VERSION "dbc-export 1 2025.20.8"

NS_ :

BS_:

BU_: ADSP APB APP APS APSB BB BMS CC CMP CP DAS DI DIF DIR DPB EPAS3P EPAS3S EPASTP EPASTS EPBL EPBR ESP GTW HVP IBST ICR IDB OCS1P PCS PM PMF PMR PTC RCM RCM2 RCU SCCM SDCR TAS TCU TRCM UI UIS UMC USM VC VCFRONT VCLEFT VCRIGHT VCSEC

BO_ 946 BMS_log2: 8 BMS
 SG_ BMS_log2MuxId M : 0|7@1+ (1,0) [0|127] "" Vector__XXX
 SG_ BMS_cacAvg m0 : 8|13@1+ (0.1,0) [0|819.1] "Ah" Vector__XXX
 SG_ BMS_cacMin m0 : 24|13@1+ (0.1,0) [0|819.1] "Ah" Vector__XXX
 SG_ BMS_cacMinBrickId m0 : 37|7@1+ (1,1) [1|128] "" Vector__XXX
 SG_ BMS_cacMax m0 : 44|13@1+ (0.1,0) [0|819.1] "Ah" Vector__XXX
 SG_ BMS_cacMaxBrickId m0 : 57|7@1+ (1,1) [1|128] "" Vector__XXX
 SG_ BMS_acRippleConfigNvramValid m18 : 7|1@1+ (1,0) [0|1] "" Vector__XXX
 SG_ BMS_hvChain_useLeakyBucket m18 : 8|1@1+ (1,0) [0|1] "" Vector__XXX
 SG_ BMS_hvChain_iLimit m18 : 9|14@1+ (0.2,0) [0|3275] "A" Vector__XXX
 SG_ BMS_hvChain_limitingState m18 : 23|9@1+ (1,1) [1|511] "" Vector__XXX
 SG_ BMS_hvChain_limitingStateTempera m18 : 32|13@1- (0.1,367.6) [-40|775] "DegC" Vector__XXX
 SG_ BMS_acRippleIsSupported m18 : 45|1@1+ (1,0) [0|1] "" Vector__XXX
 SG_ BMS_acRippleStartTemperatureMax m18 : 46|9@1+ (0.25,-25) [-25|100] "DegC" Vector__XXX
 SG_ BMS_acRippleStartTemperatureMin m18 : 55|9@1+ (0.25,-25) [-25|100] "DegC" Vector__XXX
 SG_ BMS_fcLinkTestDecayTime m20 : 8|10@1+ (2,0) [0|2044] "mS" Vector__XXX
 SG_ BMS_fcLinkTestTimeSinceLastRun m20 : 18|12@1+ (0.0175824183971,0) [0|71.99] "Hours" Vector__XXX
 SG_ BMS_pcsPrechargeRequestActive m20 : 30|1@1+ (1,0) [0|1] "" Vector__XXX
 SG_ BMS_pcsPrechargeTargetVoltage m20 : 32|16@1- (0.1,0) [-3276.8|3276.7] "V" Vector__XXX
 SG_ BMS_recentOvUvAlert m20 : 48|1@1+ (1,0) [0|1] "" Vector__XXX
 SG_ BMS_recentIsoAlert m20 : 49|1@1+ (1,0) [0|1] "" Vector__XXX
 SG_ BMS_recentBmbMiaAlert m20 : 50|1@1+ (1,0) [0|1] "" Vector__XXX
 SG_ BMS_cacBlendingConfigNvramValid m20 : 51|1@1+ (1,0) [0|1] "" Vector__XXX
 SG_ BMS_cacBlendingEnabled m20 : 52|1@1+ (1,0) [0|1] "" Vector__XXX
 SG_ BMS_cacBlendPercentPerCycle m20 : 53|10@1+ (0.001,0) [0|1.023] "%" Vector__XXX
 SG_ BMS_energyVariableChgRequested m21 : 8|1@1+ (1,0) [0|1] "" Vector__XXX
 SG_ BMS_packRestTime m21 : 9|12@1+ (0.0175824183971,0) [0|71.99] "Hours" Vector__XXX
 SG_ BMS_idealEnergyFloor m21 : 21|10@1+ (0.1,0) [0|102.2] "KWh" Vector__XXX
 SG_ BMS_thmGradientSlopeCondition m21 : 31|1@1+ (1,0) [0|1] "" Vector__XXX
 SG_ BMS_recentSlopeConditon m21 : 32|1@1+ (1,0) [0|1] "" Vector__XXX
 SG_ BMS_dynamicEnergyBuffer m21 : 33|10@1+ (0.1,0) [0|102.2] "KWh" Vector__XXX
 SG_ BMS_temperatureCondition m21 : 43|1@1+ (1,0) [0|1] "" Vector__XXX
 SG_ BMS_thmGradientSlope m21 : 44|10@1- (0.01,0) [-5.12|5.11] "C/min" Vector__XXX
 SG_ BMS_thmGradient m21 : 56|8@1+ (0.1,0) [0|25.5] "C" Vector__XXX
 SG_ BMS_dSocNormalizedMin m33 : 8|12@1+ (0.0030517578125,-12.4969482422) [-12.4969482422|-0.003051757825] "%" Vector__XXX
 SG_ BMS_dSocNormalizedFiltMin m33 : 20|12@1+ (0.0030517578125,-12.4969482422) [-12.4969482422|-0.003051757825] "%" Vector__XXX
 SG_ BMS_dSocMinAlpha m33 : 32|12@1+ (0.0030517578125,-12.4969482422) [-12.4969482422|-0.003051757825] "%" Vector__XXX
 SG_ BMS_dSocMaxLowAlphaCounter m33 : 44|4@1+ (1,0) [0|15] "" Vector__XXX
 SG_ BMS_dSocMinAlphaBrickID m33 : 48|7@1+ (1,1) [1|128] "" Vector__XXX
 SG_ BMS_dSocCacMargin m33 : 55|9@1+ (0.0030517578125,0) [0|1.55639648438] "%" Vector__XXX
 SG_ BMS_lifeModelAvgTempSeverity m55 : 8|5@1+ (0.1,0) [0|3] "-" Vector__XXX
 SG_ BMS_lifeModelDepthOfDischargeSev m55 : 16|8@1+ (0.01,0) [0|1.5] "-" Vector__XXX
 SG_ BMS_lifeModelHistogramCapacityLo m55 : 24|9@1+ (0.1,0) [0|51] "%" Vector__XXX
 SG_ BMS_lifeModelHistogramBrickCapac m55 : 33|13@1+ (0.1,0) [0|819] "Ah" Vector__XXX
 SG_ BMS_lifeModelDcrGrowthPercent m55 : 48|14@1- (0.1,200) [-100|500] "%" Vector__XXX
 SG_ BMS_nominalFullPackEnergyRaw m56 : 8|16@1+ (0.02,0) [0|1310.68] "kWh" Vector__XXX
 SG_ BMS_userChargeCalibratingReason m56 : 24|2@1+ (1,0) [0|3] "" Vector__XXX
 SG_ BMS_nominalEnergyRemainingBuffer m56 : 32|16@1+ (0.02,0) [0|1310.68] "kWh" Vector__XXX
 SG_ BMS_idealEnergyRemainingBuffered m56 : 48|16@1+ (0.02,0) [0|1310.68] "kWh" Vector__XXX
 SG_ BMS_largestCacSpreadErrorLower m64 : 8|12@1+ (0.1,0) [0|409.4] "Ah" Vector__XXX
 SG_ BMS_lifeModelAverageCac m64 : 20|12@1+ (0.1,0) [0|409.4] "Ah" Vector__XXX
 SG_ BMS_lifeModelCacBrick1 m64 : 32|12@1+ (0.1,0) [0|409.4] "Ah" Vector__XXX
 SG_ BMS_lifeModelAverageOffset m64 : 44|10@1- (0.1,0) [-51.1|51.1] "Ah" Vector__XXX
 SG_ BMS_percentCacUpdatesInTimeWindo m64 : 54|10@1+ (0.1,0) [0|100] "%" Vector__XXX
 SG_ BMS_lifeModelMaxCacBrickId m65 : 8|8@1+ (1,1) [1|255] "" Vector__XXX
 SG_ BMS_lifeModelMaxCac m65 : 16|12@1+ (0.1,0) [0|409.4] "Ah" Vector__XXX
 SG_ BMS_lifeModelMinCacBrickId m65 : 28|8@1+ (1,1) [1|255] "" Vector__XXX
 SG_ BMS_lifeModelMinCac m65 : 36|12@1+ (0.1,0) [0|409.4] "Ah" Vector__XXX
 SG_ BMS_restingPointCacAvg m65 : 48|12@1+ (0.1,0) [0|409.4] "Ah" Vector__XXX
 SG_ BMS_cacEstimationSource m65 : 60|2@1+ (1,0) [0|3] "" Vector__XXX
 SG_ BMS_synchronizedCacMaxRaw m71 : 8|12@1+ (0.1,0) [0|409.4] "Ah" Vector__XXX
 SG_ BMS_synchronizedCacMinRaw m71 : 20|12@1+ (0.1,0) [0|409.4] "Ah" Vector__XXX
 SG_ BMS_largestSyncCacErrorStartSoc m71 : 32|10@1+ (0.1,0) [0|102.2] "%" Vector__XXX
 SG_ BMS_largestSyncCacErrorEndSoc m71 : 42|10@1+ (0.1,0) [0|102.2] "%" Vector__XXX
 SG_ BMS_runtimeSocConfigNvramValid m71 : 52|1@1+ (1,0) [0|1] "" Vector__XXX
 SG_ BMS_runtimeSocCorrectionsEnabled m71 : 53|1@1+ (1,0) [0|1] "" Vector__XXX
 SG_ BMS_rubberBandingEnabled m71 : 54|1@1+ (1,0) [0|1] "" Vector__XXX
 SG_ BMS_rubberBandingConfigNvramVali m71 : 55|1@1+ (1,0) [0|1] "" Vector__XXX
 SG_ BMS_runtimeSocMinTempForModel m71 : 56|6@1+ (0.5,0) [0|20] "DegC" Vector__XXX
 SG_ BMS_energyBufferConfigNvramValid m71 : 62|1@1+ (1,0) [0|1] "" Vector__XXX
 SG_ BMS_thermalEvent1pDetectConfigDi m71 : 63|1@1+ (1,0) [0|1] "" Vector__XXX
 SG_ BMS_sohEnergy m79 : 8|11@1+ (0.1,0) [0|204.6] "KWh" Vector__XXX
 SG_ BMS_fullCapacitySohEnergy m79 : 19|11@1+ (0.1,0) [0|204.6] "KWh" Vector__XXX
 SG_ BMS_calibratedCapacitySohEnergy m79 : 30|11@1+ (0.1,0) [0|204.6] "KWh" Vector__XXX
 SG_ BMS_estimatedCapacitySohEnergy m79 : 41|11@1+ (0.1,0) [0|204.6] "KWh" Vector__XXX
 SG_ BMS_prevUserFacingSohEnergy m79 : 52|11@1+ (0.1,0) [0|204.6] "KWh" Vector__XXX
 SG_ BMS_stateOfHealthMinCac m80 : 8|13@1+ (0.1,0) [0|819] "Ah" Vector__XXX
 SG_ BMS_lifeModelStorageLossPackAge m80 : 24|14@1+ (1,0) [0|16382] "days" Vector__XXX
 SG_ BMS_lifeModelThroughputCycleCoun m80 : 40|12@1+ (1,0) [0|4094] "Cycles" Vector__XXX
 SG_ BMS_lifeModelThroughputDcrCycleC m80 : 52|12@1+ (1,0) [0|4094] "Cycles" Vector__XXX
 SG_ BMS_energyWalkCounter m83 : 8|8@1+ (1,0) [0|255] "" Vector__XXX
 SG_ BMS_energyWalkTimeoutCounter m83 : 16|8@1+ (1,0) [0|255] "" Vector__XXX
 SG_ BMS_dynamicCcvEnabled m83 : 24|1@1+ (1,0) [0|1] "" Vector__XXX
 SG_ BMS_chargeTargetLookupSoc m83 : 32|10@1+ (0.1,0) [0|102.2] "%" Vector__XXX
 SG_ BMS_stateOfHealth m83 : 42|10@1+ (0.1,0) [0|100] "%" Vector__XXX

BO_ 914 BMS_packConfig: 8 BMS
 SG_ BMS_packConfigMultiplexer M : 0|8@1+ (1,0) [0|255] "" Vector__XXX
 SG_ BMS_reservedConfig_0 m0 : 8|5@1+ (1,0) [0|31] "" Vector__XXX
 SG_ BMS_moduleType m1 : 8|3@1+ (1,0) [0|7] "" Vector__XXX
 SG_ BMS_thermalPackType m1 : 11|4@1+ (1,0) [0|15] "" Vector__XXX
 SG_ BMS_packMass m1 : 16|8@1+ (1,300) [342|540] "kg" Vector__XXX
 SG_ BMS_platformMaxBusVoltage m1 : 24|10@1+ (1,300) [300|1300] "V" Vector__XXX
 SG_ BMS_standbySupplyContinuousPower m1 : 36|2@1+ (1,0) [0|3] "" Vector__XXX

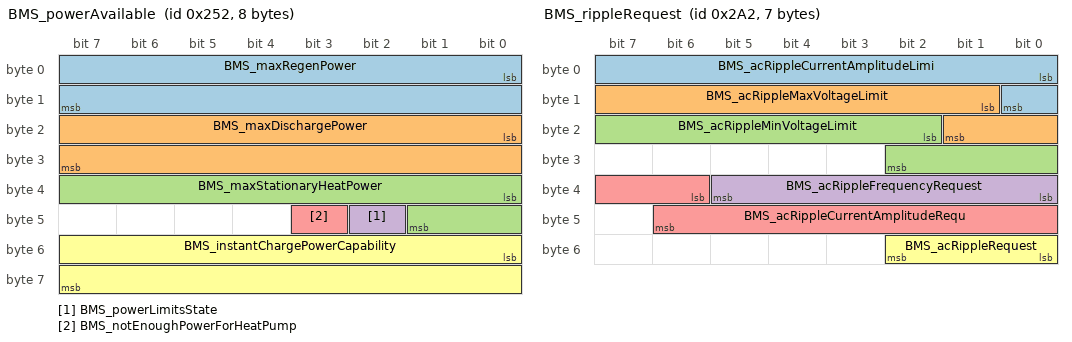
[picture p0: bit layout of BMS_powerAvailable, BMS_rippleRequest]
BO_ 594 BMS_powerAvailable: 8 BMS
 SG_ BMS_maxRegenPower : 0|16@1+ (0.01,0) [0|655.35] "kW" Vector__XXX
 SG_ BMS_maxDischargePower : 16|16@1+ (0.013,0) [0|850] "kW" Vector__XXX
 SG_ BMS_maxStationaryHeatPower : 32|10@1+ (0.01,0) [0|10.23] "kW" Vector__XXX
 SG_ BMS_powerLimitsState : 42|1@1+ (1,0) [0|1] "" Vector__XXX
 SG_ BMS_notEnoughPowerForHeatPump : 43|1@1+ (1,0) [0|1] "" Vector__XXX
 SG_ BMS_instantChargePowerCapability : 48|16@1+ (0.05,0) [0|3276.7] "kW" Vector__XXX

BO_ 674 BMS_rippleRequest: 7 BMS
 SG_ BMS_acRippleCurrentAmplitudeLimi : 0|9@1+ (1,0) [0|511] "A" Vector__XXX
 SG_ BMS_acRippleMaxVoltageLimit : 9|9@1+ (1,0) [0|511] "V" Vector__XXX
 SG_ BMS_acRippleMinVoltageLimit : 18|9@1+ (1,0) [0|511] "V" Vector__XXX
 SG_ BMS_acRippleFrequencyRequest : 32|6@1+ (1,80) [80|142] "Hz" Vector__XXX
 SG_ BMS_acRippleCurrentAmplitudeRequ : 38|9@1+ (1,0) [0|511] "A" Vector__XXX
 SG_ BMS_acRippleRequest : 48|3@1+ (1,0) [0|7] "" Vector__XXX

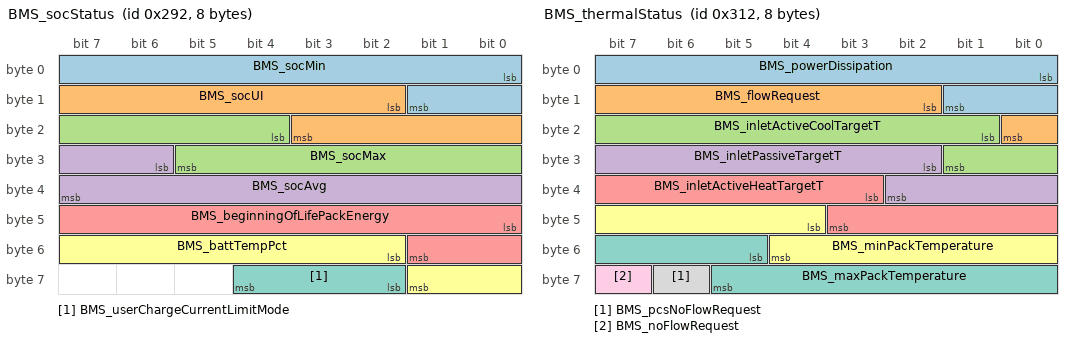
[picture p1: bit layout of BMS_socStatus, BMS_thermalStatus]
BO_ 658 BMS_socStatus: 8 BMS
 SG_ BMS_socMin : 0|10@1+ (0.1,0) [0|102.2] "%" Vector__XXX
 SG_ BMS_socUI : 10|10@1+ (0.1,0) [0|100] "%" Vector__XXX
 SG_ BMS_socMax : 20|10@1+ (0.1,0) [0|102.2] "%" Vector__XXX
 SG_ BMS_socAvg : 30|10@1+ (0.1,0) [0|102.2] "%" Vector__XXX
 SG_ BMS_beginningOfLifePackEnergy : 40|10@1+ (0.1,0) [0|102.2] "KWh" Vector__XXX
 SG_ BMS_battTempPct : 50|8@1+ (0.4,0) [0|100] "%" Vector__XXX
 SG_ BMS_userChargeCurrentLimitMode : 58|3@1+ (1,0) [0|7] "" Vector__XXX

BO_ 530 BMS_status: 8 BMS
 SG_ BMS_hvacPowerRequest : 0|1@1+ (1,0) [0|1] "" Vector__XXX
 SG_ BMS_notEnoughPowerForDrive : 1|1@1+ (1,0) [0|1] "" Vector__XXX
 SG_ BMS_notEnoughPowerForSupport : 2|1@1+ (1,0) [0|1] "" Vector__XXX
 SG_ BMS_preconditionAllowed : 3|1@1+ (1,0) [0|1] "" Vector__XXX
 SG_ BMS_updateAllowed : 4|1@1+ (1,0) [0|1] "" Vector__XXX
 SG_ BMS_activeHeatingWorthwhile : 5|1@1+ (1,0) [0|1] "" Vector__XXX
 SG_ BMS_cpMiaOnHvs : 6|1@1+ (1,0) [0|1] "" Vector__XXX
 SG_ BMS_pcsPwmEnabled : 7|1@1+ (1,0) [0|1] "" Vector__XXX
 SG_ BMS_contactorState : 8|3@1+ (1,0) [1|7] "" Vector__XXX
 SG_ BMS_userChargeStatus : 11|3@1+ (1,0) [0|7] "" Vector__XXX
 SG_ BMS_totalBatteryPower : 14|17@1- (0.05,0) [-3276.8|3276.75] "kW" Vector__XXX
 SG_ BMS_chargeRequest : 31|1@1+ (1,0) [0|1] "" Vector__XXX
 SG_ BMS_state : 32|4@1+ (1,0) [0|15] "" Vector__XXX
 SG_ BMS_diLimpRequest : 37|1@1+ (1,0) [0|1] "" Vector__XXX
 SG_ BMS_okToShipByAir : 38|1@1+ (1,0) [0|1] "" Vector__XXX
 SG_ BMS_okToShipByLand : 39|1@1+ (1,0) [0|1] "" Vector__XXX
 SG_ BMS_chgPowerAvailable : 40|12@1+ (0.125,0) [0|511.75] "kW" Vector__XXX
 SG_ BMS_chargeRetryCount : 53|3@1+ (1,0) [0|7] "" Vector__XXX
 SG_ BMS_conditioningRequest : 56|1@1+ (1,0) [0|1] "" Vector__XXX
 SG_ BMS_smStateRequest : 57|4@1+ (1,0) [0|15] "" Vector__XXX
 SG_ BMS_hvState : 61|3@1+ (1,0) [0|7] "" Vector__XXX

BO_ 786 BMS_thermalStatus: 8 BMS
 SG_ BMS_powerDissipation : 0|10@1+ (0.02,0) [0|20] "kW" Vector__XXX
 SG_ BMS_flowRequest : 10|7@1+ (0.3,0) [0|38.1] "LPM" Vector__XXX
 SG_ BMS_inletActiveCoolTargetT : 17|9@1+ (0.25,-25) [-25|100] "DegC" Vector__XXX
 SG_ BMS_inletPassiveTargetT : 26|9@1+ (0.25,-25) [-25|100] "DegC" Vector__XXX
 SG_ BMS_inletActiveHeatTargetT : 35|9@1+ (0.25,-25) [-25|100] "DegC" Vector__XXX
 SG_ BMS_minPackTemperature : 44|9@1+ (0.25,-25) [-25|102.75] "DegC" Vector__XXX
 SG_ BMS_maxPackTemperature : 53|9@1+ (0.25,-25) [-25|102.75] "DegC" Vector__XXX
 SG_ BMS_pcsNoFlowRequest : 62|1@1+ (1,0) [0|1] "" Vector__XXX
 SG_ BMS_noFlowRequest : 63|1@1+ (1,0) [0|1] "" Vector__XXX

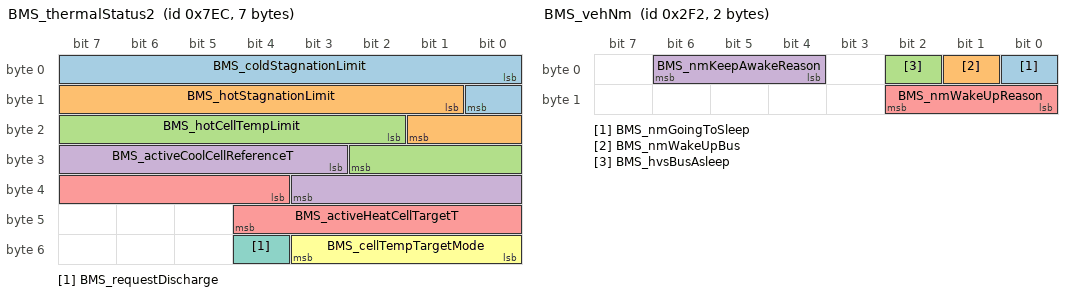
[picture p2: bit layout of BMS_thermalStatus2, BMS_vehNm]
BO_ 2028 BMS_thermalStatus2: 7 BMS
 SG_ BMS_coldStagnationLimit : 0|9@1+ (0.25,-25) [-25|100] "DegC" Vector__XXX
 SG_ BMS_hotStagnationLimit : 9|9@1+ (0.25,-25) [-25|100] "DegC" Vector__XXX
 SG_ BMS_hotCellTempLimit : 18|9@1+ (0.25,-25) [-25|100] "DegC" Vector__XXX
 SG_ BMS_activeCoolCellReferenceT : 27|9@1+ (0.25,-25) [-25|100] "DegC" Vector__XXX
 SG_ BMS_activeHeatCellTargetT : 36|9@1+ (0.25,-25) [-25|100] "DegC" Vector__XXX
 SG_ BMS_cellTempTargetMode : 48|4@1+ (1,0) [0|15] "" Vector__XXX
 SG_ BMS_requestDischarge : 52|1@1+ (1,0) [0|1] "" Vector__XXX

BO_ 754 BMS_vehNm: 2 BMS
 SG_ BMS_nmGoingToSleep : 0|1@1+ (1,0) [0|1] "" Vector__XXX
 SG_ BMS_nmWakeUpBus : 1|1@1+ (1,0) [0|1] "" Vector__XXX
 SG_ BMS_hvsBusAsleep : 2|1@1+ (1,0) [0|1] "" Vector__XXX
 SG_ BMS_nmKeepAwakeReason : 4|3@1+ (1,0) [1|7] "" Vector__XXX
 SG_ BMS_nmWakeUpReason : 8|3@1+ (1,0) [0|7] "" Vector__XXX

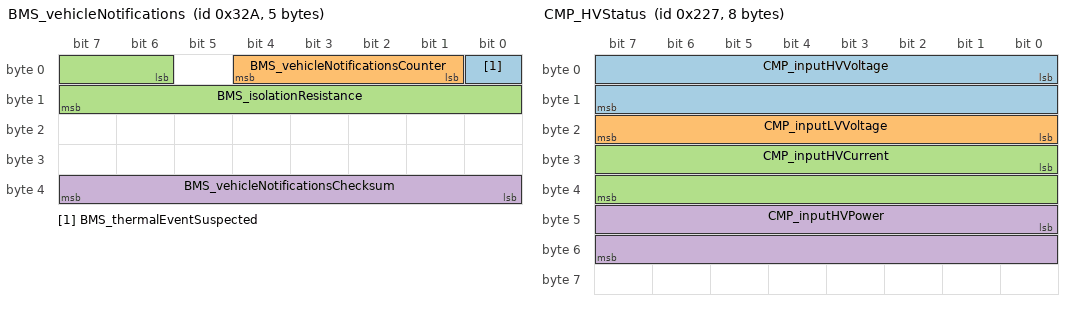
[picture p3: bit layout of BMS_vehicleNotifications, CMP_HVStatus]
BO_ 810 BMS_vehicleNotifications: 5 BMS
 SG_ BMS_thermalEventSuspected : 0|1@1+ (1,0) [0|1] "" Vector__XXX
 SG_ BMS_vehicleNotificationsCounter : 1|4@1+ (1,0) [0|15] "" Vector__XXX
 SG_ BMS_isolationResistance : 6|10@1+ (10,0) [0|10000] "kOhm" Vector__XXX
 SG_ BMS_vehicleNotificationsChecksum : 32|8@1+ (1,0) [0|255] "" Vector__XXX

BO_ 797 CC_chgStatus2: 8 CC
 SG_ CC_chgStatus2Index M : 0|8@1+ (1,0) [0|255] "" Vector__XXX
 SG_ CC_buttonState m0 : 8|1@1+ (1,0) [0|1] "" Vector__XXX

BO_ 551 CMP_HVStatus: 8 CMP
 SG_ CMP_inputHVVoltage : 0|16@1+ (0.1,0) [0|6553.4] "V" Vector__XXX
 SG_ CMP_inputLVVoltage : 16|8@1+ (0.1,0) [0|25.5] "V" Vector__XXX
 SG_ CMP_inputHVCurrent : 24|16@1+ (0.1,0) [0|6553.4] "A" Vector__XXX
 SG_ CMP_inputHVPower : 40|16@1+ (1,0) [0|65534] "W" Vector__XXX

BO_ 1294 CP_alertLog: 8 CP
 SG_ CP_alertID M : 0|15@1+ (1,0) [0|32767] "" Vector__XXX
 SG_ CP_alertType : 15|1@1+ (1,0) [0|1] "" Vector__XXX
 SG_ CP_a004_proximityV m4 : 16|16@1+ (0.0001,0) [0|6.5535] "V" Vector__XXX
 SG_ CP_a004_cc1Voltage m4 : 32|14@1+ (0.001,0) [0|16.383] "V" Vector__XXX
 SG_ CP_a004_cc2Voltage m4 : 48|14@1+ (0.001,0) [0|16.383] "V" Vector__XXX
 SG_ CP_a005_cc1Voltage m5 : 16|11@1+ (0.00649731326848,0) [0|13.3000002606] "V" Vector__XXX
 SG_ CP_a005_cc2Voltage m5 : 27|9@1+ (0.009784736,0) [0|5.000000096] "V" Vector__XXX
 SG_ CP_a005_gbdcState m5 : 36|4@1+ (1,0) [0|15] "" Vector__XXX
 SG_ CP_a005_packCurrent m5 : 40|12@1+ (0.0976801,0) [0|400.0000095] "A" Vector__XXX
 SG_ CP_a005_evseCurrent m5 : 52|10@1+ (0.391006857157,0) [0|400.000014872] "A" Vector__XXX
 SG_ CP_a005_superchargerConnected m5 : 62|1@1+ (1,0) [0|1] "" Vector__XXX
 SG_ CP_a005_latchEngaged m5 : 63|1@1+ (1,0) [0|1] "" Vector__XXX
 SG_ CP_a006_BMS_FC_limits_MIA m6 : 16|1@1+ (1,0) [0|1] "" Vector__XXX
 SG_ CP_a006_BMS_chargeStatus_MIA m6 : 17|1@1+ (1,0) [0|1] "" Vector__XXX
 SG_ CP_a006_BMS_dcChargeLimits_MIA m6 : 18|1@1+ (1,0) [0|1] "" Vector__XXX
 SG_ CP_a006_BMS_hvPackStatus_MIA m6 : 19|1@1+ (1,0) [0|1] "" Vector__XXX
 SG_ CP_a006_BMS_kwhCounter_MIA m6 : 20|1@1+ (1,0) [0|1] "" Vector__XXX
 SG_ CP_a006_BMS_socStatus_MIA m6 : 21|1@1+ (1,0) [0|1] "" Vector__XXX
 SG_ CP_a008_data1 m8 : 16|16@1+ (1,0) [0|65535] "" Vector__XXX
 SG_ CP_a008_data2 m8 : 32|16@1+ (1,0) [0|65535] "" Vector__XXX
 SG_ CP_a008_FlashWarning m8 : 48|1@1+ (1,0) [0|1] "" Vector__XXX
 SG_ CP_a008_RAMconst_Warning m8 : 49|1@1+ (1,0) [0|1] "" Vector__XXX
 SG_ CP_a008_RAMconst_Fault m8 : 50|1@1+ (1,0) [0|1] "" Vector__XXX
 SG_ CP_a008_AllMemory_warnings m8 : 51|1@1+ (1,0) [0|1] "" Vector__XXX
 SG_ CP_a008_StackAlert m8 : 52|1@1+ (1,0) [0|1] "" Vector__XXX
 SG_ CP_a008_stackUsed m8 : 56|7@1+ (1,0) [0|127] "%" Vector__XXX
 SG_ CP_a009_cover1OpenCounts m9 : 16|12@1+ (0.025,0) [0|102.375] "%" Vector__XXX
 SG_ CP_a009_cover2OpenCounts m9 : 28|12@1+ (0.025,0) [0|102.375] "%" Vector__XXX
 SG_ CP_a009_cover1State m9 : 40|3@1+ (1,0) [0|7] "" Vector__XXX
 SG_ CP_a009_cover2State m9 : 43|3@1+ (1,0) [0|7] "" Vector__XXX
 SG_ CP_a010_periodValid m10 : 16|1@1+ (1,0) [0|1] "" Vector__XXX
 SG_ CP_a010_widthValid m10 : 17|1@1+ (1,0) [0|1] "" Vector__XXX
 SG_ CP_a010_voltageValid m10 : 18|1@1+ (1,0) [0|1] "" Vector__XXX
 SG_ CP_a010_pilotHigh m10 : 19|12@1- (0.008,0) [-16.384|16.376] "V" Vector__XXX
 SG_ CP_a010_pilotLow m10 : 32|12@1- (0.008,0) [-16.384|16.376] "V" Vector__XXX
 SG_ CP_a010_evseAccept m10 : 44|1@1+ (1,0) [0|1] "" Vector__XXX
 SG_ CP_a010_pilotPWMdetected m10 : 45|1@1+ (1,0) [0|1] "" Vector__XXX
 SG_ CP_a011_eepromErrorType m11 : 16|3@1+ (1,0) [0|7] "" Vector__XXX
 SG_ CP_a015_apsVoltageOV m15 : 16|8@1+ (0.07128516,0) [0|18.1777158] "V" Vector__XXX
 SG_ CP_a016_apsVoltageUV m16 : 16|8@1+ (0.07128516,0) [0|18.1777158] "V" Vector__XXX
 SG_ CP_a017_5V_VoltageOV m17 : 16|8@1+ (0.02352539,0) [0|5.99897445] "V" Vector__XXX
 SG_ CP_a018_5V_VoltageUV m18 : 16|8@1+ (0.02352539,0) [0|5.99897445] "V" Vector__XXX
 SG_ CP_a023_stopChargeReason m23 : 16|4@1+ (1,0) [0|15] "" Vector__XXX
 SG_ CP_a023_failureReason m23 : 20|2@1+ (1,0) [0|3] "" Vector__XXX
 SG_ CP_a023_chargeAttempts m23 : 24|3@1+ (1,0) [0|7] "" Vector__XXX
 SG_ CP_a028_canEnable m28 : 16|1@1+ (1,0) [0|1] "" Vector__XXX
 SG_ CP_a028_hardlineEnable m28 : 17|1@1+ (1,0) [0|1] "" Vector__XXX
 SG_ CP_a029_CP_pilot m29 : 16|3@1+ (1,0) [0|6] "" Vector__XXX
 SG_ CP_a029_CP_proximity m29 : 19|2@1+ (1,0) [1|3] "" Vector__XXX
 SG_ CP_a029_CP_chargeDoorOpen m29 : 21|1@1+ (1,0) [0|1] "" Vector__XXX
 SG_ CP_a031_apsVoltage m31 : 16|8@1+ (0.07156863,0) [0|18.25000065] "V" Vector__XXX
 SG_ CP_a031_doorCountsFiltered m31 : 24|12@1+ (0.025,0) [0|102.375] "%" Vector__XXX
 SG_ CP_a031_inductiveSensorFiltered m31 : 36|18@1+ (82.77924,0) [0|21699998.3113] "Hz" Vector__XXX
 SG_ CP_a031_hallSensorFiltered m31 : 54|10@1+ (0.00488748773932,0) [0|4.99989995732] "V" Vector__XXX
 SG_ CP_a032_apsVoltage m32 : 16|8@1+ (0.07156863,0) [0|18.25000065] "V" Vector__XXX
 SG_ CP_a032_doorCountsFiltered m32 : 24|12@1+ (0.025,0) [0|102.375] "%" Vector__XXX
 SG_ CP_a032_inductiveSensorFiltered m32 : 36|18@1+ (82.77924,0) [0|21699998.3113] "Hz" Vector__XXX
 SG_ CP_a032_hallSensorFiltered m32 : 54|10@1+ (0.00488748773932,0) [0|4.99989995732] "V" Vector__XXX
 SG_ CP_a035_latchState m35 : 16|2@1+ (1,0) [1|3] "" Vector__XXX
 SG_ CP_a035_stateLeverMovedFrom m35 : 18|2@1+ (1,0) [0|3] "" Vector__XXX
 SG_ CP_a035_latchOffset m35 : 24|16@1- (0.003051851,0) [-100.003053568|100.000001717] "%" Vector__XXX
 SG_ CP_a035_inletID m35 : 40|2@1+ (1,0) [0|3] "" Vector__XXX
 SG_ CP_a036_latchCountsFiltered m36 : 16|16@1+ (0.00152590218931,0) [0|99.9999999764] "%" Vector__XXX
 SG_ CP_a036_latchState m36 : 32|2@1+ (1,0) [1|3] "" Vector__XXX
 SG_ CP_a036_CHG_InsertEnable m36 : 34|1@1+ (1,0) [0|1] "" Vector__XXX
 SG_ CP_a036_CP_latchEnableCmd m36 : 35|1@1+ (1,0) [0|1] "" Vector__XXX
 SG_ CP_a036_CP_apsVoltage m36 : 40|8@1+ (0.07156863,0) [0|18.25000065] "V" Vector__XXX
 SG_ CP_a036_inletID m36 : 48|2@1+ (1,0) [0|3] "" Vector__XXX
 SG_ CP_a037_latchCountsFiltered m37 : 16|16@1+ (0.00152590218931,0) [0|99.9999999764] "%" Vector__XXX
 SG_ CP_a037_latchState m37 : 32|2@1+ (1,0) [1|3] "" Vector__XXX
 SG_ CP_a037_CHG_InsertEnable m37 : 34|1@1+ (1,0) [0|1] "" Vector__XXX
 SG_ CP_a037_CP_latchEnableCmd m37 : 35|1@1+ (1,0) [0|1] "" Vector__XXX
 SG_ CP_a037_CP_apsVoltage m37 : 40|8@1+ (0.07156863,0) [0|18.25000065] "V" Vector__XXX
 SG_ CP_a037_inletID m37 : 48|2@1+ (1,0) [0|3] "" Vector__XXX
 SG_ CP_a038_latchCountsFiltered m38 : 16|16@1+ (0.00152590218931,0) [0|99.9999999764] "%" Vector__XXX
 SG_ CP_a038_latchState m38 : 32|2@1+ (1,0) [1|3] "" Vector__XXX
 SG_ CP_a038_CHG_InsertEnable m38 : 34|1@1+ (1,0) [0|1] "" Vector__XXX
 SG_ CP_a038_CP_latchEnableCmd m38 : 35|1@1+ (1,0) [0|1] "" Vector__XXX
 SG_ CP_a038_CP_apsVoltage m38 : 40|8@1+ (0.07156863,0) [0|18.25000065] "V" Vector__XXX
 SG_ CP_a038_inletID m38 : 48|2@1+ (1,0) [0|3] "" Vector__XXX
 SG_ CP_a041_doorCounts m41 : 16|16@1+ (0.002,0) [0|131.07] "%" Vector__XXX
 SG_ CP_a041_inductiveSensorFiltered m41 : 32|18@1+ (82.77924,0) [0|21699998.3113] "Hz" Vector__XXX
 SG_ CP_a041_hallSensorFiltered m41 : 50|10@1+ (0.00488748773932,0) [0|4.99989995732] "V" Vector__XXX
 SG_ CP_a042_doorCounts m42 : 16|16@1+ (0.002,0) [0|131.07] "%" Vector__XXX
 SG_ CP_a042_inductiveSensorFiltered m42 : 32|18@1+ (82.77924,0) [0|21699998.3113] "Hz" Vector__XXX
 SG_ CP_a042_hallSensorFiltered m42 : 50|10@1+ (0.00488748773932,0) [0|4.99989995732] "V" Vector__XXX
 SG_ CP_a043_driftFlag m43 : 16|1@1+ (1,0) [0|1] "" Vector__XXX
 SG_ CP_a043_wrongDirectionFlag m43 : 17|1@1+ (1,0) [0|1] "" Vector__XXX
 SG_ CP_a043_outOfRangeFlag m43 : 18|1@1+ (1,0) [0|1] "" Vector__XXX
 SG_ CP_a043_doorPotFiltered m43 : 19|12@1+ (0.025,0) [0|102.375] "%" Vector__XXX
 SG_ CP_a043_doorVelocity m43 : 32|12@1- (0.5,0) [-1024|1023.5] "%/s" Vector__XXX
 SG_ CP_a043_idleDoorPot m43 : 44|12@1+ (0.025,0) [0|102.375] "%" Vector__XXX
 SG_ CP_a044_HVP_cpControl_MIA m44 : 16|1@1+ (1,0) [0|1] "" Vector__XXX
 SG_ CP_a045_VCSEC_authentication_MIA m45 : 16|1@1+ (1,0) [0|1] "" Vector__XXX
 SG_ CP_a045_VCSEC_requests_MIA m45 : 17|1@1+ (1,0) [0|1] "" Vector__XXX
 SG_ CP_a046_FC_status_flag m46 : 16|1@1+ (1,0) [0|1] "" Vector__XXX
 SG_ CP_a046_FC_limits_flag m46 : 17|1@1+ (1,0) [0|1] "" Vector__XXX
 SG_ CP_a046_FC_maxLimits_flag m46 : 18|1@1+ (1,0) [0|1] "" Vector__XXX
 SG_ CP_a046_FC_statusHighPower_flag m46 : 19|1@1+ (1,0) [0|1] "" Vector__XXX
 SG_ CP_a046_FC_limitsHighPower_flag m46 : 20|1@1+ (1,0) [0|1] "" Vector__XXX
 SG_ CP_a046_FC_maxLimitsHighPower m46 : 21|1@1+ (1,0) [0|1] "" Vector__XXX
 SG_ CP_a046_CC_chgStatus_flag m46 : 22|1@1+ (1,0) [0|1] "" Vector__XXX
 SG_ CP_a047_okToUseHighPower_MIA m47 : 16|1@1+ (1,0) [0|1] "" Vector__XXX
 SG_ CP_a047_LVPowerState_MIA m47 : 17|1@1+ (1,0) [0|1] "" Vector__XXX
 SG_ CP_a047_sensors_MIA m47 : 18|1@1+ (1,0) [0|1] "" Vector__XXX
 SG_ CP_a047_vehNm_MIA m47 : 19|1@1+ (1,0) [0|1] "" Vector__XXX
 SG_ CP_a048_UI_chargeRequest_MIA m48 : 16|1@1+ (1,0) [0|1] "" Vector__XXX
 SG_ CP_a048_UI_range_MIA m48 : 17|1@1+ (1,0) [0|1] "" Vector__XXX
 SG_ CP_a048_UI_status_MIA m48 : 18|1@1+ (1,0) [0|1] "" Vector__XXX
 SG_ CP_a048_UI_vehicleModes_MIA m48 : 19|1@1+ (1,0) [0|1] "" Vector__XXX
 SG_ CP_a048_UI_hvacRequest_MIA m48 : 20|1@1+ (1,0) [0|1] "" Vector__XXX
 SG_ CP_a048_VEH_billing_MIA m48 : 21|1@1+ (1,0) [0|1] "" Vector__XXX
 SG_ CP_a049_proximity m49 : 16|2@1+ (1,0) [1|3] "" Vector__XXX
 SG_ CP_a050_latch1NotConnected m50 : 16|1@1+ (1,0) [0|1] "" Vector__XXX
 SG_ CP_a050_latch2NotConnected m50 : 17|1@1+ (1,0) [0|1] "" Vector__XXX
 SG_ CP_a051_doorCountsFiltered m51 : 16|12@1+ (0.025,0) [0|102.375] "%" Vector__XXX
 SG_ CP_a054_latchCountsFiltered m54 : 16|16@1+ (0.00152590218931,0) [0|99.9999999764] "%" Vector__XXX
 SG_ CP_a054_latchState m54 : 32|2@1+ (1,0) [1|3] "" Vector__XXX
 SG_ CP_a054_CHG_InsertEnable m54 : 34|1@1+ (1,0) [0|1] "" Vector__XXX
 SG_ CP_a054_CP_latchEnableCmd m54 : 35|1@1+ (1,0) [0|1] "" Vector__XXX
 SG_ CP_a054_CP_apsVoltage m54 : 40|8@1+ (0.07156863,0) [0|18.25000065] "V" Vector__XXX
 SG_ CP_a054_CP_proximity m54 : 48|2@1+ (1,0) [1|3] "" Vector__XXX
 SG_ CP_a054_inletID m54 : 50|2@1+ (1,0) [0|3] "" Vector__XXX
 SG_ CP_a056_latchState m56 : 16|2@1+ (1,0) [1|3] "" Vector__XXX
 SG_ CP_a056_CHG_InsertEnable m56 : 18|1@1+ (1,0) [0|1] "" Vector__XXX
 SG_ CP_a056_CP_latchEnableCmd m56 : 19|1@1+ (1,0) [0|1] "" Vector__XXX
 SG_ CP_a056_CP_proximity m56 : 20|2@1+ (1,0) [1|3] "" Vector__XXX
 SG_ CP_a056_packCurrent m56 : 24|16@1- (0.1,0) [-3276.8|3276.7] "A" Vector__XXX
 SG_ CP_a058_CP_pilot m58 : 16|3@1+ (1,0) [0|6] "" Vector__XXX
 SG_ CP_a058_CC_pilot m58 : 19|2@1+ (1,0) [0|2] "" Vector__XXX
 SG_ CP_a058_FC_status m58 : 24|4@1+ (1,0) [1|15] "" Vector__XXX
 SG_ CP_a058_latchState m58 : 28|2@1+ (1,0) [1|3] "" Vector__XXX
 SG_ CP_a058_CP_proximity m58 : 30|2@1+ (1,0) [1|3] "" Vector__XXX
 SG_ CP_a058_acNumRetries m58 : 32|1@1+ (1,0) [0|1] "" Vector__XXX
 SG_ CP_a058_acRetryTimeoutS m58 : 33|15@1+ (1,0) [0|32767] "" Vector__XXX
 SG_ CP_a060_PCS_chgStatus_MIA m60 : 16|1@1+ (1,0) [0|1] "" Vector__XXX
 SG_ CP_a060_PCS_chgLineStatus_MIA m60 : 17|1@1+ (1,0) [0|1] "" Vector__XXX
 SG_ CP_a061_controlState m61 : 16|4@1+ (1,0) [0|15] "" Vector__XXX
 SG_ CP_a061_lastControlState m61 : 20|4@1+ (1,0) [0|15] "" Vector__XXX
 SG_ CP_a061_chipState m61 : 24|3@1+ (1,0) [0|7] "" Vector__XXX
 SG_ CP_a061_timeMsInControlState m61 : 32|16@1+ (1,0) [0|65535] "" Vector__XXX
 SG_ CP_a062_FC_status m62 : 16|4@1+ (1,0) [1|15] "" Vector__XXX
 SG_ CP_a062_FC_type m62 : 20|3@1+ (1,0) [0|6] "" Vector__XXX
 SG_ CP_a063_FC_status m63 : 16|4@1+ (1,0) [1|15] "" Vector__XXX
 SG_ CP_a063_FC_type m63 : 20|3@1+ (1,0) [0|6] "" Vector__XXX
 SG_ CP_a066_pilotHigh m66 : 16|12@1- (0.008,0) [-16.384|16.376] "V" Vector__XXX
 SG_ CP_a066_pilotLow m66 : 28|12@1- (0.008,0) [-16.384|16.376] "V" Vector__XXX
 SG_ CP_a066_proximity m66 : 40|2@1+ (1,0) [1|3] "" Vector__XXX
 SG_ CP_a067_cc1Voltage m67 : 16|14@1+ (0.001,0) [0|16.383] "V" Vector__XXX
 SG_ CP_a067_cc2Voltage m67 : 32|14@1+ (0.001,0) [0|16.383] "V" Vector__XXX
 SG_ CP_a068_doorCountsFiltered m68 : 16|12@1+ (0.025,0) [0|102.375] "%" Vector__XXX
 SG_ CP_a068_doorClosed m68 : 28|1@1+ (1,0) [0|1] "" Vector__XXX
 SG_ CP_a068_inductiveSensorFiltered m68 : 29|18@1+ (82.77924,0) [0|21699998.3113] "Hz" Vector__XXX
 SG_ CP_a068_hallSensorFiltered m68 : 48|10@1+ (0.00488748773932,0) [0|4.99989995732] "V" Vector__XXX
 SG_ CP_a068_doorPresent m68 : 58|1@1+ (1,0) [0|1] "" Vector__XXX
 SG_ CP_a069_inductiveSensor_raw m69 : 16|28@1+ (1,0) [0|268435455] "" Vector__XXX
 SG_ CP_a069_inductiveErrorAmplitude m69 : 44|1@1+ (1,0) [0|1] "" Vector__XXX
 SG_ CP_a069_inductiveErrorWatchdog m69 : 45|1@1+ (1,0) [0|1] "" Vector__XXX
 SG_ CP_a069_inductiveErrorOverRange m69 : 46|1@1+ (1,0) [0|1] "" Vector__XXX
 SG_ CP_a069_inductiveErrorUnderRange m69 : 47|1@1+ (1,0) [0|1] "" Vector__XXX
 SG_ CP_a070_i2cIBCR m70 : 16|8@1+ (1,0) [0|255] "" Vector__XXX
 SG_ CP_a070_i2cIBSR m70 : 24|8@1+ (1,0) [0|255] "" Vector__XXX
 SG_ CP_a071_expectedMessage m71 : 16|4@1+ (1,0) [0|15] "" Vector__XXX
 SG_ CP_a072_currentMessage m72 : 16|4@1+ (1,0) [0|15] "" Vector__XXX
 SG_ CP_a072_readyToChargeExpired m72 : 20|1@1+ (1,0) [0|1] "" Vector__XXX
 SG_ CP_a072_commsSetupExpired m72 : 21|1@1+ (1,0) [0|1] "" Vector__XXX
 SG_ CP_a072_cableCheckExpired m72 : 22|1@1+ (1,0) [0|1] "" Vector__XXX
 SG_ CP_a072_preChargeExpired m72 : 23|1@1+ (1,0) [0|1] "" Vector__XXX
 SG_ CP_a073_ccsManagerState m73 : 16|3@1+ (1,0) [0|7] "" Vector__XXX
 SG_ CP_a073_ccsDcState m73 : 19|4@1+ (1,0) [0|15] "" Vector__XXX
 SG_ CP_a073_ccsShutdownReason m73 : 24|4@1+ (1,0) [0|15] "" Vector__XXX
 SG_ CP_a073_comboHandleNotPresent m73 : 28|1@1+ (1,0) [0|1] "" Vector__XXX
 SG_ CP_a073_commsFault m73 : 29|1@1+ (1,0) [0|1] "" Vector__XXX
 SG_ CP_a073_bmsShutdownRequested m73 : 30|1@1+ (1,0) [0|1] "" Vector__XXX
 SG_ CP_a073_evseShutdownRequested m73 : 31|1@1+ (1,0) [0|1] "" Vector__XXX
 SG_ CP_a073_cpInternalStopChgRequest m73 : 32|1@1+ (1,0) [0|1] "" Vector__XXX
 SG_ CP_a073_v2gCommsEstablished m73 : 33|1@1+ (1,0) [0|1] "" Vector__XXX
 SG_ CP_a073_emergencyShutdown m73 : 34|1@1+ (1,0) [0|1] "" Vector__XXX
 SG_ CP_a073_servicesNotSupported m73 : 35|1@1+ (1,0) [0|1] "" Vector__XXX
 SG_ CP_a073_ccs1AdapterBtnPress m73 : 36|1@1+ (1,0) [0|1] "" Vector__XXX
 SG_ CP_a074_slacState m74 : 16|4@1+ (1,0) [0|15] "" Vector__XXX
 SG_ CP_a074_slacErrorCode m74 : 20|4@1+ (1,0) [0|15] "" Vector__XXX
 SG_ CP_a074_sdpNoDiscoveryResponse m74 : 24|1@1+ (1,0) [0|1] "" Vector__XXX
 SG_ CP_a074_evseMeasuredAtten m74 : 32|8@1+ (1,0) [0|255] "" Vector__XXX
 SG_ CP_a075_evccState m75 : 16|3@1+ (1,0) [0|7] "" Vector__XXX
 SG_ CP_a075_currentMessage m75 : 19|4@1+ (1,0) [0|15] "" Vector__XXX
 SG_ CP_a075_exiUnpackFailed m75 : 23|1@1+ (1,0) [0|1] "" Vector__XXX
 SG_ CP_a075_failedResponseCode m75 : 24|1@1+ (1,0) [0|1] "" Vector__XXX
 SG_ CP_a075_evseMeasuredAtten m75 : 32|8@1+ (1,0) [0|255] "" Vector__XXX
 SG_ CP_a075_evseEmergencyChgEnd m75 : 40|1@1+ (1,0) [0|1] "" Vector__XXX
 SG_ CP_a075_initFailureType m75 : 41|2@1+ (1,0) [0|3] "" Vector__XXX
 SG_ CP_a077_mac1Invalid m77 : 16|1@1+ (1,0) [0|1] "" Vector__XXX
 SG_ CP_a077_mac2Invalid m77 : 17|1@1+ (1,0) [0|1] "" Vector__XXX
 SG_ CP_a077_macsMatching m77 : 18|1@1+ (1,0) [0|1] "" Vector__XXX
 SG_ CP_a078_VC_tempAmbientFiltered m78 : 16|8@1+ (0.5,-40) [-39.5|87.5] "degC" Vector__XXX
 SG_ CP_a078_pinTemperature1 m78 : 24|8@1+ (0.8039216,-55) [-55|149.1960864] "C" Vector__XXX
 SG_ CP_a078_pinTemperature2 m78 : 32|8@1+ (0.8039216,-55) [-55|149.1960864] "C" Vector__XXX
 SG_ CP_a078_pinTemperature3 m78 : 40|8@1+ (0.8039216,-55) [-55|149.1960864] "C" Vector__XXX
 SG_ CP_a079_VC_tempAmbientFiltered m79 : 16|8@1+ (0.5,-40) [-39.5|87.5] "degC" Vector__XXX
 SG_ CP_a079_pinTemperature1 m79 : 24|8@1+ (0.8039216,-55) [-55|149.1960864] "C" Vector__XXX
 SG_ CP_a079_pinTemperature2 m79 : 32|8@1+ (0.8039216,-55) [-55|149.1960864] "C" Vector__XXX
 SG_ CP_a079_pinTemperature3 m79 : 40|8@1+ (0.8039216,-55) [-55|149.1960864] "C" Vector__XXX
 SG_ CP_a084_proximityV m84 : 16|16@1+ (0.0001,0) [0|6.5535] "V" Vector__XXX
 SG_ CP_a084_cc1Voltage m84 : 32|14@1+ (0.001,0) [0|16.383] "V" Vector__XXX
 SG_ CP_a084_cc2Voltage m84 : 48|14@1+ (0.001,0) [0|16.383] "V" Vector__XXX
 SG_ CP_a085_absoluteTempFault m85 : 16|1@1+ (1,0) [0|1] "" Vector__XXX
 SG_ CP_a085_dcPinTemp m85 : 24|8@1+ (0.8039216,-55) [-55|150.000008] "C" Vector__XXX
 SG_ CP_a086_dcPinTemp m86 : 16|8@1+ (0.8039216,-55) [-55|150.000008] "C" Vector__XXX
 SG_ CP_a089_gtwPlcSupportType m89 : 16|2@1+ (1,0) [0|3] "" Vector__XXX
 SG_ CP_a089_plcModemPopulated m89 : 18|1@1+ (1,0) [0|1] "" Vector__XXX
 SG_ CP_a090_evseIsoStatus m90 : 16|3@1+ (1,0) [0|7] "" Vector__XXX
 SG_ CP_a090_ccsDcState m90 : 19|4@1+ (1,0) [0|15] "" Vector__XXX
 SG_ CP_a091_fcType m91 : 16|3@1+ (1,0) [0|6] "" Vector__XXX
 SG_ CP_a093_appLoadingNumRetries m93 : 16|3@1+ (1,0) [0|7] "" Vector__XXX
 SG_ CP_a093_interruptCauseRegError m93 : 19|1@1+ (1,0) [0|1] "" Vector__XXX
 SG_ CP_a094_faultResetCount m94 : 16|8@1+ (1,0) [0|255] "" Vector__XXX
 SG_ CP_a095_packCurrent m95 : 16|13@1- (1,0) [-4096|4095] "A" Vector__XXX
 SG_ CP_a095_dcOutputCurrent m95 : 32|13@1- (1,0) [-4096|4095] "A" Vector__XXX
 SG_ CP_a095_ambientTemp m95 : 48|8@1+ (0.8039216,-55) [-55|150.000008] "C" Vector__XXX
 SG_ CP_a095_fcType m95 : 56|3@1+ (1,0) [0|6] "" Vector__XXX
 SG_ CP_a095_fcBrand m95 : 59|1@1+ (1,0) [0|1] "" Vector__XXX
 SG_ CP_a099_proximity m99 : 16|2@1+ (1,0) [1|3] "" Vector__XXX
 SG_ CP_a099_pilot m99 : 18|3@1+ (1,0) [0|6] "" Vector__XXX
 SG_ CP_a103_proximityV m103 : 16|16@1+ (0.0001,0) [0|6.5535] "V" Vector__XXX
 SG_ CP_a109_thermistorId m109 : 16|3@1+ (1,0) [0|7] "" Vector__XXX
 SG_ CP_a109_thermistorTemp m109 : 24|8@1+ (0.8039216,-55) [-55|150.000008] "C" Vector__XXX
 SG_ CP_a110_thermistorId m110 : 16|3@1+ (1,0) [0|7] "" Vector__XXX
 SG_ CP_a110_thermistorTemp m110 : 24|8@1+ (0.8039216,-55) [-55|150.000008] "C" Vector__XXX
 SG_ CP_a110_thermalVelocity m110 : 32|10@1- (0.15748,0) [-80.62976|80.3148] "C/min" Vector__XXX
 SG_ CP_a111_heaterTemperature m111 : 16|8@1+ (0.8039216,-55) [-55|149.1960864] "C" Vector__XXX
 SG_ CP_a111_VC_tempAmbientFiltered m111 : 24|8@1+ (0.5,-40) [-39.5|87.5] "degC" Vector__XXX
 SG_ CP_a112_heaterTemperature m112 : 16|8@1+ (0.8039216,-55) [-55|149.1960864] "C" Vector__XXX
 SG_ CP_a113_heaterTemperature m113 : 16|8@1+ (0.8039216,-55) [-55|149.1960864] "C" Vector__XXX
 SG_ CP_a113_heaterCurrent m113 : 24|12@1+ (0.0025,0) [0|10.2375] "A" Vector__XXX
 SG_ CP_a116_hvCoverDetected m116 : 16|1@1+ (1,0) [0|1] "" Vector__XXX
 SG_ CP_a116_heaterDetected m116 : 17|1@1+ (1,0) [0|1] "" Vector__XXX
 SG_ CP_a116_temperatureSensorMismatc m116 : 18|1@1+ (1,0) [0|1] "" Vector__XXX
 SG_ CP_a116_thermistorsOpenCircuit m116 : 19|1@1+ (1,0) [0|1] "" Vector__XXX
 SG_ CP_a117_heaterTemperature m117 : 16|8@1+ (0.8039216,-55) [-55|149.1960864] "C" Vector__XXX
 SG_ CP_a117_averageError m117 : 24|8@1+ (0.8039216,-55) [-55|149.1960864] "C" Vector__XXX
 SG_ CP_a120_oldProximtyV m120 : 16|10@1+ (0.00488758552819,0) [0|4.99999999534] "V" Vector__XXX
 SG_ CP_a120_newProximtyV m120 : 26|10@1+ (0.00488758552819,0) [0|4.99999999534] "V" Vector__XXX
 SG_ CP_a120_chargeVoltage m120 : 36|10@1+ (1.171875,0) [0|1198.828125] "V" Vector__XXX
 SG_ CP_a120_chargeCurrent m120 : 46|10@1+ (1.7578125,0) [0|1798.2421875] "A" Vector__XXX
 SG_ CP_a120_dcPinTemp m120 : 56|8@1+ (0.8039216,-55) [-55|149.1960864] "C" Vector__XXX
 SG_ CP_a121_CP_status_MIA m121 : 16|1@1+ (1,0) [0|1] "" Vector__XXX
 SG_ CP_a124_ivledState m124 : 16|2@1+ (1,0) [0|3] "" Vector__XXX
 SG_ CP_a124_ivledVoltage m124 : 24|8@1+ (0.01968504,0) [0|5.0196852] "V" Vector__XXX
 SG_ CP_a125_okToUseHighPower m125 : 16|1@1+ (1,0) [0|1] "" Vector__XXX
 SG_ CP_a127_HVLINK_cpControl_MIA m127 : 16|1@1+ (1,0) [0|1] "" Vector__XXX
 SG_ CP_a129_bldcDriverState m129 : 16|2@1+ (1,0) [0|3] "" Vector__XXX
 SG_ CP_a130_retryCount m130 : 16|8@1+ (1,0) [0|255] "" Vector__XXX
 SG_ CP_a131_chargeProtocol m131 : 16|3@1+ (1,0) [0|7] "" Vector__XXX
 SG_ CP_a135_sdpErr m135 : 16|3@1+ (1,0) [0|7] "" Vector__XXX
 SG_ CP_a135_pilotState m135 : 19|3@1+ (1,0) [0|6] "" Vector__XXX
 SG_ CP_a135_evseMeasuredAtten m135 : 24|8@1+ (1,0) [0|255] "" Vector__XXX
 SG_ CP_a138_FC_type m138 : 16|3@1+ (1,0) [0|6] "" Vector__XXX
 SG_ CP_a138_latchState m138 : 19|2@1+ (1,0) [1|3] "" Vector__XXX
 SG_ CP_a138_CP_proximity m138 : 21|2@1+ (1,0) [1|3] "" Vector__XXX
 SG_ CP_a139_latchState m139 : 16|2@1+ (1,0) [1|3] "" Vector__XXX
 SG_ CP_a139_CP_proximity m139 : 18|2@1+ (1,0) [1|3] "" Vector__XXX
 SG_ CP_a140_latchState m140 : 16|2@1+ (1,0) [1|3] "" Vector__XXX
 SG_ CP_a140_CP_proximity m140 : 18|2@1+ (1,0) [1|3] "" Vector__XXX
 SG_ CP_a141_latchState m141 : 16|2@1+ (1,0) [1|3] "" Vector__XXX
 SG_ CP_a141_CP_proximity m141 : 18|2@1+ (1,0) [1|3] "" Vector__XXX
 SG_ CP_a142_cc1Voltage m142 : 16|14@1+ (0.001,0) [0|16.383] "V" Vector__XXX
 SG_ CP_a142_cc2Voltage m142 : 32|14@1+ (0.001,0) [0|16.383] "V" Vector__XXX
 SG_ CP_a143_versionDetected m143 : 16|3@1+ (1,0) [0|7] "" Vector__XXX
 SG_ CP_a146_v2gMessage m146 : 16|4@1+ (1,0) [0|15] "" Vector__XXX
 SG_ CP_a151_pilotHighMin m151 : 16|12@1+ (0.00354090356268,0) [0|14.5000000892] "V" Vector__XXX
 SG_ CP_a151_pilotHighMax m151 : 28|12@1+ (0.00354090356268,0) [0|14.5000000892] "V" Vector__XXX
 SG_ CP_a151_pilotLowMin m151 : 40|12@1- (0.0105031756684,-5.745237) [-27.2557407689|15.7547635932] "V" Vector__XXX
 SG_ CP_a151_pilotLowMax m151 : 52|12@1- (0.0105031756684,-5.745237) [-27.2557407689|15.7547635932] "V" Vector__XXX
 SG_ CP_a152_swcanHighMismatchCount m152 : 16|5@1+ (1,0) [0|31] "" Vector__XXX
 SG_ CP_a152_swcanLowMismatchCount m152 : 21|5@1+ (1,0) [0|31] "" Vector__XXX
 SG_ CP_a152_maxPilotSwcanHigh m152 : 26|9@1+ (0.0283757336438,0) [0|14.499999892] "V" Vector__XXX
 SG_ CP_a152_minPilotSwcanHigh m152 : 35|9@1+ (0.0283757336438,0) [0|14.499999892] "V" Vector__XXX
 SG_ CP_a152_maxPilotSwcanLow m152 : 44|9@1+ (0.0283757336438,0) [0|14.499999892] "V" Vector__XXX
 SG_ CP_a152_minPilotSwcanLow m152 : 53|9@1+ (0.0283757336438,0) [0|14.499999892] "V" Vector__XXX
 SG_ CP_a153_acPinTempVelocity m153 : 16|10@1- (0.15748,0) [-80.62976|80.3148] "C/min" Vector__XXX
 SG_ CP_a153_acPinTemp1 m153 : 26|8@1+ (0.8039216,-55) [-55|149.1960864] "C" Vector__XXX
 SG_ CP_a153_acPinTemp2 m153 : 34|8@1+ (0.8039216,-55) [-55|149.1960864] "C" Vector__XXX
 SG_ CP_a153_ambientTemp m153 : 42|8@1+ (0.8039216,-55) [-55|150.000008] "C" Vector__XXX
 SG_ CP_a153_pcsLineChargeCurrent m153 : 50|9@1+ (0.1,0) [0|51.1] "A" Vector__XXX
 SG_ CP_a154_acPinTempVelocity m154 : 16|10@1- (0.15748,0) [-80.62976|80.3148] "C/min" Vector__XXX
 SG_ CP_a154_acPinTemp1 m154 : 26|8@1+ (0.8039216,-55) [-55|149.1960864] "C" Vector__XXX
 SG_ CP_a154_acPinTemp2 m154 : 34|8@1+ (0.8039216,-55) [-55|149.1960864] "C" Vector__XXX
 SG_ CP_a154_ambientTemp m154 : 42|8@1+ (0.8039216,-55) [-55|150.000008] "C" Vector__XXX
 SG_ CP_a154_pcsLineChargeCurrent m154 : 50|9@1+ (0.1,0) [0|51.1] "A" Vector__XXX
 SG_ CP_a155_hallSensorVoltage m155 : 16|10@1+ (0.00488758552819,0) [0|4.99999999534] "V" Vector__XXX
 SG_ CP_a161_pilotHighMin m161 : 16|12@1+ (0.00354090356268,0) [0|14.5000000892] "V" Vector__XXX
 SG_ CP_a161_pilotHighMax m161 : 28|12@1+ (0.00354090356268,0) [0|14.5000000892] "V" Vector__XXX
 SG_ CP_a161_pilotLowMin m161 : 40|12@1- (0.0105031756684,-5.745237) [-27.2557407689|15.7547635932] "V" Vector__XXX
 SG_ CP_a161_pilotLowMax m161 : 52|12@1- (0.0105031756684,-5.745237) [-27.2557407689|15.7547635932] "V" Vector__XXX
 SG_ CP_a162_swcanHighMismatchCount m162 : 16|5@1+ (1,0) [0|31] "" Vector__XXX
 SG_ CP_a162_swcanLowMismatchCount m162 : 21|5@1+ (1,0) [0|31] "" Vector__XXX
 SG_ CP_a162_maxPilotSwcanHigh m162 : 26|9@1+ (0.0283757336438,0) [0|14.499999892] "V" Vector__XXX
 SG_ CP_a162_minPilotSwcanHigh m162 : 35|9@1+ (0.0283757336438,0) [0|14.499999892] "V" Vector__XXX
 SG_ CP_a162_maxPilotSwcanLow m162 : 44|9@1+ (0.0283757336438,0) [0|14.499999892] "V" Vector__XXX
 SG_ CP_a162_minPilotSwcanLow m162 : 53|9@1+ (0.0283757336438,0) [0|14.499999892] "V" Vector__XXX
 SG_ CP_a163_cover1OpenCounts m163 : 16|12@1+ (0.025,0) [0|102.375] "%" Vector__XXX
 SG_ CP_a163_cover2OpenCounts m163 : 28|12@1+ (0.025,0) [0|102.375] "%" Vector__XXX
 SG_ CP_a163_cover1State m163 : 40|3@1+ (1,0) [0|7] "" Vector__XXX
 SG_ CP_a163_cover2State m163 : 43|3@1+ (1,0) [0|7] "" Vector__XXX
 SG_ CP_a164_VC_tempAmbientFiltered m164 : 16|8@1+ (0.5,-40) [-39.5|87.5] "degC" Vector__XXX
 SG_ CP_a164_minInternalPinTemp m164 : 24|8@1+ (0.8039216,-55) [-55|149.1960864] "C" Vector__XXX
 SG_ CP_a173_cover1OpenCounts m173 : 16|12@1+ (0.025,0) [0|102.375] "%" Vector__XXX
 SG_ CP_a173_cover2OpenCounts m173 : 28|12@1+ (0.025,0) [0|102.375] "%" Vector__XXX
 SG_ CP_a173_cover1State m173 : 40|3@1+ (1,0) [0|7] "" Vector__XXX
 SG_ CP_a173_cover2State m173 : 43|3@1+ (1,0) [0|7] "" Vector__XXX

BO_ 798 CP_alertMatrix: 8 CP
 SG_ CP_matrixIndex M : 0|4@1+ (1,0) [0|15] "" Vector__XXX
 SG_ CP_a001_canRx m0 : 4|1@1+ (1,0) [0|1] "" Vector__XXX
 SG_ CP_a002_canTx m0 : 5|1@1+ (1,0) [0|1] "" Vector__XXX
 SG_ CP_a003_canError m0 : 6|1@1+ (1,0) [0|1] "" Vector__XXX
 SG_ CP_a004_proximityRationality m0 : 7|1@1+ (1,0) [0|1] "" Vector__XXX
 SG_ CP_a005_gbdcLiveDisconnect m0 : 8|1@1+ (1,0) [0|1] "" Vector__XXX
 SG_ CP_a006_lostCommsBMS m0 : 9|1@1+ (1,0) [0|1] "" Vector__XXX
 SG_ CP_a007_watchdog m0 : 10|1@1+ (1,0) [0|1] "" Vector__XXX
 SG_ CP_a008_memoryError m0 : 11|1@1+ (1,0) [0|1] "" Vector__XXX
 SG_ CP_a009_coverOpenAllChgBlocked m0 : 12|1@1+ (1,0) [0|1] "" Vector__XXX
 SG_ CP_a010_pilotRationality m0 : 13|1@1+ (1,0) [0|1] "" Vector__XXX
 SG_ CP_a011_eeprom m0 : 14|1@1+ (1,0) [0|1] "" Vector__XXX
 SG_ CP_a012_ledDriver m0 : 15|1@1+ (1,0) [0|1] "" Vector__XXX
 SG_ CP_a013_lostCommsGTW m0 : 16|1@1+ (1,0) [0|1] "" Vector__XXX
 SG_ CP_a014_lostCommsCHG m0 : 17|1@1+ (1,0) [0|1] "" Vector__XXX
 SG_ CP_a015_apsVov m0 : 18|1@1+ (1,0) [0|1] "" Vector__XXX
 SG_ CP_a016_apsVuv m0 : 19|1@1+ (1,0) [0|1] "" Vector__XXX
 SG_ CP_a017_fiveVov m0 : 20|1@1+ (1,0) [0|1] "" Vector__XXX
 SG_ CP_a018_fiveVuv m0 : 21|1@1+ (1,0) [0|1] "" Vector__XXX
 SG_ CP_a019_threeVov m0 : 22|1@1+ (1,0) [0|1] "" Vector__XXX
 SG_ CP_a020_threeVuv m0 : 23|1@1+ (1,0) [0|1] "" Vector__XXX
 SG_ CP_a021_zeroVov m0 : 24|1@1+ (1,0) [0|1] "" Vector__XXX
 SG_ CP_a022_zeroVuv m0 : 25|1@1+ (1,0) [0|1] "" Vector__XXX
 SG_ CP_a023_gbdcSessionFailed m0 : 26|1@1+ (1,0) [0|1] "" Vector__XXX
 SG_ CP_a024_ledsUC m0 : 27|1@1+ (1,0) [0|1] "" Vector__XXX
 SG_ CP_a025_ledsOC m0 : 28|1@1+ (1,0) [0|1] "" Vector__XXX
 SG_ CP_a026_networkManagement m0 : 29|1@1+ (1,0) [0|1] "" Vector__XXX
 SG_ CP_a027_doorSensorOutOfSpec m0 : 30|1@1+ (1,0) [0|1] "" Vector__XXX
 SG_ CP_a028_insertEnableMismatch m0 : 31|1@1+ (1,0) [0|1] "" Vector__XXX
 SG_ CP_a029_doorClosedProxPilot m0 : 32|1@1+ (1,0) [0|1] "" Vector__XXX
 SG_ CP_a030_busOff m0 : 33|1@1+ (1,0) [0|1] "" Vector__XXX
 SG_ CP_a031_doorClosedCommandedOpen m0 : 34|1@1+ (1,0) [0|1] "" Vector__XXX
 SG_ CP_a032_doorOpenExpectedClosed m0 : 35|1@1+ (1,0) [0|1] "" Vector__XXX
 SG_ CP_a033_spiOpen m0 : 36|1@1+ (1,0) [0|1] "" Vector__XXX
 SG_ CP_a034_calibrationIncomplete m0 : 37|1@1+ (1,0) [0|1] "" Vector__XXX
 SG_ CP_a035_latchMovement_1 m0 : 38|1@1+ (1,0) [0|1] "" Vector__XXX
 SG_ CP_a036_latchNotDisengaged m0 : 39|1@1+ (1,0) [0|1] "" Vector__XXX
 SG_ CP_a037_latchNotEngaged m0 : 40|1@1+ (1,0) [0|1] "" Vector__XXX
 SG_ CP_a038_latchNotBlocking m0 : 41|1@1+ (1,0) [0|1] "" Vector__XXX
 SG_ CP_a039_latchMovement_2 m0 : 42|1@1+ (1,0) [0|1] "" Vector__XXX
 SG_ CP_a040_doNotUse m0 : 43|1@1+ (1,0) [0|1] "" Vector__XXX
 SG_ CP_a041_doorSensorUnplugged m0 : 44|1@1+ (1,0) [0|1] "" Vector__XXX
 SG_ CP_a042_doorAssemblyBroken m0 : 45|1@1+ (1,0) [0|1] "" Vector__XXX
 SG_ CP_a043_doorPotIrrational m0 : 46|1@1+ (1,0) [0|1] "" Vector__XXX
 SG_ CP_a044_lostCommsHVP m0 : 47|1@1+ (1,0) [0|1] "" Vector__XXX
 SG_ CP_a045_lostCommsVCSEC m0 : 48|1@1+ (1,0) [0|1] "" Vector__XXX
 SG_ CP_a046_lostCommsEVSE m0 : 49|1@1+ (1,0) [0|1] "" Vector__XXX
 SG_ CP_a047_lostCommsVCFRONT m0 : 50|1@1+ (1,0) [0|1] "" Vector__XXX
 SG_ CP_a048_lostCommsUI m0 : 51|1@1+ (1,0) [0|1] "" Vector__XXX
 SG_ CP_a049_multipleCablesDetected m0 : 52|1@1+ (1,0) [0|1] "" Vector__XXX
 SG_ CP_a050_latchNotConnected m0 : 53|1@1+ (1,0) [0|1] "" Vector__XXX
 SG_ CP_a051_doorInductiveSensorMIA m0 : 54|1@1+ (1,0) [0|1] "" Vector__XXX
 SG_ CP_a052_chademoNotSupported m0 : 55|1@1+ (1,0) [0|1] "" Vector__XXX
 SG_ CP_a053_proxLatchedNoPilot m0 : 56|1@1+ (1,0) [0|1] "" Vector__XXX
 SG_ CP_a054_cableNotSecured m0 : 57|1@1+ (1,0) [0|1] "" Vector__XXX
 SG_ CP_a055_chargeStoppedNoPilot m0 : 58|1@1+ (1,0) [0|1] "" Vector__XXX
 SG_ CP_a056_proxDisconnected m0 : 59|1@1+ (1,0) [0|1] "" Vector__XXX
 SG_ CP_a057_ccs1AdapterBtnPress m0 : 60|1@1+ (1,0) [0|1] "" Vector__XXX
 SG_ CP_a058_acChargeRetryPending m0 : 61|1@1+ (1,0) [0|1] "" Vector__XXX
 SG_ CP_a059_swcanError m0 : 62|1@1+ (1,0) [0|1] "" Vector__XXX
 SG_ CP_a060_lostCommsPCS m0 : 63|1@1+ (1,0) [0|1] "" Vector__XXX
 SG_ CP_a061_uhfReceiverMIA m1 : 4|1@1+ (1,0) [0|1] "" Vector__XXX
 SG_ CP_a062_scOutOfService m1 : 5|1@1+ (1,0) [0|1] "" Vector__XXX
 SG_ CP_a063_scUpdateInProgress m1 : 6|1@1+ (1,0) [0|1] "" Vector__XXX
 SG_ CP_a064_superchargingBlocked m1 : 7|1@1+ (1,0) [0|1] "" Vector__XXX
 SG_ CP_a065_selfTestFailed m1 : 8|1@1+ (1,0) [0|1] "" Vector__XXX
 SG_ CP_a066_proxLatchedIdlePilot m1 : 9|1@1+ (1,0) [0|1] "" Vector__XXX
 SG_ CP_a067_gbdcConnFault m1 : 10|1@1+ (1,0) [0|1] "" Vector__XXX
 SG_ CP_a068_doorSensorMismatch m1 : 11|1@1+ (1,0) [0|1] "" Vector__XXX
 SG_ CP_a069_doorInductiveSensorError m1 : 12|1@1+ (1,0) [0|1] "" Vector__XXX
 SG_ CP_a070_doorInductiveSensorReset m1 : 13|1@1+ (1,0) [0|1] "" Vector__XXX
 SG_ CP_a071_exiDecodeFailure m1 : 14|1@1+ (1,0) [0|1] "" Vector__XXX
 SG_ CP_a072_v2gEvccTimeout m1 : 15|1@1+ (1,0) [0|1] "" Vector__XXX
 SG_ CP_a073_iecComboShutdown m1 : 16|1@1+ (1,0) [0|1] "" Vector__XXX
 SG_ CP_a074_failedToEstablishV2gComm m1 : 17|1@1+ (1,0) [0|1] "" Vector__XXX
 SG_ CP_a075_v2gCommsFailure m1 : 18|1@1+ (1,0) [0|1] "" Vector__XXX
 SG_ CP_a076_LDC1612errorWatchdog m1 : 19|1@1+ (1,0) [0|1] "" Vector__XXX
 SG_ CP_a077_invalidMacAddress m1 : 20|1@1+ (1,0) [0|1] "" Vector__XXX
 SG_ CP_a078_latchNotDisengagedCold m1 : 21|1@1+ (1,0) [0|1] "" Vector__XXX
 SG_ CP_a079_cableNotSecuredCold m1 : 22|1@1+ (1,0) [0|1] "" Vector__XXX
 SG_ CP_a080_taskStackOverflow m1 : 23|1@1+ (1,0) [0|1] "" Vector__XXX
 SG_ CP_a081_swException m1 : 24|1@1+ (1,0) [0|1] "" Vector__XXX
 SG_ CP_a082_powerOnReset m1 : 25|1@1+ (1,0) [0|1] "" Vector__XXX
 SG_ CP_a083_watchdogTraceData m1 : 26|1@1+ (1,0) [0|1] "" Vector__XXX
 SG_ CP_a084_proxPeDisconnected_gb m1 : 27|1@1+ (1,0) [0|1] "" Vector__XXX
 SG_ CP_a085_dcPinTempFaulted m1 : 28|1@1+ (1,0) [0|1] "" Vector__XXX
 SG_ CP_a086_dcPinTempIrrational m1 : 29|1@1+ (1,0) [0|1] "" Vector__XXX
 SG_ CP_a087_dcTempModelFault m1 : 30|1@1+ (1,0) [0|1] "" Vector__XXX
 SG_ CP_a088_dcTempModelDeviation m1 : 31|1@1+ (1,0) [0|1] "" Vector__XXX
 SG_ CP_a089_plcConfigMismatch m1 : 32|1@1+ (1,0) [0|1] "" Vector__XXX
 SG_ CP_a090_ccsEvseLowIso m1 : 33|1@1+ (1,0) [0|1] "" Vector__XXX
 SG_ CP_a091_wrongSuperchargerHandle m1 : 34|1@1+ (1,0) [0|1] "" Vector__XXX
 SG_ CP_a092_modemAppLoadFailed m1 : 35|1@1+ (1,0) [0|1] "" Vector__XXX
 SG_ CP_a093_modemLoadedWithReset m1 : 36|1@1+ (1,0) [0|1] "" Vector__XXX
 SG_ CP_a094_inductiveResetSuccessful m1 : 37|1@1+ (1,0) [0|1] "" Vector__XXX
 SG_ CP_a095_thermalDcLimitActive m1 : 38|1@1+ (1,0) [0|1] "" Vector__XXX
 SG_ CP_a096_pilotWake m1 : 39|1@1+ (1,0) [0|1] "" Vector__XXX
 SG_ CP_a097_modeTransitionFailure m1 : 40|1@1+ (1,0) [0|1] "" Vector__XXX
 SG_ CP_a098_proximityWake m1 : 41|1@1+ (1,0) [0|1] "" Vector__XXX
 SG_ CP_a099_cableStateUnknown m1 : 42|1@1+ (1,0) [0|1] "" Vector__XXX
 SG_ CP_a100_inletHarnessIdIrrational m1 : 43|1@1+ (1,0) [0|1] "" Vector__XXX
 SG_ CP_a101_wcFoldbackActive m1 : 44|1@1+ (1,0) [0|1] "" Vector__XXX
 SG_ CP_a102_wcOvertempFault m1 : 45|1@1+ (1,0) [0|1] "" Vector__XXX
 SG_ CP_a103_proximityPeDisconnected m1 : 46|1@1+ (1,0) [0|1] "" Vector__XXX
 SG_ CP_a104_uhfResetSuccessful m1 : 47|1@1+ (1,0) [0|1] "" Vector__XXX
 SG_ CP_a105_hwUnableToSleep m1 : 48|1@1+ (1,0) [0|1] "" Vector__XXX
 SG_ CP_a106_uhfReceiverReset m1 : 49|1@1+ (1,0) [0|1] "" Vector__XXX
 SG_ CP_a107_chademoFoldbackActive m1 : 50|1@1+ (1,0) [0|1] "" Vector__XXX
 SG_ CP_a108_chademoOvertempFault m1 : 51|1@1+ (1,0) [0|1] "" Vector__XXX
 SG_ CP_a109_thermistorIrrational m1 : 52|1@1+ (1,0) [0|1] "" Vector__XXX
 SG_ CP_a110_thermalVelocityHigh m1 : 53|1@1+ (1,0) [0|1] "" Vector__XXX
 SG_ CP_a111_inletHeaterUnableToHeat m1 : 54|1@1+ (1,0) [0|1] "" Vector__XXX
 SG_ CP_a112_inletHeaterIrrationalTem m1 : 55|1@1+ (1,0) [0|1] "" Vector__XXX
 SG_ CP_a113_inletHeaterShortCircuit m1 : 56|1@1+ (1,0) [0|1] "" Vector__XXX
 SG_ CP_a114_ccsEvseFailed m1 : 57|1@1+ (1,0) [0|1] "" Vector__XXX
 SG_ CP_a115_unexpectedTcan1145State m1 : 58|1@1+ (1,0) [0|1] "" Vector__XXX
 SG_ CP_a116_misconfigurationDetected m1 : 59|1@1+ (1,0) [0|1] "" Vector__XXX
 SG_ CP_a117_inletHeaterUnableToRegul m1 : 60|1@1+ (1,0) [0|1] "" Vector__XXX
 SG_ CP_a118_iecComboLockUp m1 : 61|1@1+ (1,0) [0|1] "" Vector__XXX
 SG_ CP_a119_plcTransmitFailure m1 : 62|1@1+ (1,0) [0|1] "" Vector__XXX
 SG_ CP_a120_comboAdapterFoldback m1 : 63|1@1+ (1,0) [0|1] "" Vector__XXX
 SG_ CP_a121_PLCRLY_lostCommsCP m2 : 4|1@1+ (1,0) [0|1] "" Vector__XXX
 SG_ CP_a122_plcModemFailure m2 : 5|1@1+ (1,0) [0|1] "" Vector__XXX
 SG_ CP_a123_latchPotIrrational m2 : 6|1@1+ (1,0) [0|1] "" Vector__XXX
 SG_ CP_a124_ivledFault m2 : 7|1@1+ (1,0) [0|1] "" Vector__XXX
 SG_ CP_a125_unexpectedLVJuiceState m2 : 8|1@1+ (1,0) [0|1] "" Vector__XXX
 SG_ CP_a126_wakeOnUhfFault m2 : 9|1@1+ (1,0) [0|1] "" Vector__XXX
 SG_ CP_a127_lostCommsHVLINK m2 : 10|1@1+ (1,0) [0|1] "" Vector__XXX
 SG_ CP_a128_lostCommsVC m2 : 11|1@1+ (1,0) [0|1] "" Vector__XXX
 SG_ CP_a129_bldcDriverCommsFailed m2 : 12|1@1+ (1,0) [0|1] "" Vector__XXX
 SG_ CP_a130_bldcDriverCommsRecovered m2 : 13|1@1+ (1,0) [0|1] "" Vector__XXX
 SG_ CP_a131_evseCommTimeout m2 : 14|1@1+ (1,0) [0|1] "" Vector__XXX
 SG_ CP_a132_contractAuthTimeout m2 : 15|1@1+ (1,0) [0|1] "" Vector__XXX
 SG_ CP_a133_proxNeverLatched m2 : 16|1@1+ (1,0) [0|1] "" Vector__XXX
 SG_ CP_a134_plcModemNotExpected m2 : 17|1@1+ (1,0) [0|1] "" Vector__XXX
 SG_ CP_a135_sdpAttemptsFailed m2 : 18|1@1+ (1,0) [0|1] "" Vector__XXX
 SG_ CP_a136_sdpSideReqFailed m2 : 19|1@1+ (1,0) [0|1] "" Vector__XXX
 SG_ CP_a137_plcForwardError m2 : 20|1@1+ (1,0) [0|1] "" Vector__XXX
 SG_ CP_a138_swcanCommsAcEvseFaulted m2 : 21|1@1+ (1,0) [0|1] "" Vector__XXX
 SG_ CP_a139_pilotFaulted m2 : 22|1@1+ (1,0) [0|1] "" Vector__XXX
 SG_ CP_a140_superchargerFaulted m2 : 23|1@1+ (1,0) [0|1] "" Vector__XXX
 SG_ CP_a141_chademoAdapterFault m2 : 24|1@1+ (1,0) [0|1] "" Vector__XXX
 SG_ CP_a142_gbdcScConnFault m2 : 25|1@1+ (1,0) [0|1] "" Vector__XXX
 SG_ CP_a143_unsupportedChargeAdapter m2 : 26|1@1+ (1,0) [0|1] "" Vector__XXX
 SG_ CP_a144_nvmInitFailed m2 : 27|1@1+ (1,0) [0|1] "" Vector__XXX
 SG_ CP_a145_modemAppLoadFailedNA m2 : 28|1@1+ (1,0) [0|1] "" Vector__XXX
 SG_ CP_a146_ccsEvseMalfunction m2 : 29|1@1+ (1,0) [0|1] "" Vector__XXX
 SG_ CP_a147_inductiveRecoveredMia m2 : 30|1@1+ (1,0) [0|1] "" Vector__XXX
 SG_ CP_a148_bldcTachFeedbackMia m2 : 31|1@1+ (1,0) [0|1] "" Vector__XXX
 SG_ CP_a149_pilotPeriodInvalid m2 : 32|1@1+ (1,0) [0|1] "" Vector__XXX
 SG_ CP_a150_railToggleTimeout m2 : 33|1@1+ (1,0) [0|1] "" Vector__XXX
 SG_ CP_a151_badPilotDiodeDetected m2 : 34|1@1+ (1,0) [0|1] "" Vector__XXX
 SG_ CP_a152_pilotEdgeDetectionFailed m2 : 35|1@1+ (1,0) [0|1] "" Vector__XXX
 SG_ CP_a153_thermalAcLimitActive m2 : 36|1@1+ (1,0) [0|1] "" Vector__XXX
 SG_ CP_a154_acChargingStoppedOT m2 : 37|1@1+ (1,0) [0|1] "" Vector__XXX
 SG_ CP_a155_hallPresenceRationality m2 : 38|1@1+ (1,0) [0|1] "" Vector__XXX
 SG_ CP_a156_gbdcPrechargingConcern m2 : 39|1@1+ (1,0) [0|1] "" Vector__XXX
 SG_ CP_a157_doorOpenRateLimiter m2 : 40|1@1+ (1,0) [0|1] "" Vector__XXX
 SG_ CP_a158_doorCloseRateLimiter m2 : 41|1@1+ (1,0) [0|1] "" Vector__XXX
 SG_ CP_a159_swcanHealthCheckFailed m2 : 42|1@1+ (1,0) [0|1] "" Vector__XXX
 SG_ CP_a160_latchDisengageInDcCharge m2 : 43|1@1+ (1,0) [0|1] "" Vector__XXX
 SG_ CP_a161_badPilotDiodeDetectedCN m2 : 44|1@1+ (1,0) [0|1] "" Vector__XXX
 SG_ CP_a162_pilotEdgeDetectionFailed m2 : 45|1@1+ (1,0) [0|1] "" Vector__XXX
 SG_ CP_a163_coverOpenDcChgBlocked m2 : 46|1@1+ (1,0) [0|1] "" Vector__XXX
 SG_ CP_a164_latchRedisengageRequeste m2 : 47|1@1+ (1,0) [0|1] "" Vector__XXX
 SG_ CP_a165_proxWiggleDetected m2 : 48|1@1+ (1,0) [0|1] "" Vector__XXX
 SG_ CP_a166_faultLineMismatchDetecte m2 : 49|1@1+ (1,0) [0|1] "" Vector__XXX
 SG_ CP_a167_doorIdIrrational m2 : 50|1@1+ (1,0) [0|1] "" Vector__XXX
 SG_ CP_a172_triggerOdin m2 : 55|1@1+ (1,0) [0|1] "" Vector__XXX
 SG_ CP_a173_coverOpenAcChgBlocked m2 : 56|1@1+ (1,0) [0|1] "" Vector__XXX
 SG_ CP_a174_fwdedMsgLoadWarning m2 : 57|1@1+ (1,0) [0|1] "" Vector__XXX
 SG_ CP_a175_fwdedMsgDropped m2 : 58|1@1+ (1,0) [0|1] "" Vector__XXX
 SG_ CP_a177_incompatibleV2lDeviceDet m2 : 60|1@1+ (1,0) [0|1] "" Vector__XXX
 SG_ CP_a179_evseCommsTlsError m2 : 62|1@1+ (1,0) [0|1] "" Vector__XXX
 SG_ CP_a182_pncdCommsError m3 : 5|1@1+ (1,0) [0|1] "" Vector__XXX
 SG_ CP_a183_certManagerError m3 : 6|1@1+ (1,0) [0|1] "" Vector__XXX
 SG_ CP_a184_certChangeEvent m3 : 7|1@1+ (1,0) [0|1] "" Vector__XXX
 SG_ CP_a185_pncAuthRejection m3 : 8|1@1+ (1,0) [0|1] "" Vector__XXX
 SG_ CP_a186_spiDmaFailure m3 : 9|1@1+ (1,0) [0|1] "" Vector__XXX
 SG_ CP_a187_highStackUsage m3 : 10|1@1+ (1,0) [0|1] "" Vector__XXX

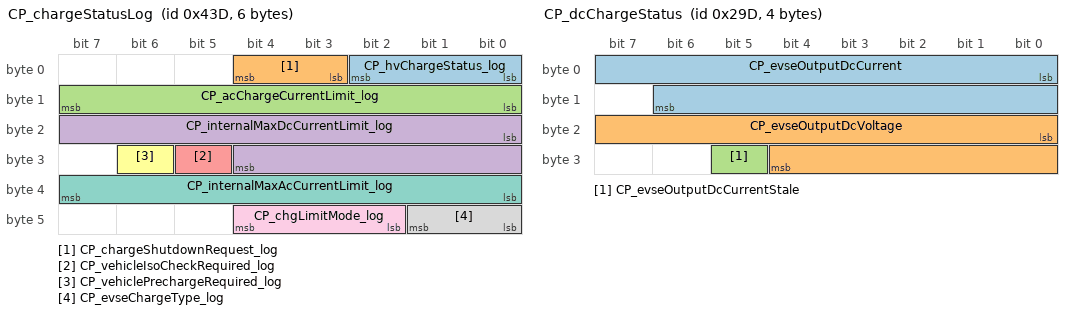
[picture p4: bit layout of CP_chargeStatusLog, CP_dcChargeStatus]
BO_ 1085 CP_chargeStatusLog: 6 CP
 SG_ CP_hvChargeStatus_log : 0|3@1+ (1,0) [0|7] "" Vector__XXX
 SG_ CP_chargeShutdownRequest_log : 3|2@1+ (1,0) [0|3] "" Vector__XXX
 SG_ CP_acChargeCurrentLimit_log : 8|8@1+ (0.5,0) [0|127.5] "A" Vector__XXX
 SG_ CP_internalMaxDcCurrentLimit_log : 16|13@1+ (0.25,0) [0|2047.75] "A" Vector__XXX
 SG_ CP_vehicleIsoCheckRequired_log : 29|1@1+ (1,0) [0|1] "" Vector__XXX
 SG_ CP_vehiclePrechargeRequired_log : 30|1@1+ (1,0) [0|1] "" Vector__XXX
 SG_ CP_internalMaxAcCurrentLimit_log : 32|8@1+ (0.5,0) [0|127.5] "A" Vector__XXX
 SG_ CP_evseChargeType_log : 40|2@1+ (1,0) [0|3] "" Vector__XXX
 SG_ CP_chgLimitMode_log : 42|3@1+ (1,0) [0|7] "" Vector__XXX

BO_ 669 CP_dcChargeStatus: 4 CP
 SG_ CP_evseOutputDcCurrent : 0|15@1- (0.125,0) [-2048|2047.875] "A" Vector__XXX
 SG_ CP_evseOutputDcVoltage : 16|13@1+ (0.07324219,0) [0|599.92675822] "V" Vector__XXX
 SG_ CP_evseOutputDcCurrentStale : 29|1@1+ (1,0) [0|1] "" Vector__XXX

BO_ 541 CP_evseStatus: 8 CP
 SG_ CP_evseAccept : 0|1@1+ (1,0) [0|1] "" Vector__XXX
 SG_ CP_evseRequest : 1|1@1+ (1,0) [0|1] "" Vector__XXX
 SG_ CP_proximity : 2|2@1+ (1,0) [1|3] "" Vector__XXX
 SG_ CP_pilot : 4|3@1+ (1,0) [0|6] "" Vector__XXX
 SG_ CP_digitalCommsEstablished : 7|1@1+ (1,0) [0|1] "" Vector__XXX
 SG_ CP_pilotCurrent : 8|8@1+ (0.5,0) [0|127.5] "A" Vector__XXX
 SG_ CP_cableType : 16|3@1+ (1,0) [0|7] "" Vector__XXX
 SG_ CP_iecPilotState : 19|4@1+ (1,0) [0|15] "" Vector__XXX
 SG_ CP_plcSupported : 23|1@1+ (1,0) [0|1] "" Vector__XXX
 SG_ CP_cableCurrentLimit : 24|7@1+ (1,0) [0|127] "A" Vector__XXX
 SG_ CP_teslaSwcanState : 34|4@1+ (1,0) [0|15] "" Vector__XXX
 SG_ CP_evseChargeType_UI : 38|2@1+ (1,0) [0|3] "" Vector__XXX
 SG_ CP_gbState : 40|4@1+ (1,0) [0|15] "" Vector__XXX
 SG_ CP_gbdcStopChargeReason : 44|4@1+ (1,0) [0|15] "" Vector__XXX
 SG_ CP_gbdcFailureReason : 48|2@1+ (1,0) [0|3] "" Vector__XXX
 SG_ CP_gbdcChargeAttempts : 50|2@1+ (1,0) [0|3] "" Vector__XXX
 SG_ CP_acChargeState : 52|3@1+ (1,0) [0|7] "" Vector__XXX
 SG_ CP_teslaDcState : 56|4@1+ (1,0) [0|15] "" Vector__XXX

BO_ 1885 CP_loggingFast: 8 CP
 SG_ CP_loggingFastSelect M : 0|4@1+ (1,0) [0|15] "" Vector__XXX
 SG_ CP_inductiveSensor_raw m0 : 4|28@1+ (1,0) [0|268435455] "" Vector__XXX
 SG_ CP_doorOpenActuationTime m0 : 32|14@1+ (1,0) [0|16383] "ms" Vector__XXX
 SG_ CP_doorCloseActuationTime m0 : 46|14@1+ (1,0) [0|16383] "ms" Vector__XXX
 SG_ CP_chargeCableSecured m0 : 60|1@1+ (1,0) [0|1] "" Vector__XXX
 SG_ CP_chargeCablePresent m0 : 61|1@1+ (1,0) [0|1] "" Vector__XXX
 SG_ CP_latchCheckAvailable m0 : 62|1@1+ (1,0) [0|1] "" Vector__XXX
 SG_ CP_UHF_controlState m2 : 4|4@1+ (1,0) [0|15] "" Vector__XXX
 SG_ CP_proximityV m2 : 8|16@1+ (0.0001,0) [0|6.5535] "V" Vector__XXX
 SG_ CP_proximityV_GBCC1 m2 : 24|14@1+ (0.001,0) [0|13.3] "V" Vector__XXX
 SG_ CP_proximityV_GBCC2 m2 : 38|14@1+ (0.001,0) [0|13.3] "V" Vector__XXX
 SG_ CP_doorPot m2 : 52|12@1+ (0.025,0) [0|100] "%" Vector__XXX
 SG_ CP_doorPresenceHallSensorV m3 : 4|12@1+ (0.001221,0) [0|4.999995] "V" Vector__XXX
 SG_ CP_doorOpenRequest m3 : 16|4@1+ (1,0) [0|15] "" Vector__XXX
 SG_ CP_doorOpenEndOfDriveReason m3 : 20|3@1+ (1,0) [0|7] "" Vector__XXX
 SG_ CP_coverClosed m3 : 23|1@1+ (1,0) [0|1] "" Vector__XXX
 SG_ CP_doorCloseEndOfDriveReason m3 : 24|3@1+ (1,0) [0|7] "" Vector__XXX
 SG_ CP_doorCloseRequest m3 : 27|5@1+ (1,0) [0|31] "" Vector__XXX
 SG_ CP_latchDisengagingTime m3 : 32|10@1+ (1,0) [0|1023] "ms" Vector__XXX
 SG_ CP_latchEngagingTime m3 : 42|10@1+ (1,0) [0|1023] "ms" Vector__XXX
 SG_ CP_latchDisengagingStopReason m3 : 52|3@1+ (1,0) [0|7] "" Vector__XXX
 SG_ CP_latchEngagingStopReason m3 : 56|3@1+ (1,0) [0|7] "" Vector__XXX
 SG_ CP_doorIdDetectionState m3 : 59|2@1+ (1,0) [1|3] "" Vector__XXX
 SG_ CP_doorIdDetectedBin m3 : 61|2@1+ (1,0) [0|3] "" Vector__XXX

BO_ 2042 CP_loggingSlow: 8 CP
 SG_ CP_loggingSlowSelect M : 0|4@1+ (1,0) [0|15] "" Vector__XXX
 SG_ CP_UHF_chipState m3 : 4|3@1+ (1,0) [0|7] "" Vector__XXX
 SG_ CP_UHF_rssi m3 : 8|8@1+ (1,0) [0|255] "" Vector__XXX
 SG_ CP_UHF_rxOverflow m3 : 16|1@1+ (1,0) [0|1] "" Vector__XXX
 SG_ CP_UHF_rxNumBytes m3 : 17|8@1+ (1,0) [0|255] "" Vector__XXX
 SG_ CP_UHF_selfTestRssi m3 : 25|8@1+ (1,0) [0|255] "" Vector__XXX
 SG_ CP_latchI m3 : 33|12@1+ (0.0025,0) [0|10.2375] "A" Vector__XXX
 SG_ CP_inlet1HarnessIdState m3 : 45|2@1+ (1,0) [1|3] "" Vector__XXX
 SG_ CP_inlet1HarnessIdValue m3 : 47|3@1+ (1,0) [0|7] "" Vector__XXX
 SG_ CP_inlet2HarnessIdState m3 : 50|2@1+ (1,0) [1|3] "" Vector__XXX
 SG_ CP_inlet2HarnessIdValue m3 : 52|3@1+ (1,0) [0|7] "" Vector__XXX
 SG_ CP_inletHeaterState m3 : 55|2@1+ (1,0) [0|3] "" Vector__XXX
 SG_ CP_inletHeaterDuty m3 : 57|7@1+ (1,0) [0|100] "%" Vector__XXX
 SG_ CP_nvm_dataValid m5 : 4|1@1+ (1,0) [0|1] "" Vector__XXX
 SG_ CP_nvm_doorOpenCycles m5 : 8|16@1+ (1,0) [0|65535] "" Vector__XXX
 SG_ CP_nvm_doorCloseCycles m5 : 24|16@1+ (1,0) [0|65535] "" Vector__XXX
 SG_ CP_nvm_doorOpen m5 : 40|1@1+ (1,0) [0|1] "" Vector__XXX
 SG_ CP_nvm_doorPresent m5 : 41|1@1+ (1,0) [0|1] "" Vector__XXX
 SG_ CP_nvm_doorPresentValid m5 : 42|1@1+ (1,0) [0|1] "" Vector__XXX
 SG_ CP_nvm_badPilotDiodeDetected m5 : 43|1@1+ (1,0) [0|1] "" Vector__XXX
 SG_ CP_nvm_pilotDiodeFaultCount m5 : 44|3@1+ (1,0) [0|7] "" Vector__XXX
 SG_ CP_doorOpenLimiterMaxCount m5 : 47|4@1+ (1,0) [0|15] "counts" Vector__XXX
 SG_ CP_doorOpenLimiterMaxRequestType m5 : 51|4@1+ (1,0) [0|15] "" Vector__XXX
 SG_ CP_doorCloseLimiterMaxCount m5 : 55|4@1+ (1,0) [0|15] "counts" Vector__XXX
 SG_ CP_doorCloseLimiterMaxRequestTyp m5 : 59|5@1+ (1,0) [0|31] "" Vector__XXX

BO_TX_BU_ 946 : BMS;
BO_TX_BU_ 914 : BMS;
BO_TX_BU_ 594 : BMS;
BO_TX_BU_ 674 : BMS;
BO_TX_BU_ 658 : BMS;
BO_TX_BU_ 530 : BMS;
BO_TX_BU_ 786 : BMS;
BO_TX_BU_ 2028 : BMS;
BO_TX_BU_ 754 : BMS;
BO_TX_BU_ 810 : BMS;
BO_TX_BU_ 797 : CC;
BO_TX_BU_ 551 : CMP;
BO_TX_BU_ 1294 : CP;
BO_TX_BU_ 798 : CP;
BO_TX_BU_ 1085 : CP;
BO_TX_BU_ 669 : CP;
BO_TX_BU_ 541 : CP;
BO_TX_BU_ 1885 : CP;
BO_TX_BU_ 2042 : CP;
CM_ BO_ 946 "High-voltage battery management system message: log2";
CM_ SG_ 946 BMS_log2MuxId "High-voltage battery management system: log2 mux id";
CM_ SG_ 946 BMS_cacAvg "BMS Calculated Ah Capacity (CAC). This is the average of all the brick CACs";
CM_ SG_ 946 BMS_cacMin "BMS Calculated Ah Capacity (CAC). This is the min of all the brick CACs";
CM_ SG_ 946 BMS_cacMinBrickId "High-voltage battery management system: cac min brick id";
CM_ SG_ 946 BMS_cacMax "BMS Calculated Ah Capacity (CAC). This is the max of all the brick CACs";
CM_ SG_ 946 BMS_cacMaxBrickId "High-voltage battery management system: cac max brick id";
CM_ SG_ 946 BMS_acRippleConfigNvramValid "High-voltage battery management system: ac ripple config nvram valid";
CM_ SG_ 946 BMS_hvChain_useLeakyBucket "Is the leaky bucket being used - an indicator of the HV Chain Model health";
CM_ SG_ 946 BMS_hvChain_iLimit "High-voltage battery management system: hv chain i limit; raw 16383 = signal not available (SNA)";
CM_ SG_ 946 BMS_hvChain_limitingState "High-voltage battery management system: hv chain limiting state; raw 511 = signal not available (SNA)";
CM_ SG_ 946 BMS_hvChain_limitingStateTempera "High-voltage battery management system: hv chain limiting state temperature; raw 4096 = signal not available (SNA)";
CM_ SG_ 946 BMS_acRippleIsSupported "High-voltage battery management system: ac ripple is supported";
CM_ SG_ 946 BMS_acRippleStartTemperatureMax "High-voltage battery management system: ac ripple start temperature max";
CM_ SG_ 946 BMS_acRippleStartTemperatureMin "High-voltage battery management system: ac ripple start temperature min";
CM_ SG_ 946 BMS_fcLinkTestDecayTime "High-voltage battery management system: fc link test decay time; raw 1023 = signal not available (SNA)";
CM_ SG_ 946 BMS_fcLinkTestTimeSinceLastRun "High-voltage battery management system: fc link test time since last run";
CM_ SG_ 946 BMS_pcsPrechargeRequestActive "High-voltage battery management system: pcs precharge request active";
CM_ SG_ 946 BMS_pcsPrechargeTargetVoltage "Target voltage for precharging HV bus";
CM_ SG_ 946 BMS_recentOvUvAlert "At least one of the Brick OV or UV alerts has been active recently; consumed by BMS_a049_SW_Thermal_Event set condition";
CM_ SG_ 946 BMS_recentIsoAlert "At least one of the isolation alerts has been active recently; consumed by BMS_a049_SW_Thermal_Event set condition";
CM_ SG_ 946 BMS_recentBmbMiaAlert "At least one of the BMB communication alerts has been active recently; consumed by BMS_a049_SW_Thermal_Event set condition";
CM_ SG_ 946 BMS_cacBlendingConfigNvramValid "High-voltage battery management system: cac blending config nvram valid";
CM_ SG_ 946 BMS_cacBlendingEnabled "High-voltage battery management system: cac blending enabled";
CM_ SG_ 946 BMS_cacBlendPercentPerCycle "High-voltage battery management system: cac blend percent per cycle";
CM_ SG_ 946 BMS_energyVariableChgRequested "High-voltage battery management system: energy variable chg requested";
CM_ SG_ 946 BMS_packRestTime "Minimum resting time of all bricks";
CM_ SG_ 946 BMS_idealEnergyFloor "Ideal energy estimate based on the min bounded SOC that accounts for accumulated shunt error; raw 1023 = signal not available (SNA)";
CM_ SG_ 946 BMS_thmGradientSlopeCondition "High-voltage battery management system: thm gradient slope condition";
CM_ SG_ 946 BMS_recentSlopeConditon "High-voltage battery management system: recent slope conditon";
CM_ SG_ 946 BMS_dynamicEnergyBuffer "BMS estimate of energy error based on SOC measurement inaccuracy; raw 1023 = signal not available (SNA)";
CM_ SG_ 946 BMS_temperatureCondition "High-voltage battery management system: temperature condition";
CM_ SG_ 946 BMS_thmGradientSlope "High-voltage battery management system: thm gradient slope";
CM_ SG_ 946 BMS_thmGradient "High-voltage battery management system: thm gradient";
CM_ SG_ 946 BMS_dSocNormalizedMin "High-voltage battery management system: d soc normalized min; raw 4095 = signal not available (SNA)";
CM_ SG_ 946 BMS_dSocNormalizedFiltMin "High-voltage battery management system: d soc normalized filt min; raw 4095 = signal not available (SNA)";
CM_ SG_ 946 BMS_dSocMinAlpha "minimum calculated alpha value across all bricks and all dSOC calculations; raw 4095 = signal not available (SNA)";
CM_ SG_ 946 BMS_dSocMaxLowAlphaCounter "High-voltage battery management system: d soc max low alpha counter";
CM_ SG_ 946 BMS_dSocMinAlphaBrickID "High-voltage battery management system: d soc min alpha brick ID";
CM_ SG_ 946 BMS_dSocCacMargin "High-voltage battery management system: d soc cac margin; raw 511 = signal not available (SNA)";
CM_ SG_ 946 BMS_lifeModelAvgTempSeverity "High-voltage battery management system: life model avg temp severity; raw 31 = signal not available (SNA)";
CM_ SG_ 946 BMS_lifeModelDepthOfDischargeSev "High-voltage battery management system: life model depth of discharge severity; raw 255 = signal not available (SNA)";
CM_ SG_ 946 BMS_lifeModelHistogramCapacityLo "High-voltage battery management system: life model histogram capacity loss; raw 511 = signal not available (SNA)";
CM_ SG_ 946 BMS_lifeModelHistogramBrickCapac "High-voltage battery management system: life model histogram brick capacity; raw 8191 = signal not available (SNA)";
CM_ SG_ 946 BMS_lifeModelDcrGrowthPercent "High-voltage battery management system: life model dcr growth percent; raw 8192 = signal not available (SNA)";
CM_ SG_ 946 BMS_nominalFullPackEnergyRaw "Non-latched version of BMS_nominalEnergyRemaining; raw 65535 = signal not available (SNA)";
CM_ SG_ 946 BMS_userChargeCalibratingReason "High-voltage battery management system: user charge calibrating reason";
CM_ SG_ 946 BMS_nominalEnergyRemainingBuffer "Buffered version of BMS_nominalEnergyRemaining; raw 65535 = signal not available (SNA)";
CM_ SG_ 946 BMS_idealEnergyRemainingBuffered "Buffered version of BMS_idealEnergyRemaining; raw 65535 = signal not available (SNA)";
CM_ SG_ 946 BMS_largestCacSpreadErrorLower "High-voltage battery management system: largest cac spread error lower; raw 4095 = signal not available (SNA)";
CM_ SG_ 946 BMS_lifeModelAverageCac "High-voltage battery management system: life model average cac; raw 4095 = signal not available (SNA)";
CM_ SG_ 946 BMS_lifeModelCacBrick1 "High-voltage battery management system: life model cac brick1; raw 4095 = signal not available (SNA)";
CM_ SG_ 946 BMS_lifeModelAverageOffset "High-voltage battery management system: life model average offset; raw 512 = signal not available (SNA)";
CM_ SG_ 946 BMS_percentCacUpdatesInTimeWindo "High-voltage battery management system: percent cac updates in time window";
CM_ SG_ 946 BMS_lifeModelMaxCacBrickId "High-voltage battery management system: life model max cac brick id; raw 255 = signal not available (SNA)";
CM_ SG_ 946 BMS_lifeModelMaxCac "High-voltage battery management system: life model max cac; raw 4095 = signal not available (SNA)";
CM_ SG_ 946 BMS_lifeModelMinCacBrickId "High-voltage battery management system: life model min cac brick id; raw 255 = signal not available (SNA)";
CM_ SG_ 946 BMS_lifeModelMinCac "High-voltage battery management system: life model min cac; raw 4095 = signal not available (SNA)";
CM_ SG_ 946 BMS_restingPointCacAvg "High-voltage battery management system: resting point cac avg; raw 4095 = signal not available (SNA)";
CM_ SG_ 946 BMS_cacEstimationSource "High-voltage battery management system: cac estimation source";
CM_ SG_ 946 BMS_synchronizedCacMaxRaw "High-voltage battery management system: synchronized cac max raw; raw 4095 = signal not available (SNA)";
CM_ SG_ 946 BMS_synchronizedCacMinRaw "High-voltage battery management system: synchronized cac min raw; raw 4095 = signal not available (SNA)";
CM_ SG_ 946 BMS_largestSyncCacErrorStartSoc "Start SOC for CAC update from the brick with the highest synchronized CAC error";
CM_ SG_ 946 BMS_largestSyncCacErrorEndSoc "Start SOC for CAC update from the brick with the highest synchronized CAC error";
CM_ SG_ 946 BMS_runtimeSocConfigNvramValid "High-voltage battery management system: runtime soc config nvram valid";
CM_ SG_ 946 BMS_runtimeSocCorrectionsEnabled "High-voltage battery management system: runtime soc corrections enabled";
CM_ SG_ 946 BMS_rubberBandingEnabled "Reports whether rubber banding of output energy corrections is enabled.";
CM_ SG_ 946 BMS_rubberBandingConfigNvramVali "High-voltage battery management system: rubber banding config nvram valid";
CM_ SG_ 946 BMS_runtimeSocMinTempForModel "High-voltage battery management system: runtime soc min temp for model";
CM_ SG_ 946 BMS_energyBufferConfigNvramValid "High-voltage battery management system: energy buffer config nvram valid";
CM_ SG_ 946 BMS_thermalEvent1pDetectConfigDi "High-voltage battery management system: thermal event1p detect config disabled";
CM_ SG_ 946 BMS_sohEnergy "Battery SOH energy estimate. If calibrated SOH capacity is unavailable, this value is a filtered result from brick CACs; raw 2047 = signal not available (SNA)";
CM_ SG_ 946 BMS_fullCapacitySohEnergy "Energy estimate using nominal brick capacity at maximum SOC using SOH retention test conditions; raw 2047 = signal not available (SNA)";
CM_ SG_ 946 BMS_calibratedCapacitySohEnergy "Energy estimate using CAC from the most recent valid SOH test at maximum SOC using SOH retention test conditions; raw 2047 = signal not available (SNA)";
CM_ SG_ 946 BMS_estimatedCapacitySohEnergy "Energy estimate using filtered brick capacities at maximum SOC using SOH retention test conditions; raw 2047 = signal not available (SNA)";
CM_ SG_ 946 BMS_prevUserFacingSohEnergy "The last soh energy stored in NVM for rate limiting purposes; raw 2047 = signal not available (SNA)";
CM_ SG_ 946 BMS_stateOfHealthMinCac "Reports the minimum Calculated Amp-hour Capacity (CAC) by aged Open Circuit Voltage (OCV) raw values across bricks that could be used in State of Health (SOH) calculations; raw 8191 = signal not available (SNA)";
CM_ SG_ 946 BMS_lifeModelStorageLossPackAge "High-voltage battery management system: life model storage loss pack age; raw 16383 = signal not available (SNA)";
CM_ SG_ 946 BMS_lifeModelThroughputCycleCoun "High-voltage battery management system: life model throughput cycle count; raw 4095 = signal not available (SNA)";
CM_ SG_ 946 BMS_lifeModelThroughputDcrCycleC "High-voltage battery management system: life model throughput dcr cycle count; raw 4095 = signal not available (SNA)";
CM_ SG_ 946 BMS_energyWalkCounter "High-voltage battery management system: energy walk counter";
CM_ SG_ 946 BMS_energyWalkTimeoutCounter "High-voltage battery management system: energy walk timeout counter";
CM_ SG_ 946 BMS_dynamicCcvEnabled "High-voltage battery management system: dynamic ccv enabled";
CM_ SG_ 946 BMS_chargeTargetLookupSoc "High-voltage battery management system: charge target lookup soc";
CM_ SG_ 946 BMS_stateOfHealth "Most recent battery capacity estimate, from a successful SOH test in %; raw 1023 = signal not available (SNA)";
CM_ BO_ 914 "High-voltage battery management system message: pack config";
CM_ SG_ 914 BMS_packConfigMultiplexer "High-voltage battery management system: pack config multiplexer";
CM_ SG_ 914 BMS_reservedConfig_0 "High-voltage battery management system: reserved config 0";
CM_ SG_ 914 BMS_moduleType "High-voltage battery management system: module type";
CM_ SG_ 914 BMS_thermalPackType "High-voltage battery management system: thermal pack type";
CM_ SG_ 914 BMS_packMass "High-voltage battery management system: pack mass";
CM_ SG_ 914 BMS_platformMaxBusVoltage "High-voltage battery management system: platform max bus voltage";
CM_ SG_ 914 BMS_standbySupplyContinuousPower "High-voltage battery management system: standby supply continuous power limit";
CM_ BO_ 594 "High-voltage battery management system message: power available";
CM_ SG_ 594 BMS_maxRegenPower "Calculated max regen power";
CM_ SG_ 594 BMS_maxDischargePower "Calculated max discharge power possible based on max discharge current and sum of loaded voltages";
CM_ SG_ 594 BMS_maxStationaryHeatPower "Maximum heating power the DI can produce when in stationary heating mode";
CM_ SG_ 594 BMS_powerLimitsState "High-voltage battery management system: power limits state";
CM_ SG_ 594 BMS_notEnoughPowerForHeatPump "Flag indicating the min pack power is lower than specified threshold to support heating with the heat pump";
CM_ SG_ 594 BMS_instantChargePowerCapability "Indicates the instantaneous charge power capability of the high voltage battery; raw 65535 = signal not available (SNA)";
CM_ BO_ 674 "High-voltage battery management system message: ripple request";
CM_ SG_ 674 BMS_acRippleCurrentAmplitudeLimi "Transmits the Battery Management System (BMS) AC ripple current amplitude limit to the Electric Vehicle Supply Equipment (EVSE).";
CM_ SG_ 674 BMS_acRippleMaxVoltageLimit "Reports the maximum voltage limit when the Electric Vehicle Supply Equipment (EVSE) is performing the AC ripple.";
CM_ SG_ 674 BMS_acRippleMinVoltageLimit "Reports the minimum voltage limit when the Electric Vehicle Supply Equipment (EVSE) is performing the AC ripple.";
CM_ SG_ 674 BMS_acRippleFrequencyRequest "Transmits the Battery Management System (BMS) AC ripple frequency request to the Electric Vehicle Supply Equipment (EVSE); raw 63 = signal not available (SNA)";
CM_ SG_ 674 BMS_acRippleCurrentAmplitudeRequ "Transmits the Battery Management System (BMS) AC ripple current amplitude request to the Electric Vehicle Supply Equipment (EVSE).";
CM_ SG_ 674 BMS_acRippleRequest "High-voltage battery management system: ac ripple request";
CM_ BO_ 658 "High-voltage battery management system message: soc status";
CM_ SG_ 658 BMS_socMin "BMS State Of Charge (SOC). This is the minimum brick SOC.";
CM_ SG_ 658 BMS_socUI "BMS State Of Energy (SOE) for the UI. This is ideal discharge energy from present state / ideal discharge energy from full.";
CM_ SG_ 658 BMS_socMax "BMS State Of Charge (SOC). This is the maximum brick SOC.";
CM_ SG_ 658 BMS_socAvg "BMS State Of Charge (SOC). This is the average of all the brick SOCs";
CM_ SG_ 658 BMS_beginningOfLifePackEnergy "High-voltage battery management system: beginning of life pack energy; raw 1023 = signal not available (SNA)";
CM_ SG_ 658 BMS_battTempPct "High-voltage battery management system: batt temp pct; raw 255 = signal not available (SNA)";
CM_ SG_ 658 BMS_userChargeCurrentLimitMode "BMS' user-facing reason for charge being either limited or not limited";
CM_ BO_ 530 "High-voltage battery management system message: status";
CM_ SG_ 530 BMS_hvacPowerRequest "High-voltage battery management system: hvac power request";
CM_ SG_ 530 BMS_notEnoughPowerForDrive "Flag indicating the min pack power is lower than specified threshold to support drive";
CM_ SG_ 530 BMS_notEnoughPowerForSupport "Flag indicating if the system can support a new request for 12V battery support";
CM_ SG_ 530 BMS_preconditionAllowed "High-voltage battery management system: precondition allowed";
CM_ SG_ 530 BMS_updateAllowed "High-voltage battery management system: update allowed";
CM_ SG_ 530 BMS_activeHeatingWorthwhile "Determination by the Battery Management System (BMS) if active heating is worthwhile";
CM_ SG_ 530 BMS_cpMiaOnHvs "Flag indicating that BMS is no longer receiving comms from CP on HVS bus";
CM_ SG_ 530 BMS_pcsPwmEnabled "Reports the state of the PCS_PWM_ENABLE input on the HVBMS, which is derived from the P1-12-DCDC-ENABLE input, which comes from VCFRONT";
CM_ SG_ 530 BMS_contactorState "BMS Contactor Status; raw 0 = signal not available (SNA)";
CM_ SG_ 530 BMS_userChargeStatus "BMS charge status for UI display. Renamed from BMS_uiChargeStatus";
CM_ SG_ 530 BMS_totalBatteryPower "High-voltage battery management system: total battery power; raw 65536 = signal not available (SNA)";
CM_ SG_ 530 BMS_chargeRequest "Indicates charge is available and charge is desired";
CM_ SG_ 530 BMS_state "BMS operating state; raw 9 = signal not available (SNA)";
CM_ SG_ 530 BMS_diLimpRequest "BMS request to DI to enter limp mode";
CM_ SG_ 530 BMS_okToShipByAir "High-voltage battery management system: ok to ship by air";
CM_ SG_ 530 BMS_okToShipByLand "High-voltage battery management system: ok to ship by land";
CM_ SG_ 530 BMS_chgPowerAvailable "BMS available charge power; raw 4095 = signal not available (SNA)";
CM_ SG_ 530 BMS_chargeRetryCount "Number of retries remaining to enable charge";
CM_ SG_ 530 BMS_conditioningRequest "BMS request to enable conditioning so it can attempt FEIM recovery";
CM_ SG_ 530 BMS_smStateRequest "BMS high level state request; raw 9 = signal not available (SNA)";
CM_ SG_ 530 BMS_hvState "BMS high voltage state";
CM_ BO_ 786 "High-voltage battery management system message: thermal status";
CM_ SG_ 786 BMS_powerDissipation "High-voltage battery management system: power dissipation";
CM_ SG_ 786 BMS_flowRequest "Requested coolant flow rate in liters per minute (LPM) from the Battery Management System (BMS) to the thermal module";
CM_ SG_ 786 BMS_inletActiveCoolTargetT "Calculated active cooling temperature target at the inlet";
CM_ SG_ 786 BMS_inletPassiveTargetT "Calculated passive temperature target at the inlet";
CM_ SG_ 786 BMS_inletActiveHeatTargetT "Calculated active heating temperature target at the inlet";
CM_ SG_ 786 BMS_minPackTemperature "Minimum pack temperature for consumption by external entities";
CM_ SG_ 786 BMS_maxPackTemperature "Maximum pack temperature for consumption by external entities";
CM_ SG_ 786 BMS_pcsNoFlowRequest "High-voltage battery management system: pcs no flow request";
CM_ SG_ 786 BMS_noFlowRequest "High-voltage battery management system: no flow request";
CM_ BO_ 2028 "High-voltage battery management system message: thermal status2";
CM_ SG_ 2028 BMS_coldStagnationLimit "Minimum temperature at which the pack is allowed to be used as a heat-energy source";
CM_ SG_ 2028 BMS_hotStagnationLimit "Maximum temperature at which we allow the pack to be used for heat-energy storage";
CM_ SG_ 2028 BMS_hotCellTempLimit "Maximum temperature at which the pack will allow limp mode levels of current";
CM_ SG_ 2028 BMS_activeCoolCellReferenceT "Desired cell temperature reference which composes the temperature trajectory portion of the active cooling target temperature controls";
CM_ SG_ 2028 BMS_activeHeatCellTargetT "Desired cell temperature which feeds as an input to the active heating target temperature, before any additional controls calculations";
CM_ SG_ 2028 BMS_cellTempTargetMode "Operating mode of the thermal controls for the Battery Management System (BMS)";
CM_ SG_ 2028 BMS_requestDischarge "Flag identifying when the Battery Management System (BMS) is requesting the battery pack to be discharged";
CM_ BO_ 754 "High-voltage battery management system message: veh nm";
CM_ SG_ 754 BMS_nmGoingToSleep "High-voltage battery management system: nm going to sleep";
CM_ SG_ 754 BMS_nmWakeUpBus "High-voltage battery management system: nm wake up bus";
CM_ SG_ 754 BMS_hvsBusAsleep "HVS bus reported as off";
CM_ SG_ 754 BMS_nmKeepAwakeReason "BMS' determined reason to keep CAN awake; raw 0 = signal not available (SNA)";
CM_ SG_ 754 BMS_nmWakeUpReason "BMS' determined reason to wake up CAN";
CM_ BO_ 810 "High-voltage battery management system message: vehicle notifications";
CM_ SG_ 810 BMS_thermalEventSuspected "Indicates the Battery Management System (BMS) has detected conditions that reflect a possible battery thermal event";
CM_ SG_ 810 BMS_vehicleNotificationsCounter "High-voltage battery management system: vehicle notifications counter";
CM_ SG_ 810 BMS_isolationResistance "Resistance between HV bus and chassis; raw 1023 = signal not available (SNA)";
CM_ SG_ 810 BMS_vehicleNotificationsChecksum "High-voltage battery management system: vehicle notifications checksum";
CM_ BO_ 797 "Charge cable controller message: chg status2";
CM_ SG_ 797 CC_chgStatus2Index "Charge cable controller: chg status2 index";
CM_ SG_ 797 CC_buttonState "Charge cable controller: button state";
CM_ BO_ 551 "A/C compressor message: HV status";
CM_ SG_ 551 CMP_inputHVVoltage "Compressor high voltage input voltage";
CM_ SG_ 551 CMP_inputLVVoltage "A/C compressor: input LV voltage";
CM_ SG_ 551 CMP_inputHVCurrent "A/C compressor: input HV current";
CM_ SG_ 551 CMP_inputHVPower "Compressor high voltage input power";
CM_ BO_ 1294 "Charge port controller message: alert log";
CM_ SG_ 1294 CP_alertID "Charge port controller: alert ID";
CM_ SG_ 1294 CP_alertType "Charge port controller: alert type";
CM_ SG_ 1294 CP_a004_proximityV "Charge port controller: a004 proximity v";
CM_ SG_ 1294 CP_a004_cc1Voltage "Charge port controller: a004 cc1 voltage";
CM_ SG_ 1294 CP_a004_cc2Voltage "Charge port controller: a004 cc2 voltage";
CM_ SG_ 1294 CP_a005_cc1Voltage "Charge port controller: a005 cc1 voltage";
CM_ SG_ 1294 CP_a005_cc2Voltage "Charge port controller: a005 cc2 voltage";
CM_ SG_ 1294 CP_a005_gbdcState "Charge port controller: a005 gbdc state";
CM_ SG_ 1294 CP_a005_packCurrent "Charge port controller: a005 pack current";
CM_ SG_ 1294 CP_a005_evseCurrent "Charge port controller: a005 evse current";
CM_ SG_ 1294 CP_a005_superchargerConnected "Charge port controller: a005 supercharger connected";
CM_ SG_ 1294 CP_a005_latchEngaged "Charge port controller: a005 latch engaged";
CM_ SG_ 1294 CP_a006_BMS_FC_limits_MIA "Charge port controller: a006 BMS FC limits MIA";
CM_ SG_ 1294 CP_a006_BMS_chargeStatus_MIA "Charge port controller: a006 BMS charge status MIA";
CM_ SG_ 1294 CP_a006_BMS_dcChargeLimits_MIA "Charge port controller: a006 BMS dc charge limits MIA";
CM_ SG_ 1294 CP_a006_BMS_hvPackStatus_MIA "Charge port controller: a006 BMS hv pack status MIA";
CM_ SG_ 1294 CP_a006_BMS_kwhCounter_MIA "Charge port controller: a006 BMS kwh counter MIA";
CM_ SG_ 1294 CP_a006_BMS_socStatus_MIA "Charge port controller: a006 BMS soc status MIA";
CM_ SG_ 1294 CP_a008_data1 "Charge port controller: a008 data1";
CM_ SG_ 1294 CP_a008_data2 "Charge port controller: a008 data2";
CM_ SG_ 1294 CP_a008_FlashWarning "Charge port controller: a008 flash warning";
CM_ SG_ 1294 CP_a008_RAMconst_Warning "Charge port controller: a008 RA mconst warning";
CM_ SG_ 1294 CP_a008_RAMconst_Fault "Charge port controller: a008 RA mconst fault";
CM_ SG_ 1294 CP_a008_AllMemory_warnings "Charge port controller: a008 all memory warnings";
CM_ SG_ 1294 CP_a008_StackAlert "Charge port controller: a008 stack alert";
CM_ SG_ 1294 CP_a008_stackUsed "Charge port controller: a008 stack used";
CM_ SG_ 1294 CP_a009_cover1OpenCounts "Charge port controller: a009 cover1 open counts";
CM_ SG_ 1294 CP_a009_cover2OpenCounts "Charge port controller: a009 cover2 open counts";
CM_ SG_ 1294 CP_a009_cover1State "Charge port controller: a009 cover1 state; raw 5 = signal not available (SNA)";
CM_ SG_ 1294 CP_a009_cover2State "Charge port controller: a009 cover2 state; raw 5 = signal not available (SNA)";
CM_ SG_ 1294 CP_a010_periodValid "Charge port controller: a010 period valid";
CM_ SG_ 1294 CP_a010_widthValid "Charge port controller: a010 width valid";
CM_ SG_ 1294 CP_a010_voltageValid "Charge port controller: a010 voltage valid";
CM_ SG_ 1294 CP_a010_pilotHigh "Charge port controller: a010 pilot high";
CM_ SG_ 1294 CP_a010_pilotLow "Charge port controller: a010 pilot low";
CM_ SG_ 1294 CP_a010_evseAccept "Charge port controller: a010 evse accept";
CM_ SG_ 1294 CP_a010_pilotPWMdetected "Charge port controller: a010 pilot PW mdetected";
CM_ SG_ 1294 CP_a011_eepromErrorType "Charge port controller: a011 eeprom error type";
CM_ SG_ 1294 CP_a015_apsVoltageOV "Charge port controller: a015 aps voltage OV";
CM_ SG_ 1294 CP_a016_apsVoltageUV "Charge port controller: a016 aps voltage UV";
CM_ SG_ 1294 CP_a017_5V_VoltageOV "Charge port controller: a017 5 v voltage OV";
CM_ SG_ 1294 CP_a018_5V_VoltageUV "Charge port controller: a018 5 v voltage UV";
CM_ SG_ 1294 CP_a023_stopChargeReason "Charge port controller: a023 stop charge reason";
CM_ SG_ 1294 CP_a023_failureReason "Charge port controller: a023 failure reason";
CM_ SG_ 1294 CP_a023_chargeAttempts "Charge port controller: a023 charge attempts";
CM_ SG_ 1294 CP_a028_canEnable "Charge port controller: a028 can enable";
CM_ SG_ 1294 CP_a028_hardlineEnable "Charge port controller: a028 hardline enable";
CM_ SG_ 1294 CP_a029_CP_pilot "Charge port controller: a029 CP pilot; raw 7 = signal not available (SNA)";
CM_ SG_ 1294 CP_a029_CP_proximity "Charge port controller: a029 CP proximity; raw 0 = signal not available (SNA)";
CM_ SG_ 1294 CP_a029_CP_chargeDoorOpen "Charge port controller: a029 CP charge door open";
CM_ SG_ 1294 CP_a031_apsVoltage "Charge port controller: a031 aps voltage";
CM_ SG_ 1294 CP_a031_doorCountsFiltered "Charge port controller: a031 door counts filtered";
CM_ SG_ 1294 CP_a031_inductiveSensorFiltered "Charge port controller: a031 inductive sensor filtered";
CM_ SG_ 1294 CP_a031_hallSensorFiltered "Charge port controller: a031 hall sensor filtered";
CM_ SG_ 1294 CP_a032_apsVoltage "Charge port controller: a032 aps voltage";
CM_ SG_ 1294 CP_a032_doorCountsFiltered "Charge port controller: a032 door counts filtered";
CM_ SG_ 1294 CP_a032_inductiveSensorFiltered "Charge port controller: a032 inductive sensor filtered";
CM_ SG_ 1294 CP_a032_hallSensorFiltered "Charge port controller: a032 hall sensor filtered";
CM_ SG_ 1294 CP_a035_latchState "Charge port controller: a035 latch state; raw 0 = signal not available (SNA)";
CM_ SG_ 1294 CP_a035_stateLeverMovedFrom "Charge port controller: a035 state lever moved from";
CM_ SG_ 1294 CP_a035_latchOffset "Charge port controller: a035 latch offset";
CM_ SG_ 1294 CP_a035_inletID "Charge port controller: a035 inlet ID";
CM_ SG_ 1294 CP_a036_latchCountsFiltered "Charge port controller: a036 latch counts filtered";
CM_ SG_ 1294 CP_a036_latchState "Charge port controller: a036 latch state; raw 0 = signal not available (SNA)";
CM_ SG_ 1294 CP_a036_CHG_InsertEnable "Charge port controller: a036 CHG insert enable";
CM_ SG_ 1294 CP_a036_CP_latchEnableCmd "Charge port controller: a036 CP latch enable cmd";
CM_ SG_ 1294 CP_a036_CP_apsVoltage "Charge port controller: a036 CP aps voltage";
CM_ SG_ 1294 CP_a036_inletID "Charge port controller: a036 inlet ID";
CM_ SG_ 1294 CP_a037_latchCountsFiltered "Charge port controller: a037 latch counts filtered";
CM_ SG_ 1294 CP_a037_latchState "Charge port controller: a037 latch state; raw 0 = signal not available (SNA)";
CM_ SG_ 1294 CP_a037_CHG_InsertEnable "Charge port controller: a037 CHG insert enable";
CM_ SG_ 1294 CP_a037_CP_latchEnableCmd "Charge port controller: a037 CP latch enable cmd";
CM_ SG_ 1294 CP_a037_CP_apsVoltage "Charge port controller: a037 CP aps voltage";
CM_ SG_ 1294 CP_a037_inletID "Charge port controller: a037 inlet ID";
CM_ SG_ 1294 CP_a038_latchCountsFiltered "Charge port controller: a038 latch counts filtered";
CM_ SG_ 1294 CP_a038_latchState "Charge port controller: a038 latch state; raw 0 = signal not available (SNA)";
CM_ SG_ 1294 CP_a038_CHG_InsertEnable "Charge port controller: a038 CHG insert enable";
CM_ SG_ 1294 CP_a038_CP_latchEnableCmd "Charge port controller: a038 CP latch enable cmd";
CM_ SG_ 1294 CP_a038_CP_apsVoltage "Charge port controller: a038 CP aps voltage";
CM_ SG_ 1294 CP_a038_inletID "Charge port controller: a038 inlet ID";
CM_ SG_ 1294 CP_a041_doorCounts "Charge port controller: a041 door counts";
CM_ SG_ 1294 CP_a041_inductiveSensorFiltered "Charge port controller: a041 inductive sensor filtered";
CM_ SG_ 1294 CP_a041_hallSensorFiltered "Charge port controller: a041 hall sensor filtered";
CM_ SG_ 1294 CP_a042_doorCounts "Charge port controller: a042 door counts";
CM_ SG_ 1294 CP_a042_inductiveSensorFiltered "Charge port controller: a042 inductive sensor filtered";
CM_ SG_ 1294 CP_a042_hallSensorFiltered "Charge port controller: a042 hall sensor filtered";
CM_ SG_ 1294 CP_a043_driftFlag "Charge port controller: a043 drift flag";
CM_ SG_ 1294 CP_a043_wrongDirectionFlag "Charge port controller: a043 wrong direction flag";
CM_ SG_ 1294 CP_a043_outOfRangeFlag "Charge port controller: a043 out of range flag";
CM_ SG_ 1294 CP_a043_doorPotFiltered "Charge port controller: a043 door pot filtered";
CM_ SG_ 1294 CP_a043_doorVelocity "Charge port controller: a043 door velocity";
CM_ SG_ 1294 CP_a043_idleDoorPot "Charge port controller: a043 idle door pot";
CM_ SG_ 1294 CP_a044_HVP_cpControl_MIA "Charge port controller: a044 HVP cp control MIA";
CM_ SG_ 1294 CP_a045_VCSEC_authentication_MIA "Charge port controller: a045 VCSEC authentication MIA";
CM_ SG_ 1294 CP_a045_VCSEC_requests_MIA "Charge port controller: a045 VCSEC requests MIA";
CM_ SG_ 1294 CP_a046_FC_status_flag "Charge port controller: a046 FC status flag";
CM_ SG_ 1294 CP_a046_FC_limits_flag "Charge port controller: a046 FC limits flag";
CM_ SG_ 1294 CP_a046_FC_maxLimits_flag "Charge port controller: a046 FC max limits flag";
CM_ SG_ 1294 CP_a046_FC_statusHighPower_flag "Charge port controller: a046 FC status high power flag";
CM_ SG_ 1294 CP_a046_FC_limitsHighPower_flag "Charge port controller: a046 FC limits high power flag";
CM_ SG_ 1294 CP_a046_FC_maxLimitsHighPower "Charge port controller: a046 FC max limits high power";
CM_ SG_ 1294 CP_a046_CC_chgStatus_flag "Charge port controller: a046 CC chg status flag";
CM_ SG_ 1294 CP_a047_okToUseHighPower_MIA "Charge port controller: a047 ok to use high power MIA";
CM_ SG_ 1294 CP_a047_LVPowerState_MIA "Charge port controller: a047 LV power state MIA";
CM_ SG_ 1294 CP_a047_sensors_MIA "Charge port controller: a047 sensors MIA";
CM_ SG_ 1294 CP_a047_vehNm_MIA "Charge port controller: a047 veh nm MIA";
CM_ SG_ 1294 CP_a048_UI_chargeRequest_MIA "Charge port controller: a048 UI charge request MIA";
CM_ SG_ 1294 CP_a048_UI_range_MIA "Charge port controller: a048 UI range MIA";
CM_ SG_ 1294 CP_a048_UI_status_MIA "Charge port controller: a048 UI status MIA";
CM_ SG_ 1294 CP_a048_UI_vehicleModes_MIA "Charge port controller: a048 UI vehicle modes MIA";
CM_ SG_ 1294 CP_a048_UI_hvacRequest_MIA "Charge port controller: a048 UI hvac request MIA";
CM_ SG_ 1294 CP_a048_VEH_billing_MIA "Charge port controller: a048 VEH billing MIA";
CM_ SG_ 1294 CP_a049_proximity "Charge port controller: a049 proximity; raw 0 = signal not available (SNA)";
CM_ SG_ 1294 CP_a050_latch1NotConnected "Charge port controller: a050 latch1 not connected";
CM_ SG_ 1294 CP_a050_latch2NotConnected "Charge port controller: a050 latch2 not connected";
CM_ SG_ 1294 CP_a051_doorCountsFiltered "Charge port controller: a051 door counts filtered";
CM_ SG_ 1294 CP_a054_latchCountsFiltered "Charge port controller: a054 latch counts filtered";
CM_ SG_ 1294 CP_a054_latchState "Charge port controller: a054 latch state; raw 0 = signal not available (SNA)";
CM_ SG_ 1294 CP_a054_CHG_InsertEnable "Charge port controller: a054 CHG insert enable";
CM_ SG_ 1294 CP_a054_CP_latchEnableCmd "Charge port controller: a054 CP latch enable cmd";
CM_ SG_ 1294 CP_a054_CP_apsVoltage "Charge port controller: a054 CP aps voltage";
CM_ SG_ 1294 CP_a054_CP_proximity "Charge port controller: a054 CP proximity; raw 0 = signal not available (SNA)";
CM_ SG_ 1294 CP_a054_inletID "Charge port controller: a054 inlet ID";
CM_ SG_ 1294 CP_a056_latchState "Charge port controller: a056 latch state; raw 0 = signal not available (SNA)";
CM_ SG_ 1294 CP_a056_CHG_InsertEnable "Charge port controller: a056 CHG insert enable";
CM_ SG_ 1294 CP_a056_CP_latchEnableCmd "Charge port controller: a056 CP latch enable cmd";
CM_ SG_ 1294 CP_a056_CP_proximity "Charge port controller: a056 CP proximity; raw 0 = signal not available (SNA)";
CM_ SG_ 1294 CP_a056_packCurrent "Charge port controller: a056 pack current";
CM_ SG_ 1294 CP_a058_CP_pilot "Charge port controller: a058 CP pilot; raw 7 = signal not available (SNA)";
CM_ SG_ 1294 CP_a058_CC_pilot "Charge port controller: a058 CC pilot; raw 3 = signal not available (SNA)";
CM_ SG_ 1294 CP_a058_FC_status "Charge port controller: a058 FC status; raw 0 = signal not available (SNA)";
CM_ SG_ 1294 CP_a058_latchState "Charge port controller: a058 latch state; raw 0 = signal not available (SNA)";
CM_ SG_ 1294 CP_a058_CP_proximity "Charge port controller: a058 CP proximity; raw 0 = signal not available (SNA)";
CM_ SG_ 1294 CP_a058_acNumRetries "Charge port controller: a058 ac num retries";
CM_ SG_ 1294 CP_a058_acRetryTimeoutS "Charge port controller: a058 ac retry timeout s";
CM_ SG_ 1294 CP_a060_PCS_chgStatus_MIA "Charge port controller: a060 PCS chg status MIA";
CM_ SG_ 1294 CP_a060_PCS_chgLineStatus_MIA "Charge port controller: a060 PCS chg line status MIA";
CM_ SG_ 1294 CP_a061_controlState "Charge port controller: a061 control state";
CM_ SG_ 1294 CP_a061_lastControlState "Charge port controller: a061 last control state";
CM_ SG_ 1294 CP_a061_chipState "Charge port controller: a061 chip state";
CM_ SG_ 1294 CP_a061_timeMsInControlState "Charge port controller: a061 time ms in control state";
CM_ SG_ 1294 CP_a062_FC_status "Charge port controller: a062 FC status; raw 0 = signal not available (SNA)";
CM_ SG_ 1294 CP_a062_FC_type "Charge port controller: a062 FC type; raw 7 = signal not available (SNA)";
CM_ SG_ 1294 CP_a063_FC_status "Charge port controller: a063 FC status; raw 0 = signal not available (SNA)";
CM_ SG_ 1294 CP_a063_FC_type "Charge port controller: a063 FC type; raw 7 = signal not available (SNA)";
CM_ SG_ 1294 CP_a066_pilotHigh "Charge port controller: a066 pilot high";
CM_ SG_ 1294 CP_a066_pilotLow "Charge port controller: a066 pilot low";
CM_ SG_ 1294 CP_a066_proximity "Charge port controller: a066 proximity; raw 0 = signal not available (SNA)";
CM_ SG_ 1294 CP_a067_cc1Voltage "Charge port controller: a067 cc1 voltage";
CM_ SG_ 1294 CP_a067_cc2Voltage "Charge port controller: a067 cc2 voltage";
CM_ SG_ 1294 CP_a068_doorCountsFiltered "Charge port controller: a068 door counts filtered";
CM_ SG_ 1294 CP_a068_doorClosed "Charge port controller: a068 door closed";
CM_ SG_ 1294 CP_a068_inductiveSensorFiltered "Charge port controller: a068 inductive sensor filtered";
CM_ SG_ 1294 CP_a068_hallSensorFiltered "Charge port controller: a068 hall sensor filtered";
CM_ SG_ 1294 CP_a068_doorPresent "Charge port controller: a068 door present";
CM_ SG_ 1294 CP_a069_inductiveSensor_raw "Charge port controller: a069 inductive sensor raw";
CM_ SG_ 1294 CP_a069_inductiveErrorAmplitude "Charge port controller: a069 inductive error amplitude";
CM_ SG_ 1294 CP_a069_inductiveErrorWatchdog "Charge port controller: a069 inductive error watchdog";
CM_ SG_ 1294 CP_a069_inductiveErrorOverRange "Charge port controller: a069 inductive error over range";
CM_ SG_ 1294 CP_a069_inductiveErrorUnderRange "Charge port controller: a069 inductive error under range";
CM_ SG_ 1294 CP_a070_i2cIBCR "Charge port controller: a070 i2c IBCR";
CM_ SG_ 1294 CP_a070_i2cIBSR "Charge port controller: a070 i2c IBSR";
CM_ SG_ 1294 CP_a071_expectedMessage "Charge port controller: a071 expected message";
CM_ SG_ 1294 CP_a072_currentMessage "Charge port controller: a072 current message";
CM_ SG_ 1294 CP_a072_readyToChargeExpired "Charge port controller: a072 ready to charge expired";
CM_ SG_ 1294 CP_a072_commsSetupExpired "Charge port controller: a072 comms setup expired";
CM_ SG_ 1294 CP_a072_cableCheckExpired "Charge port controller: a072 cable check expired";
CM_ SG_ 1294 CP_a072_preChargeExpired "Charge port controller: a072 pre charge expired";
CM_ SG_ 1294 CP_a073_ccsManagerState "Charge port controller: a073 ccs manager state";
CM_ SG_ 1294 CP_a073_ccsDcState "Charge port controller: a073 ccs dc state";
CM_ SG_ 1294 CP_a073_ccsShutdownReason "Charge port controller: a073 ccs shutdown reason";
CM_ SG_ 1294 CP_a073_comboHandleNotPresent "Charge port controller: a073 combo handle not present";
CM_ SG_ 1294 CP_a073_commsFault "Charge port controller: a073 comms fault";
CM_ SG_ 1294 CP_a073_bmsShutdownRequested "Charge port controller: a073 bms shutdown requested";
CM_ SG_ 1294 CP_a073_evseShutdownRequested "Charge port controller: a073 evse shutdown requested";
CM_ SG_ 1294 CP_a073_cpInternalStopChgRequest "Charge port controller: a073 cp internal stop chg request";
CM_ SG_ 1294 CP_a073_v2gCommsEstablished "Charge port controller: a073 v2g comms established";
CM_ SG_ 1294 CP_a073_emergencyShutdown "Charge port controller: a073 emergency shutdown";
CM_ SG_ 1294 CP_a073_servicesNotSupported "Charge port controller: a073 services not supported";
CM_ SG_ 1294 CP_a073_ccs1AdapterBtnPress "Charge port controller: a073 ccs1 adapter btn press";
CM_ SG_ 1294 CP_a074_slacState "Charge port controller: a074 slac state";
CM_ SG_ 1294 CP_a074_slacErrorCode "Charge port controller: a074 slac error code";
CM_ SG_ 1294 CP_a074_sdpNoDiscoveryResponse "Charge port controller: a074 sdp no discovery response";
CM_ SG_ 1294 CP_a074_evseMeasuredAtten "Charge port controller: a074 evse measured atten";
CM_ SG_ 1294 CP_a075_evccState "Charge port controller: a075 evcc state";
CM_ SG_ 1294 CP_a075_currentMessage "Charge port controller: a075 current message";
CM_ SG_ 1294 CP_a075_exiUnpackFailed "Charge port controller: a075 exi unpack failed";
CM_ SG_ 1294 CP_a075_failedResponseCode "Charge port controller: a075 failed response code";
CM_ SG_ 1294 CP_a075_evseMeasuredAtten "Charge port controller: a075 evse measured atten";
CM_ SG_ 1294 CP_a075_evseEmergencyChgEnd "Charge port controller: a075 evse emergency chg end";
CM_ SG_ 1294 CP_a075_initFailureType "Charge port controller: a075 init failure type";
CM_ SG_ 1294 CP_a077_mac1Invalid "Charge port controller: a077 mac1 invalid";
CM_ SG_ 1294 CP_a077_mac2Invalid "Charge port controller: a077 mac2 invalid";
CM_ SG_ 1294 CP_a077_macsMatching "Charge port controller: a077 macs matching";
CM_ SG_ 1294 CP_a078_VC_tempAmbientFiltered "Charge port controller: a078 VC temp ambient filtered; raw 0 = signal not available (SNA)";
CM_ SG_ 1294 CP_a078_pinTemperature1 "Charge port controller: a078 pin temperature1; raw 255 = signal not available (SNA)";
CM_ SG_ 1294 CP_a078_pinTemperature2 "Charge port controller: a078 pin temperature2; raw 255 = signal not available (SNA)";
CM_ SG_ 1294 CP_a078_pinTemperature3 "Charge port controller: a078 pin temperature3; raw 255 = signal not available (SNA)";
CM_ SG_ 1294 CP_a079_VC_tempAmbientFiltered "Charge port controller: a079 VC temp ambient filtered; raw 0 = signal not available (SNA)";
CM_ SG_ 1294 CP_a079_pinTemperature1 "Charge port controller: a079 pin temperature1; raw 255 = signal not available (SNA)";
CM_ SG_ 1294 CP_a079_pinTemperature2 "Charge port controller: a079 pin temperature2; raw 255 = signal not available (SNA)";
CM_ SG_ 1294 CP_a079_pinTemperature3 "Charge port controller: a079 pin temperature3; raw 255 = signal not available (SNA)";
CM_ SG_ 1294 CP_a084_proximityV "Charge port controller: a084 proximity v";
CM_ SG_ 1294 CP_a084_cc1Voltage "Charge port controller: a084 cc1 voltage";
CM_ SG_ 1294 CP_a084_cc2Voltage "Charge port controller: a084 cc2 voltage";
CM_ SG_ 1294 CP_a085_absoluteTempFault "Charge port controller: a085 absolute temp fault";
CM_ SG_ 1294 CP_a085_dcPinTemp "Charge port controller: a085 dc pin temp";
CM_ SG_ 1294 CP_a086_dcPinTemp "Charge port controller: a086 dc pin temp";
CM_ SG_ 1294 CP_a089_gtwPlcSupportType "Charge port controller: a089 gtw plc support type";
CM_ SG_ 1294 CP_a089_plcModemPopulated "Charge port controller: a089 plc modem populated";
CM_ SG_ 1294 CP_a090_evseIsoStatus "Charge port controller: a090 evse iso status";
CM_ SG_ 1294 CP_a090_ccsDcState "Charge port controller: a090 ccs dc state";
CM_ SG_ 1294 CP_a091_fcType "Charge port controller: a091 fc type; raw 7 = signal not available (SNA)";
CM_ SG_ 1294 CP_a093_appLoadingNumRetries "Charge port controller: a093 app loading num retries";
CM_ SG_ 1294 CP_a093_interruptCauseRegError "Charge port controller: a093 interrupt cause reg error";
CM_ SG_ 1294 CP_a094_faultResetCount "Charge port controller: a094 fault reset count";
CM_ SG_ 1294 CP_a095_packCurrent "Charge port controller: a095 pack current";
CM_ SG_ 1294 CP_a095_dcOutputCurrent "Charge port controller: a095 dc output current";
CM_ SG_ 1294 CP_a095_ambientTemp "Charge port controller: a095 ambient temp";
CM_ SG_ 1294 CP_a095_fcType "Charge port controller: a095 fc type; raw 7 = signal not available (SNA)";
CM_ SG_ 1294 CP_a095_fcBrand "Charge port controller: a095 fc brand; raw 0 = signal not available (SNA)";
CM_ SG_ 1294 CP_a099_proximity "Charge port controller: a099 proximity; raw 0 = signal not available (SNA)";
CM_ SG_ 1294 CP_a099_pilot "Charge port controller: a099 pilot; raw 7 = signal not available (SNA)";
CM_ SG_ 1294 CP_a103_proximityV "Charge port controller: a103 proximity v";
CM_ SG_ 1294 CP_a109_thermistorId "Charge port controller: a109 thermistor id";
CM_ SG_ 1294 CP_a109_thermistorTemp "Charge port controller: a109 thermistor temp";
CM_ SG_ 1294 CP_a110_thermistorId "Charge port controller: a110 thermistor id";
CM_ SG_ 1294 CP_a110_thermistorTemp "Charge port controller: a110 thermistor temp";
CM_ SG_ 1294 CP_a110_thermalVelocity "Charge port controller: a110 thermal velocity; raw 511 = signal not available (SNA)";
CM_ SG_ 1294 CP_a111_heaterTemperature "Charge port controller: a111 heater temperature; raw 255 = signal not available (SNA)";
CM_ SG_ 1294 CP_a111_VC_tempAmbientFiltered "Charge port controller: a111 VC temp ambient filtered; raw 0 = signal not available (SNA)";
CM_ SG_ 1294 CP_a112_heaterTemperature "Charge port controller: a112 heater temperature; raw 255 = signal not available (SNA)";
CM_ SG_ 1294 CP_a113_heaterTemperature "Charge port controller: a113 heater temperature; raw 255 = signal not available (SNA)";
CM_ SG_ 1294 CP_a113_heaterCurrent "Charge port controller: a113 heater current";
CM_ SG_ 1294 CP_a116_hvCoverDetected "Charge port controller: a116 hv cover detected";
CM_ SG_ 1294 CP_a116_heaterDetected "Charge port controller: a116 heater detected";
CM_ SG_ 1294 CP_a116_temperatureSensorMismatc "Charge port controller: a116 temperature sensor mismatch";
CM_ SG_ 1294 CP_a116_thermistorsOpenCircuit "Charge port controller: a116 thermistors open circuit";
CM_ SG_ 1294 CP_a117_heaterTemperature "Charge port controller: a117 heater temperature; raw 255 = signal not available (SNA)";
CM_ SG_ 1294 CP_a117_averageError "Charge port controller: a117 average error; raw 255 = signal not available (SNA)";
CM_ SG_ 1294 CP_a120_oldProximtyV "Charge port controller: a120 old proximty v";
CM_ SG_ 1294 CP_a120_newProximtyV "Charge port controller: a120 new proximty v";
CM_ SG_ 1294 CP_a120_chargeVoltage "Charge port controller: a120 charge voltage";
CM_ SG_ 1294 CP_a120_chargeCurrent "Charge port controller: a120 charge current";
CM_ SG_ 1294 CP_a120_dcPinTemp "Charge port controller: a120 dc pin temp; raw 255 = signal not available (SNA)";
CM_ SG_ 1294 CP_a121_CP_status_MIA "Charge port controller: a121 CP status MIA";
CM_ SG_ 1294 CP_a124_ivledState "Charge port controller: a124 ivled state";
CM_ SG_ 1294 CP_a124_ivledVoltage "Charge port controller: a124 ivled voltage";
CM_ SG_ 1294 CP_a125_okToUseHighPower "Charge port controller: a125 ok to use high power";
CM_ SG_ 1294 CP_a127_HVLINK_cpControl_MIA "Charge port controller: a127 HVLINK cp control MIA";
CM_ SG_ 1294 CP_a129_bldcDriverState "Charge port controller: a129 bldc driver state";
CM_ SG_ 1294 CP_a130_retryCount "Charge port controller: a130 retry count";
CM_ SG_ 1294 CP_a131_chargeProtocol "Charge port controller: a131 charge protocol";
CM_ SG_ 1294 CP_a135_sdpErr "Charge port controller: a135 sdp err";
CM_ SG_ 1294 CP_a135_pilotState "Charge port controller: a135 pilot state; raw 7 = signal not available (SNA)";
CM_ SG_ 1294 CP_a135_evseMeasuredAtten "Charge port controller: a135 evse measured atten";
CM_ SG_ 1294 CP_a138_FC_type "Charge port controller: a138 FC type; raw 7 = signal not available (SNA)";
CM_ SG_ 1294 CP_a138_latchState "Charge port controller: a138 latch state; raw 0 = signal not available (SNA)";
CM_ SG_ 1294 CP_a138_CP_proximity "Charge port controller: a138 CP proximity; raw 0 = signal not available (SNA)";
CM_ SG_ 1294 CP_a139_latchState "Charge port controller: a139 latch state; raw 0 = signal not available (SNA)";
CM_ SG_ 1294 CP_a139_CP_proximity "Charge port controller: a139 CP proximity; raw 0 = signal not available (SNA)";
CM_ SG_ 1294 CP_a140_latchState "Charge port controller: a140 latch state; raw 0 = signal not available (SNA)";
CM_ SG_ 1294 CP_a140_CP_proximity "Charge port controller: a140 CP proximity; raw 0 = signal not available (SNA)";
CM_ SG_ 1294 CP_a141_latchState "Charge port controller: a141 latch state; raw 0 = signal not available (SNA)";
CM_ SG_ 1294 CP_a141_CP_proximity "Charge port controller: a141 CP proximity; raw 0 = signal not available (SNA)";
CM_ SG_ 1294 CP_a142_cc1Voltage "Charge port controller: a142 cc1 voltage";
CM_ SG_ 1294 CP_a142_cc2Voltage "Charge port controller: a142 cc2 voltage";
CM_ SG_ 1294 CP_a143_versionDetected "Charge port controller: a143 version detected";
CM_ SG_ 1294 CP_a146_v2gMessage "Charge port controller: a146 v2g message";
CM_ SG_ 1294 CP_a151_pilotHighMin "Charge port controller: a151 pilot high min";
CM_ SG_ 1294 CP_a151_pilotHighMax "Charge port controller: a151 pilot high max";
CM_ SG_ 1294 CP_a151_pilotLowMin "Charge port controller: a151 pilot low min";
CM_ SG_ 1294 CP_a151_pilotLowMax "Charge port controller: a151 pilot low max";
CM_ SG_ 1294 CP_a152_swcanHighMismatchCount "Charge port controller: a152 swcan high mismatch count";
CM_ SG_ 1294 CP_a152_swcanLowMismatchCount "Charge port controller: a152 swcan low mismatch count";
CM_ SG_ 1294 CP_a152_maxPilotSwcanHigh "Charge port controller: a152 max pilot swcan high";
CM_ SG_ 1294 CP_a152_minPilotSwcanHigh "Charge port controller: a152 min pilot swcan high";
CM_ SG_ 1294 CP_a152_maxPilotSwcanLow "Charge port controller: a152 max pilot swcan low";
CM_ SG_ 1294 CP_a152_minPilotSwcanLow "Charge port controller: a152 min pilot swcan low";
CM_ SG_ 1294 CP_a153_acPinTempVelocity "Charge port controller: a153 ac pin temp velocity; raw 511 = signal not available (SNA)";
CM_ SG_ 1294 CP_a153_acPinTemp1 "Charge port controller: a153 ac pin temp1; raw 255 = signal not available (SNA)";
CM_ SG_ 1294 CP_a153_acPinTemp2 "Charge port controller: a153 ac pin temp2; raw 255 = signal not available (SNA)";
CM_ SG_ 1294 CP_a153_ambientTemp "Charge port controller: a153 ambient temp";
CM_ SG_ 1294 CP_a153_pcsLineChargeCurrent "Charge port controller: a153 pcs line charge current";
CM_ SG_ 1294 CP_a154_acPinTempVelocity "Charge port controller: a154 ac pin temp velocity; raw 511 = signal not available (SNA)";
CM_ SG_ 1294 CP_a154_acPinTemp1 "Charge port controller: a154 ac pin temp1; raw 255 = signal not available (SNA)";
CM_ SG_ 1294 CP_a154_acPinTemp2 "Charge port controller: a154 ac pin temp2; raw 255 = signal not available (SNA)";
CM_ SG_ 1294 CP_a154_ambientTemp "Charge port controller: a154 ambient temp";
CM_ SG_ 1294 CP_a154_pcsLineChargeCurrent "Charge port controller: a154 pcs line charge current";
CM_ SG_ 1294 CP_a155_hallSensorVoltage "Charge port controller: a155 hall sensor voltage";
CM_ SG_ 1294 CP_a161_pilotHighMin "Charge port controller: a161 pilot high min";
CM_ SG_ 1294 CP_a161_pilotHighMax "Charge port controller: a161 pilot high max";
CM_ SG_ 1294 CP_a161_pilotLowMin "Charge port controller: a161 pilot low min";
CM_ SG_ 1294 CP_a161_pilotLowMax "Charge port controller: a161 pilot low max";
CM_ SG_ 1294 CP_a162_swcanHighMismatchCount "Charge port controller: a162 swcan high mismatch count";
CM_ SG_ 1294 CP_a162_swcanLowMismatchCount "Charge port controller: a162 swcan low mismatch count";
CM_ SG_ 1294 CP_a162_maxPilotSwcanHigh "Charge port controller: a162 max pilot swcan high";
CM_ SG_ 1294 CP_a162_minPilotSwcanHigh "Charge port controller: a162 min pilot swcan high";
CM_ SG_ 1294 CP_a162_maxPilotSwcanLow "Charge port controller: a162 max pilot swcan low";
CM_ SG_ 1294 CP_a162_minPilotSwcanLow "Charge port controller: a162 min pilot swcan low";
CM_ SG_ 1294 CP_a163_cover1OpenCounts "Charge port controller: a163 cover1 open counts";
CM_ SG_ 1294 CP_a163_cover2OpenCounts "Charge port controller: a163 cover2 open counts";
CM_ SG_ 1294 CP_a163_cover1State "Charge port controller: a163 cover1 state; raw 5 = signal not available (SNA)";
CM_ SG_ 1294 CP_a163_cover2State "Charge port controller: a163 cover2 state; raw 5 = signal not available (SNA)";
CM_ SG_ 1294 CP_a164_VC_tempAmbientFiltered "Charge port controller: a164 VC temp ambient filtered; raw 0 = signal not available (SNA)";
CM_ SG_ 1294 CP_a164_minInternalPinTemp "Charge port controller: a164 min internal pin temp; raw 255 = signal not available (SNA)";
CM_ SG_ 1294 CP_a173_cover1OpenCounts "Charge port controller: a173 cover1 open counts";
CM_ SG_ 1294 CP_a173_cover2OpenCounts "Charge port controller: a173 cover2 open counts";
CM_ SG_ 1294 CP_a173_cover1State "Charge port controller: a173 cover1 state; raw 5 = signal not available (SNA)";
CM_ SG_ 1294 CP_a173_cover2State "Charge port controller: a173 cover2 state; raw 5 = signal not available (SNA)";
CM_ BO_ 798 "Charge port controller message: alert matrix";
CM_ SG_ 798 CP_matrixIndex "Charge port controller: matrix index";
CM_ SG_ 798 CP_a001_canRx "Charge port controller: a001 can rx";
CM_ SG_ 798 CP_a002_canTx "Charge port controller: a002 can tx";
CM_ SG_ 798 CP_a003_canError "Charge port controller: a003 can error";
CM_ SG_ 798 CP_a004_proximityRationality "Charge port controller: a004 proximity rationality";
CM_ SG_ 798 CP_a005_gbdcLiveDisconnect "Charge port controller: a005 gbdc live disconnect";
CM_ SG_ 798 CP_a006_lostCommsBMS "Charge port controller: a006 lost comms BMS";
CM_ SG_ 798 CP_a007_watchdog "Charge port controller: a007 watchdog";
CM_ SG_ 798 CP_a008_memoryError "Charge port controller: a008 memory error";
CM_ SG_ 798 CP_a009_coverOpenAllChgBlocked "Charge port controller: a009 cover open all chg blocked";
CM_ SG_ 798 CP_a010_pilotRationality "Charge port controller: a010 pilot rationality";
CM_ SG_ 798 CP_a011_eeprom "Charge port controller: a011 eeprom";
CM_ SG_ 798 CP_a012_ledDriver "Charge port controller: a012 led driver";
CM_ SG_ 798 CP_a013_lostCommsGTW "Charge port controller: a013 lost comms GTW";
CM_ SG_ 798 CP_a014_lostCommsCHG "Charge port controller: a014 lost comms CHG";
CM_ SG_ 798 CP_a015_apsVov "Charge port controller: a015 aps vov";
CM_ SG_ 798 CP_a016_apsVuv "Charge port controller: a016 aps vuv";
CM_ SG_ 798 CP_a017_fiveVov "Charge port controller: a017 five vov";
CM_ SG_ 798 CP_a018_fiveVuv "Charge port controller: a018 five vuv";
CM_ SG_ 798 CP_a019_threeVov "Charge port controller: a019 three vov";
CM_ SG_ 798 CP_a020_threeVuv "Charge port controller: a020 three vuv";
CM_ SG_ 798 CP_a021_zeroVov "Charge port controller: a021 zero vov";
CM_ SG_ 798 CP_a022_zeroVuv "Charge port controller: a022 zero vuv";
CM_ SG_ 798 CP_a023_gbdcSessionFailed "Charge port controller: a023 gbdc session failed";
CM_ SG_ 798 CP_a024_ledsUC "Charge port controller: a024 leds UC";
CM_ SG_ 798 CP_a025_ledsOC "Charge port controller: a025 leds OC";
CM_ SG_ 798 CP_a026_networkManagement "Charge port controller: a026 network management";
CM_ SG_ 798 CP_a027_doorSensorOutOfSpec "Charge port controller: a027 door sensor out of spec";
CM_ SG_ 798 CP_a028_insertEnableMismatch "Charge port controller: a028 insert enable mismatch";
CM_ SG_ 798 CP_a029_doorClosedProxPilot "Charge port controller: a029 door closed prox pilot";
CM_ SG_ 798 CP_a030_busOff "Charge port controller: a030 bus off";
CM_ SG_ 798 CP_a031_doorClosedCommandedOpen "Charge port controller: a031 door closed commanded open";
CM_ SG_ 798 CP_a032_doorOpenExpectedClosed "Charge port controller: a032 door open expected closed";
CM_ SG_ 798 CP_a033_spiOpen "Charge port controller: a033 spi open";
CM_ SG_ 798 CP_a034_calibrationIncomplete "Charge port controller: a034 calibration incomplete";
CM_ SG_ 798 CP_a035_latchMovement_1 "Charge port controller: a035 latch movement 1";
CM_ SG_ 798 CP_a036_latchNotDisengaged "Charge port controller: a036 latch not disengaged";
CM_ SG_ 798 CP_a037_latchNotEngaged "Charge port controller: a037 latch not engaged";
CM_ SG_ 798 CP_a038_latchNotBlocking "Charge port controller: a038 latch not blocking";
CM_ SG_ 798 CP_a039_latchMovement_2 "Charge port controller: a039 latch movement 2";
CM_ SG_ 798 CP_a040_doNotUse "Charge port controller: a040 do not use";
CM_ SG_ 798 CP_a041_doorSensorUnplugged "Charge port controller: a041 door sensor unplugged";
CM_ SG_ 798 CP_a042_doorAssemblyBroken "Charge port controller: a042 door assembly broken";
CM_ SG_ 798 CP_a043_doorPotIrrational "Charge port controller: a043 door pot irrational";
CM_ SG_ 798 CP_a044_lostCommsHVP "Charge port controller: a044 lost comms HVP";
CM_ SG_ 798 CP_a045_lostCommsVCSEC "Charge port controller: a045 lost comms VCSEC";
CM_ SG_ 798 CP_a046_lostCommsEVSE "Charge port controller: a046 lost comms EVSE";
CM_ SG_ 798 CP_a047_lostCommsVCFRONT "Charge port controller: a047 lost comms VCFRONT";
CM_ SG_ 798 CP_a048_lostCommsUI "Charge port controller: a048 lost comms UI";
CM_ SG_ 798 CP_a049_multipleCablesDetected "Charge port controller: a049 multiple cables detected";
CM_ SG_ 798 CP_a050_latchNotConnected "Charge port controller: a050 latch not connected";
CM_ SG_ 798 CP_a051_doorInductiveSensorMIA "Charge port controller: a051 door inductive sensor MIA";
CM_ SG_ 798 CP_a052_chademoNotSupported "Charge port controller: a052 chademo not supported";
CM_ SG_ 798 CP_a053_proxLatchedNoPilot "Charge port controller: a053 prox latched no pilot";
CM_ SG_ 798 CP_a054_cableNotSecured "Charge port controller: a054 cable not secured";
CM_ SG_ 798 CP_a055_chargeStoppedNoPilot "Charge port controller: a055 charge stopped no pilot";
CM_ SG_ 798 CP_a056_proxDisconnected "Charge port controller: a056 prox disconnected";
CM_ SG_ 798 CP_a057_ccs1AdapterBtnPress "Charge port controller: a057 ccs1 adapter btn press";
CM_ SG_ 798 CP_a058_acChargeRetryPending "Charge port controller: a058 ac charge retry pending";
CM_ SG_ 798 CP_a059_swcanError "Charge port controller: a059 swcan error";
CM_ SG_ 798 CP_a060_lostCommsPCS "Charge port controller: a060 lost comms PCS";
CM_ SG_ 798 CP_a061_uhfReceiverMIA "Charge port controller: a061 uhf receiver MIA";
CM_ SG_ 798 CP_a062_scOutOfService "Charge port controller: a062 sc out of service";
CM_ SG_ 798 CP_a063_scUpdateInProgress "Charge port controller: a063 sc update in progress";
CM_ SG_ 798 CP_a064_superchargingBlocked "Charge port controller: a064 supercharging blocked";
CM_ SG_ 798 CP_a065_selfTestFailed "Charge port controller: a065 self test failed";
CM_ SG_ 798 CP_a066_proxLatchedIdlePilot "Charge port controller: a066 prox latched idle pilot";
CM_ SG_ 798 CP_a067_gbdcConnFault "Charge port controller: a067 gbdc conn fault";
CM_ SG_ 798 CP_a068_doorSensorMismatch "Charge port controller: a068 door sensor mismatch";
CM_ SG_ 798 CP_a069_doorInductiveSensorError "Charge port controller: a069 door inductive sensor error";
CM_ SG_ 798 CP_a070_doorInductiveSensorReset "Charge port controller: a070 door inductive sensor reset";
CM_ SG_ 798 CP_a071_exiDecodeFailure "Charge port controller: a071 exi decode failure";
CM_ SG_ 798 CP_a072_v2gEvccTimeout "Charge port controller: a072 v2g evcc timeout";
CM_ SG_ 798 CP_a073_iecComboShutdown "Charge port controller: a073 iec combo shutdown";
CM_ SG_ 798 CP_a074_failedToEstablishV2gComm "Charge port controller: a074 failed to establish v2g comm";
CM_ SG_ 798 CP_a075_v2gCommsFailure "Charge port controller: a075 v2g comms failure";
CM_ SG_ 798 CP_a076_LDC1612errorWatchdog "Charge port controller: a076 ldc1612error watchdog";
CM_ SG_ 798 CP_a077_invalidMacAddress "Charge port controller: a077 invalid mac address";
CM_ SG_ 798 CP_a078_latchNotDisengagedCold "Charge port controller: a078 latch not disengaged cold";
CM_ SG_ 798 CP_a079_cableNotSecuredCold "Charge port controller: a079 cable not secured cold";
CM_ SG_ 798 CP_a080_taskStackOverflow "Charge port controller: a080 task stack overflow";
CM_ SG_ 798 CP_a081_swException "Charge port controller: a081 sw exception";
CM_ SG_ 798 CP_a082_powerOnReset "Charge port controller: a082 power on reset";
CM_ SG_ 798 CP_a083_watchdogTraceData "Charge port controller: a083 watchdog trace data";
CM_ SG_ 798 CP_a084_proxPeDisconnected_gb "Charge port controller: a084 prox pe disconnected gb";
CM_ SG_ 798 CP_a085_dcPinTempFaulted "Charge port controller: a085 dc pin temp faulted";
CM_ SG_ 798 CP_a086_dcPinTempIrrational "Charge port controller: a086 dc pin temp irrational";
CM_ SG_ 798 CP_a087_dcTempModelFault "Charge port controller: a087 dc temp model fault";
CM_ SG_ 798 CP_a088_dcTempModelDeviation "Charge port controller: a088 dc temp model deviation";
CM_ SG_ 798 CP_a089_plcConfigMismatch "Charge port controller: a089 plc config mismatch";
CM_ SG_ 798 CP_a090_ccsEvseLowIso "Charge port controller: a090 ccs evse low iso";
CM_ SG_ 798 CP_a091_wrongSuperchargerHandle "Charge port controller: a091 wrong supercharger handle";
CM_ SG_ 798 CP_a092_modemAppLoadFailed "Charge port controller: a092 modem app load failed";
CM_ SG_ 798 CP_a093_modemLoadedWithReset "Charge port controller: a093 modem loaded with reset";
CM_ SG_ 798 CP_a094_inductiveResetSuccessful "Charge port controller: a094 inductive reset successful";
CM_ SG_ 798 CP_a095_thermalDcLimitActive "Charge port controller: a095 thermal dc limit active";
CM_ SG_ 798 CP_a096_pilotWake "Charge port controller: a096 pilot wake";
CM_ SG_ 798 CP_a097_modeTransitionFailure "Charge port controller: a097 mode transition failure";
CM_ SG_ 798 CP_a098_proximityWake "Charge port controller: a098 proximity wake";
CM_ SG_ 798 CP_a099_cableStateUnknown "Charge port controller: a099 cable state unknown";
CM_ SG_ 798 CP_a100_inletHarnessIdIrrational "Charge port controller: a100 inlet harness id irrational";
CM_ SG_ 798 CP_a101_wcFoldbackActive "Charge port controller: a101 wc foldback active";
CM_ SG_ 798 CP_a102_wcOvertempFault "Charge port controller: a102 wc overtemp fault";
CM_ SG_ 798 CP_a103_proximityPeDisconnected "Charge port controller: a103 proximity pe disconnected";
CM_ SG_ 798 CP_a104_uhfResetSuccessful "Charge port controller: a104 uhf reset successful";
CM_ SG_ 798 CP_a105_hwUnableToSleep "Charge port controller: a105 hw unable to sleep";
CM_ SG_ 798 CP_a106_uhfReceiverReset "Charge port controller: a106 uhf receiver reset";
CM_ SG_ 798 CP_a107_chademoFoldbackActive "Charge port controller: a107 chademo foldback active";
CM_ SG_ 798 CP_a108_chademoOvertempFault "Charge port controller: a108 chademo overtemp fault";
CM_ SG_ 798 CP_a109_thermistorIrrational "Charge port controller: a109 thermistor irrational";
CM_ SG_ 798 CP_a110_thermalVelocityHigh "Charge port controller: a110 thermal velocity high";
CM_ SG_ 798 CP_a111_inletHeaterUnableToHeat "Charge port controller: a111 inlet heater unable to heat";
CM_ SG_ 798 CP_a112_inletHeaterIrrationalTem "Charge port controller: a112 inlet heater irrational temperature";
CM_ SG_ 798 CP_a113_inletHeaterShortCircuit "Charge port controller: a113 inlet heater short circuit";
CM_ SG_ 798 CP_a114_ccsEvseFailed "Charge port controller: a114 ccs evse failed";
CM_ SG_ 798 CP_a115_unexpectedTcan1145State "Charge port controller: a115 unexpected tcan1145 state";
CM_ SG_ 798 CP_a116_misconfigurationDetected "Charge port controller: a116 misconfiguration detected";
CM_ SG_ 798 CP_a117_inletHeaterUnableToRegul "Charge port controller: a117 inlet heater unable to regulate";
CM_ SG_ 798 CP_a118_iecComboLockUp "Charge port controller: a118 iec combo lock up";
CM_ SG_ 798 CP_a119_plcTransmitFailure "Charge port controller: a119 plc transmit failure";
CM_ SG_ 798 CP_a120_comboAdapterFoldback "Charge port controller: a120 combo adapter foldback";
CM_ SG_ 798 CP_a121_PLCRLY_lostCommsCP "Charge port controller: a121 PLCRLY lost comms CP";
CM_ SG_ 798 CP_a122_plcModemFailure "Charge port controller: a122 plc modem failure";
CM_ SG_ 798 CP_a123_latchPotIrrational "Charge port controller: a123 latch pot irrational";
CM_ SG_ 798 CP_a124_ivledFault "Charge port controller: a124 ivled fault";
CM_ SG_ 798 CP_a125_unexpectedLVJuiceState "Charge port controller: a125 unexpected LV juice state";
CM_ SG_ 798 CP_a126_wakeOnUhfFault "Charge port controller: a126 wake on uhf fault";
CM_ SG_ 798 CP_a127_lostCommsHVLINK "Charge port controller: a127 lost comms HVLINK";
CM_ SG_ 798 CP_a128_lostCommsVC "Charge port controller: a128 lost comms VC";
CM_ SG_ 798 CP_a129_bldcDriverCommsFailed "Charge port controller: a129 bldc driver comms failed";
CM_ SG_ 798 CP_a130_bldcDriverCommsRecovered "Charge port controller: a130 bldc driver comms recovered";
CM_ SG_ 798 CP_a131_evseCommTimeout "Charge port controller: a131 evse comm timeout";
CM_ SG_ 798 CP_a132_contractAuthTimeout "Charge port controller: a132 contract auth timeout";
CM_ SG_ 798 CP_a133_proxNeverLatched "Charge port controller: a133 prox never latched";
CM_ SG_ 798 CP_a134_plcModemNotExpected "Charge port controller: a134 plc modem not expected";
CM_ SG_ 798 CP_a135_sdpAttemptsFailed "Charge port controller: a135 sdp attempts failed";
CM_ SG_ 798 CP_a136_sdpSideReqFailed "Charge port controller: a136 sdp side req failed";
CM_ SG_ 798 CP_a137_plcForwardError "Charge port controller: a137 plc forward error";
CM_ SG_ 798 CP_a138_swcanCommsAcEvseFaulted "Charge port controller: a138 swcan comms ac evse faulted";
CM_ SG_ 798 CP_a139_pilotFaulted "Charge port controller: a139 pilot faulted";
CM_ SG_ 798 CP_a140_superchargerFaulted "Charge port controller: a140 supercharger faulted";
CM_ SG_ 798 CP_a141_chademoAdapterFault "Charge port controller: a141 chademo adapter fault";
CM_ SG_ 798 CP_a142_gbdcScConnFault "Charge port controller: a142 gbdc sc conn fault";
CM_ SG_ 798 CP_a143_unsupportedChargeAdapter "Charge port controller: a143 unsupported charge adapter";
CM_ SG_ 798 CP_a144_nvmInitFailed "Charge port controller: a144 nvm init failed";
CM_ SG_ 798 CP_a145_modemAppLoadFailedNA "Charge port controller: a145 modem app load failed NA";
CM_ SG_ 798 CP_a146_ccsEvseMalfunction "Charge port controller: a146 ccs evse malfunction";
CM_ SG_ 798 CP_a147_inductiveRecoveredMia "Charge port controller: a147 inductive recovered mia";
CM_ SG_ 798 CP_a148_bldcTachFeedbackMia "Charge port controller: a148 bldc tach feedback mia";
CM_ SG_ 798 CP_a149_pilotPeriodInvalid "Charge port controller: a149 pilot period invalid";
CM_ SG_ 798 CP_a150_railToggleTimeout "Charge port controller: a150 rail toggle timeout";
CM_ SG_ 798 CP_a151_badPilotDiodeDetected "Charge port controller: a151 bad pilot diode detected";
CM_ SG_ 798 CP_a152_pilotEdgeDetectionFailed "Charge port controller: a152 pilot edge detection failed";
CM_ SG_ 798 CP_a153_thermalAcLimitActive "Charge port controller: a153 thermal ac limit active";
CM_ SG_ 798 CP_a154_acChargingStoppedOT "Charge port controller: a154 ac charging stopped OT";
CM_ SG_ 798 CP_a155_hallPresenceRationality "Charge port controller: a155 hall presence rationality";
CM_ SG_ 798 CP_a156_gbdcPrechargingConcern "Charge port controller: a156 gbdc precharging concern";
CM_ SG_ 798 CP_a157_doorOpenRateLimiter "Charge port controller: a157 door open rate limiter";
CM_ SG_ 798 CP_a158_doorCloseRateLimiter "Charge port controller: a158 door close rate limiter";
CM_ SG_ 798 CP_a159_swcanHealthCheckFailed "Charge port controller: a159 swcan health check failed";
CM_ SG_ 798 CP_a160_latchDisengageInDcCharge "Charge port controller: a160 latch disengage in dc charge";
CM_ SG_ 798 CP_a161_badPilotDiodeDetectedCN "Charge port controller: a161 bad pilot diode detected CN";
CM_ SG_ 798 CP_a162_pilotEdgeDetectionFailed "Charge port controller: a162 pilot edge detection failed CN";
CM_ SG_ 798 CP_a163_coverOpenDcChgBlocked "Charge port controller: a163 cover open dc chg blocked";
CM_ SG_ 798 CP_a164_latchRedisengageRequeste "Charge port controller: a164 latch redisengage requested";
CM_ SG_ 798 CP_a165_proxWiggleDetected "Charge port controller: a165 prox wiggle detected";
CM_ SG_ 798 CP_a166_faultLineMismatchDetecte "Charge port controller: a166 fault line mismatch detected";
CM_ SG_ 798 CP_a167_doorIdIrrational "Charge port controller: a167 door id irrational";
CM_ SG_ 798 CP_a172_triggerOdin "Signal reported by Charge port controller";
CM_ SG_ 798 CP_a173_coverOpenAcChgBlocked "Charge port controller: a173 cover open ac chg blocked";
CM_ SG_ 798 CP_a174_fwdedMsgLoadWarning "Charge port controller: a174 fwded msg load warning";
CM_ SG_ 798 CP_a175_fwdedMsgDropped "Charge port controller: a175 fwded msg dropped";
CM_ SG_ 798 CP_a177_incompatibleV2lDeviceDet "Charge port controller: a177 incompatible v2l device detected";
CM_ SG_ 798 CP_a179_evseCommsTlsError "Charge port controller: a179 evse comms tls error";
CM_ SG_ 798 CP_a182_pncdCommsError "Charge port controller: a182 pncd comms error";
CM_ SG_ 798 CP_a183_certManagerError "Charge port controller: a183 cert manager error";
CM_ SG_ 798 CP_a184_certChangeEvent "Charge port controller: a184 cert change event";
CM_ SG_ 798 CP_a185_pncAuthRejection "Charge port controller: a185 pnc auth rejection";
CM_ SG_ 798 CP_a186_spiDmaFailure "Charge port controller: a186 spi dma failure";
CM_ SG_ 798 CP_a187_highStackUsage "Charge port controller: a187 high stack usage";
CM_ BO_ 1085 "Charge port controller message: charge status log";
CM_ SG_ 1085 CP_hvChargeStatus_log "Charge port controller: hv charge status log";
CM_ SG_ 1085 CP_chargeShutdownRequest_log "Charge port controller: charge shutdown request log";
CM_ SG_ 1085 CP_acChargeCurrentLimit_log "Charge port controller: ac charge current limit log";
CM_ SG_ 1085 CP_internalMaxDcCurrentLimit_log "Charge port controller: internal max dc current limit log";
CM_ SG_ 1085 CP_vehicleIsoCheckRequired_log "Charge port controller: vehicle iso check required log";
CM_ SG_ 1085 CP_vehiclePrechargeRequired_log "Charge port controller: vehicle precharge required log";
CM_ SG_ 1085 CP_internalMaxAcCurrentLimit_log "Charge port controller: internal max ac current limit log";
CM_ SG_ 1085 CP_evseChargeType_log "Charge port controller: evse charge type log";
CM_ SG_ 1085 CP_chgLimitMode_log "Charge port controller: chg limit mode log";
CM_ BO_ 669 "Charge port controller message: dc charge status";
CM_ SG_ 669 CP_evseOutputDcCurrent "The DC EVSE's measured output current";
CM_ SG_ 669 CP_evseOutputDcVoltage "The DC EVSE's measured output voltage";
CM_ SG_ 669 CP_evseOutputDcCurrentStale "Indicates whether the data in CP_evseOutputDcCurrent has not been updated with new info from the DC EVSE recently";
CM_ BO_ 541 "Charge port controller message: evse status";
CM_ SG_ 541 CP_evseAccept "State of pilot EVSE accept state";
CM_ SG_ 541 CP_evseRequest "Request to close AC EVSE relays, used when digital communications have been established";
CM_ SG_ 541 CP_proximity "Sensed state of proximity for all inlets; raw 0 = signal not available (SNA)";
CM_ SG_ 541 CP_pilot "State of EVSE pilot signal sensed by the charge port; raw 7 = signal not available (SNA)";
CM_ SG_ 541 CP_digitalCommsEstablished "Indicates whether digital communications have been established with an EVSE";
CM_ SG_ 541 CP_pilotCurrent "Line current limit detected from pilot signal";
CM_ SG_ 541 CP_cableType "Type of charge cable detected; raw 4 = signal not available (SNA)";
CM_ SG_ 541 CP_iecPilotState "State of the control pilot as defined in IEC-61851-1; raw 9 = signal not available (SNA)";
CM_ SG_ 541 CP_plcSupported "Indicates whether PLC hardware is populated for CCS charging support";
CM_ SG_ 541 CP_cableCurrentLimit "Charge port controller: cable current limit";
CM_ SG_ 541 CP_teslaSwcanState "Charge port controller: tesla swcan state";
CM_ SG_ 541 CP_evseChargeType_UI "Reports the type of Electric Vehicle Supply Equipment (EVSE) connected.";
CM_ SG_ 541 CP_gbState "State of GB DC charging";
CM_ SG_ 541 CP_gbdcStopChargeReason "Reason for stopping GB DC charging";
CM_ SG_ 541 CP_gbdcFailureReason "Reason for failure of GB DC charging";
CM_ SG_ 541 CP_gbdcChargeAttempts "Number of GB DC charging retries used";
CM_ SG_ 541 CP_acChargeState "Charge port controller: ac charge state";
CM_ SG_ 541 CP_teslaDcState "Reports the state of the Tesla direct current (DC) state machine.";
CM_ BO_ 1885 "Charge port controller message: logging fast";
CM_ SG_ 1885 CP_loggingFastSelect "Charge port controller: logging fast select";
CM_ SG_ 1885 CP_inductiveSensor_raw "Charge port controller: inductive sensor raw";
CM_ SG_ 1885 CP_doorOpenActuationTime "Charge port controller: door open actuation time";
CM_ SG_ 1885 CP_doorCloseActuationTime "Charge port controller: door close actuation time";
CM_ SG_ 1885 CP_chargeCableSecured "Indicates whether a charge cable is secured in any inlet";
CM_ SG_ 1885 CP_chargeCablePresent "Indicates whether a charge cable is present in any inlet";
CM_ SG_ 1885 CP_latchCheckAvailable "Charge port controller: latch check available";
CM_ SG_ 1885 CP_UHF_controlState "Control state of UHF receiver";
CM_ SG_ 1885 CP_proximityV "Charge port controller: proximity v";
CM_ SG_ 1885 CP_proximityV_GBCC1 "Sensed voltage of GB DC inlet CC1 connection";
CM_ SG_ 1885 CP_proximityV_GBCC2 "Sensed voltage of GB DC inlet CC2 connection";
CM_ SG_ 1885 CP_doorPot "Position of the charge port door potentiometer";
CM_ SG_ 1885 CP_doorPresenceHallSensorV "Charge port controller: door presence hall sensor v";
CM_ SG_ 1885 CP_doorOpenRequest "Door open request trigger";
CM_ SG_ 1885 CP_doorOpenEndOfDriveReason "Reason why the door stopped moving in the open direction";
CM_ SG_ 1885 CP_coverClosed "Charge port controller: cover closed";
CM_ SG_ 1885 CP_doorCloseEndOfDriveReason "Reason why the door stopped moving in the closing direction";
CM_ SG_ 1885 CP_doorCloseRequest "Door close request trigger";
CM_ SG_ 1885 CP_latchDisengagingTime "Charge port controller: latch disengaging time";
CM_ SG_ 1885 CP_latchEngagingTime "Charge port controller: latch engaging time";
CM_ SG_ 1885 CP_latchDisengagingStopReason "Reason why the latch stopped moving in the engaged direction";
CM_ SG_ 1885 CP_latchEngagingStopReason "Reason why the latch stopped moving in the engaged direction";
CM_ SG_ 1885 CP_doorIdDetectionState "Charge port controller: door id detection state; raw 0 = signal not available (SNA)";
CM_ SG_ 1885 CP_doorIdDetectedBin "Charge port controller: door id detected bin";
CM_ BO_ 2042 "Charge port controller message: logging slow";
CM_ SG_ 2042 CP_loggingSlowSelect "Charge port controller: logging slow select";
CM_ SG_ 2042 CP_UHF_chipState "Charge port controller: UHF chip state";
CM_ SG_ 2042 CP_UHF_rssi "Signal strength of received UHF signal";
CM_ SG_ 2042 CP_UHF_rxOverflow "Charge port controller: UHF rx overflow";
CM_ SG_ 2042 CP_UHF_rxNumBytes "Charge port controller: UHF rx num bytes";
CM_ SG_ 2042 CP_UHF_selfTestRssi "Signal strength of received self-test UHF signal";
CM_ SG_ 2042 CP_latchI "Charge port controller: latch i";
CM_ SG_ 2042 CP_inlet1HarnessIdState "State of the CP's inlet 1 harness pedigree; raw 0 = signal not available (SNA)";
CM_ SG_ 2042 CP_inlet1HarnessIdValue "Pedigree of the CP's inlet 1 harness";
CM_ SG_ 2042 CP_inlet2HarnessIdState "State of the CP's inlet 2 harness pedigree; raw 0 = signal not available (SNA)";
CM_ SG_ 2042 CP_inlet2HarnessIdValue "Pedigree of the CP's inlet 2 harness";
CM_ SG_ 2042 CP_inletHeaterState "Reports the present state of the inlet heater.";
CM_ SG_ 2042 CP_inletHeaterDuty "Inlet heater PWM duty cycle";
CM_ SG_ 2042 CP_nvm_dataValid "Charge port controller: nvm data valid";
CM_ SG_ 2042 CP_nvm_doorOpenCycles "Charge port controller: nvm door open cycles";
CM_ SG_ 2042 CP_nvm_doorCloseCycles "Charge port controller: nvm door close cycles";
CM_ SG_ 2042 CP_nvm_doorOpen "Charge port controller: nvm door open";
CM_ SG_ 2042 CP_nvm_doorPresent "Charge port controller: nvm door present";
CM_ SG_ 2042 CP_nvm_doorPresentValid "Charge port controller: nvm door present valid";
CM_ SG_ 2042 CP_nvm_badPilotDiodeDetected "Charge port controller: nvm bad pilot diode detected";
CM_ SG_ 2042 CP_nvm_pilotDiodeFaultCount "Charge port controller: nvm pilot diode fault count";
CM_ SG_ 2042 CP_doorOpenLimiterMaxCount "Charge port controller: door open limiter max count";
CM_ SG_ 2042 CP_doorOpenLimiterMaxRequestType "Charge port controller: door open limiter max request type";
CM_ SG_ 2042 CP_doorCloseLimiterMaxCount "Charge port controller: door close limiter max count";
CM_ SG_ 2042 CP_doorCloseLimiterMaxRequestTyp "Charge port controller: door close limiter max request type";
BA_DEF_ BO_ "GenMsgCycleTime" INT 0 3600000;
BA_DEF_ BO_ "GenMsgSendType" ENUM "Cyclic","NotUsed","NotUsed","NotUsed","NotUsed","NotUsed","NotUsed","IfActive","NoMsgSendType","NotUsed";
BA_DEF_ BO_ "VFrameFormat" ENUM "StandardCAN","ExtendedCAN","reserved","J1939PG","reserved","reserved","reserved","reserved","reserved","reserved","reserved","reserved","reserved","reserved","StandardCAN_FD","ExtendedCAN_FD";
BA_DEF_ BO_ "CANFD_BRS" ENUM "0","1";
BA_DEF_ SG_ "GenSigSNA" STRING;
BA_DEF_ SG_ "SystemSignalLongSymbol" STRING;
BA_DEF_ SG_ "Confidence" ENUM "validated","plausible","layout-only","contradicted";
BA_DEF_DEF_ "GenMsgCycleTime" 0;
BA_DEF_DEF_ "GenMsgSendType" "NoMsgSendType";
BA_DEF_DEF_ "VFrameFormat" "StandardCAN";
BA_DEF_DEF_ "CANFD_BRS" "1";
BA_DEF_DEF_ "GenSigSNA" "";
BA_DEF_DEF_ "SystemSignalLongSymbol" "";
BA_DEF_DEF_ "Confidence" "layout-only";
BA_ "GenMsgCycleTime" BO_ 946 30000;
BA_ "GenMsgSendType" BO_ 946 0;
BA_ "GenMsgCycleTime" BO_ 914 1000;
BA_ "GenMsgSendType" BO_ 914 0;
BA_ "GenMsgCycleTime" BO_ 594 100;
BA_ "GenMsgSendType" BO_ 594 0;
BA_ "GenMsgCycleTime" BO_ 674 100;
BA_ "GenMsgSendType" BO_ 674 0;
BA_ "GenMsgCycleTime" BO_ 658 100;
BA_ "GenMsgSendType" BO_ 658 0;
BA_ "GenMsgCycleTime" BO_ 530 100;
BA_ "GenMsgSendType" BO_ 530 0;
BA_ "GenMsgCycleTime" BO_ 786 1000;
BA_ "GenMsgSendType" BO_ 786 0;
BA_ "GenMsgCycleTime" BO_ 2028 1000;
BA_ "GenMsgSendType" BO_ 2028 0;
BA_ "GenMsgCycleTime" BO_ 754 100;
BA_ "GenMsgSendType" BO_ 754 0;
BA_ "GenMsgCycleTime" BO_ 810 5000;
BA_ "GenMsgSendType" BO_ 810 0;
BA_ "GenMsgCycleTime" BO_ 797 100;
BA_ "GenMsgSendType" BO_ 797 0;
BA_ "GenMsgCycleTime" BO_ 551 100;
BA_ "GenMsgSendType" BO_ 551 0;
BA_ "GenMsgCycleTime" BO_ 798 1000;
BA_ "GenMsgSendType" BO_ 798 0;
BA_ "GenMsgCycleTime" BO_ 1085 100;
BA_ "GenMsgSendType" BO_ 1085 0;
BA_ "GenMsgCycleTime" BO_ 669 100;
BA_ "GenMsgSendType" BO_ 669 0;
BA_ "GenMsgCycleTime" BO_ 541 100;
BA_ "GenMsgSendType" BO_ 541 0;
BA_ "GenMsgCycleTime" BO_ 1885 200;
BA_ "GenMsgSendType" BO_ 1885 0;
BA_ "GenMsgCycleTime" BO_ 2042 1000;
BA_ "GenMsgSendType" BO_ 2042 0;
BA_ "Confidence" SG_ 946 BMS_log2MuxId 1;
BA_ "Confidence" SG_ 946 BMS_cacAvg 0;
BA_ "Confidence" SG_ 946 BMS_cacMin 0;
BA_ "Confidence" SG_ 946 BMS_cacMinBrickId 0;
BA_ "Confidence" SG_ 946 BMS_cacMax 0;
BA_ "Confidence" SG_ 946 BMS_cacMaxBrickId 0;
BA_ "Confidence" SG_ 946 BMS_acRippleConfigNvramValid 0;
BA_ "Confidence" SG_ 946 BMS_hvChain_useLeakyBucket 0;
BA_ "Confidence" SG_ 946 BMS_hvChain_iLimit 0;
BA_ "GenSigSNA" SG_ 946 BMS_hvChain_iLimit "16383";
BA_ "Confidence" SG_ 946 BMS_hvChain_limitingState 0;
BA_ "GenSigSNA" SG_ 946 BMS_hvChain_limitingState "511";
BA_ "Confidence" SG_ 946 BMS_hvChain_limitingStateTempera 0;
BA_ "GenSigSNA" SG_ 946 BMS_hvChain_limitingStateTempera "4096";
BA_ "SystemSignalLongSymbol" SG_ 946 BMS_hvChain_limitingStateTempera "BMS_hvChain_limitingStateTemperature";
BA_ "Confidence" SG_ 946 BMS_acRippleIsSupported 0;
BA_ "Confidence" SG_ 946 BMS_acRippleStartTemperatureMax 0;
BA_ "Confidence" SG_ 946 BMS_acRippleStartTemperatureMin 0;
BA_ "Confidence" SG_ 946 BMS_fcLinkTestDecayTime 0;
BA_ "GenSigSNA" SG_ 946 BMS_fcLinkTestDecayTime "1023";
BA_ "Confidence" SG_ 946 BMS_fcLinkTestTimeSinceLastRun 0;
BA_ "Confidence" SG_ 946 BMS_pcsPrechargeTargetVoltage 0;
BA_ "Confidence" SG_ 946 BMS_recentOvUvAlert 0;
BA_ "Confidence" SG_ 946 BMS_recentIsoAlert 0;
BA_ "Confidence" SG_ 946 BMS_recentBmbMiaAlert 0;
BA_ "Confidence" SG_ 946 BMS_cacBlendingConfigNvramValid 0;
BA_ "Confidence" SG_ 946 BMS_cacBlendingEnabled 0;
BA_ "Confidence" SG_ 946 BMS_cacBlendPercentPerCycle 0;
BA_ "Confidence" SG_ 946 BMS_energyVariableChgRequested 0;
BA_ "Confidence" SG_ 946 BMS_packRestTime 0;
BA_ "Confidence" SG_ 946 BMS_idealEnergyFloor 0;
BA_ "GenSigSNA" SG_ 946 BMS_idealEnergyFloor "1023";
BA_ "Confidence" SG_ 946 BMS_thmGradientSlopeCondition 0;
BA_ "Confidence" SG_ 946 BMS_recentSlopeConditon 0;
BA_ "Confidence" SG_ 946 BMS_dynamicEnergyBuffer 0;
BA_ "GenSigSNA" SG_ 946 BMS_dynamicEnergyBuffer "1023";
BA_ "Confidence" SG_ 946 BMS_temperatureCondition 0;
BA_ "Confidence" SG_ 946 BMS_thmGradientSlope 0;
BA_ "Confidence" SG_ 946 BMS_thmGradient 0;
BA_ "Confidence" SG_ 946 BMS_dSocNormalizedMin 0;
BA_ "GenSigSNA" SG_ 946 BMS_dSocNormalizedMin "4095";
BA_ "Confidence" SG_ 946 BMS_dSocNormalizedFiltMin 0;
BA_ "GenSigSNA" SG_ 946 BMS_dSocNormalizedFiltMin "4095";
BA_ "Confidence" SG_ 946 BMS_dSocMinAlpha 0;
BA_ "GenSigSNA" SG_ 946 BMS_dSocMinAlpha "4095";
BA_ "Confidence" SG_ 946 BMS_dSocMaxLowAlphaCounter 0;
BA_ "Confidence" SG_ 946 BMS_dSocMinAlphaBrickID 0;
BA_ "Confidence" SG_ 946 BMS_dSocCacMargin 0;
BA_ "GenSigSNA" SG_ 946 BMS_dSocCacMargin "511";
BA_ "Confidence" SG_ 946 BMS_lifeModelAvgTempSeverity 0;
BA_ "GenSigSNA" SG_ 946 BMS_lifeModelAvgTempSeverity "31";
BA_ "Confidence" SG_ 946 BMS_lifeModelDepthOfDischargeSev 0;
BA_ "GenSigSNA" SG_ 946 BMS_lifeModelDepthOfDischargeSev "255";
BA_ "SystemSignalLongSymbol" SG_ 946 BMS_lifeModelDepthOfDischargeSev "BMS_lifeModelDepthOfDischargeSeverity";
BA_ "Confidence" SG_ 946 BMS_lifeModelHistogramCapacityLo 0;
BA_ "GenSigSNA" SG_ 946 BMS_lifeModelHistogramCapacityLo "511";
BA_ "SystemSignalLongSymbol" SG_ 946 BMS_lifeModelHistogramCapacityLo "BMS_lifeModelHistogramCapacityLoss";
BA_ "Confidence" SG_ 946 BMS_lifeModelHistogramBrickCapac 0;
BA_ "GenSigSNA" SG_ 946 BMS_lifeModelHistogramBrickCapac "8191";
BA_ "SystemSignalLongSymbol" SG_ 946 BMS_lifeModelHistogramBrickCapac "BMS_lifeModelHistogramBrickCapacity";
BA_ "Confidence" SG_ 946 BMS_lifeModelDcrGrowthPercent 0;
BA_ "GenSigSNA" SG_ 946 BMS_lifeModelDcrGrowthPercent "8192";
BA_ "Confidence" SG_ 946 BMS_nominalFullPackEnergyRaw 0;
BA_ "GenSigSNA" SG_ 946 BMS_nominalFullPackEnergyRaw "65535";
BA_ "Confidence" SG_ 946 BMS_userChargeCalibratingReason 1;
BA_ "Confidence" SG_ 946 BMS_nominalEnergyRemainingBuffer 1;
BA_ "GenSigSNA" SG_ 946 BMS_nominalEnergyRemainingBuffer "65535";
BA_ "SystemSignalLongSymbol" SG_ 946 BMS_nominalEnergyRemainingBuffer "BMS_nominalEnergyRemainingBuffered";
BA_ "Confidence" SG_ 946 BMS_idealEnergyRemainingBuffered 1;
BA_ "GenSigSNA" SG_ 946 BMS_idealEnergyRemainingBuffered "65535";
BA_ "Confidence" SG_ 946 BMS_largestCacSpreadErrorLower 0;
BA_ "GenSigSNA" SG_ 946 BMS_largestCacSpreadErrorLower "4095";
BA_ "Confidence" SG_ 946 BMS_lifeModelAverageCac 0;
BA_ "GenSigSNA" SG_ 946 BMS_lifeModelAverageCac "4095";
BA_ "Confidence" SG_ 946 BMS_lifeModelCacBrick1 0;
BA_ "GenSigSNA" SG_ 946 BMS_lifeModelCacBrick1 "4095";
BA_ "Confidence" SG_ 946 BMS_lifeModelAverageOffset 0;
BA_ "GenSigSNA" SG_ 946 BMS_lifeModelAverageOffset "512";
BA_ "Confidence" SG_ 946 BMS_percentCacUpdatesInTimeWindo 0;
BA_ "SystemSignalLongSymbol" SG_ 946 BMS_percentCacUpdatesInTimeWindo "BMS_percentCacUpdatesInTimeWindow";
BA_ "Confidence" SG_ 946 BMS_lifeModelMaxCacBrickId 0;
BA_ "GenSigSNA" SG_ 946 BMS_lifeModelMaxCacBrickId "255";
BA_ "Confidence" SG_ 946 BMS_lifeModelMaxCac 0;
BA_ "GenSigSNA" SG_ 946 BMS_lifeModelMaxCac "4095";
BA_ "Confidence" SG_ 946 BMS_lifeModelMinCacBrickId 0;
BA_ "GenSigSNA" SG_ 946 BMS_lifeModelMinCacBrickId "255";
BA_ "Confidence" SG_ 946 BMS_lifeModelMinCac 0;
BA_ "GenSigSNA" SG_ 946 BMS_lifeModelMinCac "4095";
BA_ "Confidence" SG_ 946 BMS_restingPointCacAvg 0;
BA_ "GenSigSNA" SG_ 946 BMS_restingPointCacAvg "4095";
BA_ "Confidence" SG_ 946 BMS_cacEstimationSource 0;
BA_ "Confidence" SG_ 946 BMS_synchronizedCacMaxRaw 0;
BA_ "GenSigSNA" SG_ 946 BMS_synchronizedCacMaxRaw "4095";
BA_ "Confidence" SG_ 946 BMS_synchronizedCacMinRaw 0;
BA_ "GenSigSNA" SG_ 946 BMS_synchronizedCacMinRaw "4095";
BA_ "Confidence" SG_ 946 BMS_largestSyncCacErrorStartSoc 0;
BA_ "Confidence" SG_ 946 BMS_largestSyncCacErrorEndSoc 0;
BA_ "Confidence" SG_ 946 BMS_runtimeSocConfigNvramValid 0;
BA_ "Confidence" SG_ 946 BMS_runtimeSocCorrectionsEnabled 0;
BA_ "Confidence" SG_ 946 BMS_rubberBandingEnabled 0;
BA_ "Confidence" SG_ 946 BMS_rubberBandingConfigNvramVali 0;
BA_ "SystemSignalLongSymbol" SG_ 946 BMS_rubberBandingConfigNvramVali "BMS_rubberBandingConfigNvramValid";
BA_ "Confidence" SG_ 946 BMS_runtimeSocMinTempForModel 0;
BA_ "Confidence" SG_ 946 BMS_energyBufferConfigNvramValid 0;
BA_ "Confidence" SG_ 946 BMS_thermalEvent1pDetectConfigDi 0;
BA_ "SystemSignalLongSymbol" SG_ 946 BMS_thermalEvent1pDetectConfigDi "BMS_thermalEvent1pDetectConfigDisabled";
BA_ "Confidence" SG_ 946 BMS_sohEnergy 0;
BA_ "GenSigSNA" SG_ 946 BMS_sohEnergy "2047";
BA_ "Confidence" SG_ 946 BMS_fullCapacitySohEnergy 0;
BA_ "GenSigSNA" SG_ 946 BMS_fullCapacitySohEnergy "2047";
BA_ "Confidence" SG_ 946 BMS_calibratedCapacitySohEnergy 0;
BA_ "GenSigSNA" SG_ 946 BMS_calibratedCapacitySohEnergy "2047";
BA_ "Confidence" SG_ 946 BMS_estimatedCapacitySohEnergy 0;
BA_ "GenSigSNA" SG_ 946 BMS_estimatedCapacitySohEnergy "2047";
BA_ "Confidence" SG_ 946 BMS_prevUserFacingSohEnergy 0;
BA_ "GenSigSNA" SG_ 946 BMS_prevUserFacingSohEnergy "2047";
BA_ "Confidence" SG_ 946 BMS_stateOfHealthMinCac 0;
BA_ "GenSigSNA" SG_ 946 BMS_stateOfHealthMinCac "8191";
BA_ "Confidence" SG_ 946 BMS_lifeModelStorageLossPackAge 0;
BA_ "GenSigSNA" SG_ 946 BMS_lifeModelStorageLossPackAge "16383";
BA_ "Confidence" SG_ 946 BMS_lifeModelThroughputCycleCoun 1;
BA_ "GenSigSNA" SG_ 946 BMS_lifeModelThroughputCycleCoun "4095";
BA_ "SystemSignalLongSymbol" SG_ 946 BMS_lifeModelThroughputCycleCoun "BMS_lifeModelThroughputCycleCount";
BA_ "Confidence" SG_ 946 BMS_lifeModelThroughputDcrCycleC 1;
BA_ "GenSigSNA" SG_ 946 BMS_lifeModelThroughputDcrCycleC "4095";
BA_ "SystemSignalLongSymbol" SG_ 946 BMS_lifeModelThroughputDcrCycleC "BMS_lifeModelThroughputDcrCycleCount";
BA_ "Confidence" SG_ 946 BMS_energyWalkCounter 0;
BA_ "Confidence" SG_ 946 BMS_energyWalkTimeoutCounter 0;
BA_ "Confidence" SG_ 946 BMS_dynamicCcvEnabled 0;
BA_ "Confidence" SG_ 946 BMS_chargeTargetLookupSoc 1;
BA_ "Confidence" SG_ 946 BMS_stateOfHealth 1;
BA_ "GenSigSNA" SG_ 946 BMS_stateOfHealth "1023";
BA_ "Confidence" SG_ 914 BMS_packConfigMultiplexer 1;
BA_ "Confidence" SG_ 914 BMS_reservedConfig_0 1;
BA_ "Confidence" SG_ 914 BMS_moduleType 0;
BA_ "Confidence" SG_ 914 BMS_thermalPackType 0;
BA_ "Confidence" SG_ 914 BMS_packMass 0;
BA_ "Confidence" SG_ 914 BMS_platformMaxBusVoltage 0;
BA_ "Confidence" SG_ 914 BMS_standbySupplyContinuousPower 0;
BA_ "SystemSignalLongSymbol" SG_ 914 BMS_standbySupplyContinuousPower "BMS_standbySupplyContinuousPowerLimit";
BA_ "Confidence" SG_ 594 BMS_maxRegenPower 0;
BA_ "Confidence" SG_ 594 BMS_maxDischargePower 0;
BA_ "Confidence" SG_ 594 BMS_maxStationaryHeatPower 0;
BA_ "Confidence" SG_ 594 BMS_powerLimitsState 0;
BA_ "Confidence" SG_ 594 BMS_notEnoughPowerForHeatPump 1;
BA_ "Confidence" SG_ 594 BMS_instantChargePowerCapability 0;
BA_ "GenSigSNA" SG_ 594 BMS_instantChargePowerCapability "65535";
BA_ "Confidence" SG_ 674 BMS_acRippleCurrentAmplitudeLimi 1;
BA_ "SystemSignalLongSymbol" SG_ 674 BMS_acRippleCurrentAmplitudeLimi "BMS_acRippleCurrentAmplitudeLimit";
BA_ "Confidence" SG_ 674 BMS_acRippleMaxVoltageLimit 1;
BA_ "Confidence" SG_ 674 BMS_acRippleMinVoltageLimit 1;
BA_ "Confidence" SG_ 674 BMS_acRippleFrequencyRequest 1;
BA_ "GenSigSNA" SG_ 674 BMS_acRippleFrequencyRequest "63";
BA_ "Confidence" SG_ 674 BMS_acRippleCurrentAmplitudeRequ 1;
BA_ "SystemSignalLongSymbol" SG_ 674 BMS_acRippleCurrentAmplitudeRequ "BMS_acRippleCurrentAmplitudeRequest";
BA_ "Confidence" SG_ 674 BMS_acRippleRequest 1;
BA_ "Confidence" SG_ 658 BMS_socMin 0;
BA_ "Confidence" SG_ 658 BMS_socUI 0;
BA_ "Confidence" SG_ 658 BMS_socMax 0;
BA_ "Confidence" SG_ 658 BMS_socAvg 0;
BA_ "Confidence" SG_ 658 BMS_beginningOfLifePackEnergy 0;
BA_ "GenSigSNA" SG_ 658 BMS_beginningOfLifePackEnergy "1023";
BA_ "Confidence" SG_ 658 BMS_battTempPct 1;
BA_ "GenSigSNA" SG_ 658 BMS_battTempPct "255";
BA_ "Confidence" SG_ 658 BMS_userChargeCurrentLimitMode 1;
BA_ "Confidence" SG_ 530 BMS_hvacPowerRequest 0;
BA_ "Confidence" SG_ 530 BMS_notEnoughPowerForDrive 0;
BA_ "Confidence" SG_ 530 BMS_notEnoughPowerForSupport 0;
BA_ "Confidence" SG_ 530 BMS_preconditionAllowed 0;
BA_ "Confidence" SG_ 530 BMS_updateAllowed 0;
BA_ "Confidence" SG_ 530 BMS_activeHeatingWorthwhile 1;
BA_ "Confidence" SG_ 530 BMS_cpMiaOnHvs 1;
BA_ "Confidence" SG_ 530 BMS_pcsPwmEnabled 1;
BA_ "Confidence" SG_ 530 BMS_contactorState 0;
BA_ "GenSigSNA" SG_ 530 BMS_contactorState "0";
BA_ "Confidence" SG_ 530 BMS_userChargeStatus 0;
BA_ "Confidence" SG_ 530 BMS_totalBatteryPower 1;
BA_ "GenSigSNA" SG_ 530 BMS_totalBatteryPower "65536";
BA_ "Confidence" SG_ 530 BMS_chargeRequest 1;
BA_ "Confidence" SG_ 530 BMS_state 0;
BA_ "GenSigSNA" SG_ 530 BMS_state "9";
BA_ "Confidence" SG_ 530 BMS_diLimpRequest 1;
BA_ "Confidence" SG_ 530 BMS_chgPowerAvailable 1;
BA_ "GenSigSNA" SG_ 530 BMS_chgPowerAvailable "4095";
BA_ "Confidence" SG_ 530 BMS_chargeRetryCount 1;
BA_ "Confidence" SG_ 530 BMS_conditioningRequest 0;
BA_ "Confidence" SG_ 530 BMS_smStateRequest 0;
BA_ "GenSigSNA" SG_ 530 BMS_smStateRequest "9";
BA_ "Confidence" SG_ 530 BMS_hvState 0;
BA_ "Confidence" SG_ 786 BMS_powerDissipation 1;
BA_ "Confidence" SG_ 786 BMS_flowRequest 1;
BA_ "Confidence" SG_ 786 BMS_inletActiveCoolTargetT 1;
BA_ "Confidence" SG_ 786 BMS_inletPassiveTargetT 1;
BA_ "Confidence" SG_ 786 BMS_inletActiveHeatTargetT 1;
BA_ "Confidence" SG_ 786 BMS_minPackTemperature 1;
BA_ "Confidence" SG_ 786 BMS_maxPackTemperature 1;
BA_ "Confidence" SG_ 2028 BMS_coldStagnationLimit 1;
BA_ "Confidence" SG_ 2028 BMS_hotStagnationLimit 1;
BA_ "Confidence" SG_ 2028 BMS_hotCellTempLimit 1;
BA_ "Confidence" SG_ 2028 BMS_activeCoolCellReferenceT 1;
BA_ "Confidence" SG_ 2028 BMS_activeHeatCellTargetT 1;
BA_ "Confidence" SG_ 2028 BMS_cellTempTargetMode 1;
BA_ "Confidence" SG_ 2028 BMS_requestDischarge 1;
BA_ "Confidence" SG_ 754 BMS_nmGoingToSleep 0;
BA_ "Confidence" SG_ 754 BMS_nmWakeUpBus 0;
BA_ "Confidence" SG_ 754 BMS_hvsBusAsleep 0;
BA_ "Confidence" SG_ 754 BMS_nmKeepAwakeReason 1;
BA_ "GenSigSNA" SG_ 754 BMS_nmKeepAwakeReason "0";
BA_ "Confidence" SG_ 754 BMS_nmWakeUpReason 0;
BA_ "Confidence" SG_ 810 BMS_thermalEventSuspected 0;
BA_ "Confidence" SG_ 810 BMS_vehicleNotificationsCounter 0;
BA_ "Confidence" SG_ 810 BMS_isolationResistance 0;
BA_ "GenSigSNA" SG_ 810 BMS_isolationResistance "1023";
BA_ "Confidence" SG_ 810 BMS_vehicleNotificationsChecksum 0;
BA_ "Confidence" SG_ 797 CC_chgStatus2Index 1;
BA_ "Confidence" SG_ 797 CC_buttonState 0;
BA_ "Confidence" SG_ 551 CMP_inputHVVoltage 0;
BA_ "Confidence" SG_ 551 CMP_inputLVVoltage 0;
BA_ "Confidence" SG_ 551 CMP_inputHVCurrent 0;
BA_ "Confidence" SG_ 551 CMP_inputHVPower 0;
BA_ "Confidence" SG_ 1294 CP_alertID 1;
BA_ "Confidence" SG_ 1294 CP_alertType 1;
BA_ "Confidence" SG_ 1294 CP_a004_proximityV 1;
BA_ "Confidence" SG_ 1294 CP_a004_cc1Voltage 1;
BA_ "Confidence" SG_ 1294 CP_a004_cc2Voltage 1;
BA_ "Confidence" SG_ 1294 CP_a005_cc1Voltage 1;
BA_ "Confidence" SG_ 1294 CP_a005_cc2Voltage 1;
BA_ "Confidence" SG_ 1294 CP_a005_gbdcState 1;
BA_ "Confidence" SG_ 1294 CP_a005_packCurrent 1;
BA_ "Confidence" SG_ 1294 CP_a005_evseCurrent 1;
BA_ "Confidence" SG_ 1294 CP_a008_stackUsed 1;
BA_ "Confidence" SG_ 1294 CP_a009_cover1OpenCounts 1;
BA_ "Confidence" SG_ 1294 CP_a009_cover2OpenCounts 1;
BA_ "Confidence" SG_ 1294 CP_a009_cover1State 1;
BA_ "GenSigSNA" SG_ 1294 CP_a009_cover1State "5";
BA_ "Confidence" SG_ 1294 CP_a009_cover2State 1;
BA_ "GenSigSNA" SG_ 1294 CP_a009_cover2State "5";
BA_ "Confidence" SG_ 1294 CP_a010_pilotHigh 1;
BA_ "Confidence" SG_ 1294 CP_a010_pilotLow 1;
BA_ "Confidence" SG_ 1294 CP_a011_eepromErrorType 1;
BA_ "Confidence" SG_ 1294 CP_a015_apsVoltageOV 1;
BA_ "Confidence" SG_ 1294 CP_a016_apsVoltageUV 1;
BA_ "Confidence" SG_ 1294 CP_a017_5V_VoltageOV 1;
BA_ "Confidence" SG_ 1294 CP_a018_5V_VoltageUV 1;
BA_ "Confidence" SG_ 1294 CP_a023_stopChargeReason 1;
BA_ "Confidence" SG_ 1294 CP_a023_failureReason 1;
BA_ "Confidence" SG_ 1294 CP_a029_CP_pilot 1;
BA_ "GenSigSNA" SG_ 1294 CP_a029_CP_pilot "7";
BA_ "Confidence" SG_ 1294 CP_a029_CP_proximity 1;
BA_ "GenSigSNA" SG_ 1294 CP_a029_CP_proximity "0";
BA_ "Confidence" SG_ 1294 CP_a031_apsVoltage 1;
BA_ "Confidence" SG_ 1294 CP_a031_doorCountsFiltered 1;
BA_ "Confidence" SG_ 1294 CP_a031_inductiveSensorFiltered 1;
BA_ "Confidence" SG_ 1294 CP_a031_hallSensorFiltered 1;
BA_ "Confidence" SG_ 1294 CP_a032_apsVoltage 1;
BA_ "Confidence" SG_ 1294 CP_a032_doorCountsFiltered 1;
BA_ "Confidence" SG_ 1294 CP_a032_inductiveSensorFiltered 1;
BA_ "Confidence" SG_ 1294 CP_a032_hallSensorFiltered 1;
BA_ "Confidence" SG_ 1294 CP_a035_latchState 1;
BA_ "GenSigSNA" SG_ 1294 CP_a035_latchState "0";
BA_ "Confidence" SG_ 1294 CP_a035_latchOffset 1;
BA_ "Confidence" SG_ 1294 CP_a035_inletID 1;
BA_ "Confidence" SG_ 1294 CP_a036_latchCountsFiltered 1;
BA_ "Confidence" SG_ 1294 CP_a036_latchState 1;
BA_ "GenSigSNA" SG_ 1294 CP_a036_latchState "0";
BA_ "Confidence" SG_ 1294 CP_a036_CP_apsVoltage 1;
BA_ "Confidence" SG_ 1294 CP_a036_inletID 1;
BA_ "Confidence" SG_ 1294 CP_a037_latchCountsFiltered 1;
BA_ "Confidence" SG_ 1294 CP_a037_latchState 1;
BA_ "GenSigSNA" SG_ 1294 CP_a037_latchState "0";
BA_ "Confidence" SG_ 1294 CP_a037_CP_apsVoltage 1;
BA_ "Confidence" SG_ 1294 CP_a037_inletID 1;
BA_ "Confidence" SG_ 1294 CP_a038_latchCountsFiltered 1;
BA_ "Confidence" SG_ 1294 CP_a038_latchState 1;
BA_ "GenSigSNA" SG_ 1294 CP_a038_latchState "0";
BA_ "Confidence" SG_ 1294 CP_a038_CP_apsVoltage 1;
BA_ "Confidence" SG_ 1294 CP_a038_inletID 1;
BA_ "Confidence" SG_ 1294 CP_a041_doorCounts 1;
BA_ "Confidence" SG_ 1294 CP_a041_inductiveSensorFiltered 1;
BA_ "Confidence" SG_ 1294 CP_a041_hallSensorFiltered 1;
BA_ "Confidence" SG_ 1294 CP_a042_doorCounts 1;
BA_ "Confidence" SG_ 1294 CP_a042_inductiveSensorFiltered 1;
BA_ "Confidence" SG_ 1294 CP_a042_hallSensorFiltered 1;
BA_ "Confidence" SG_ 1294 CP_a043_doorPotFiltered 1;
BA_ "Confidence" SG_ 1294 CP_a043_doorVelocity 1;
BA_ "Confidence" SG_ 1294 CP_a043_idleDoorPot 1;
BA_ "Confidence" SG_ 1294 CP_a049_proximity 1;
BA_ "GenSigSNA" SG_ 1294 CP_a049_proximity "0";
BA_ "Confidence" SG_ 1294 CP_a051_doorCountsFiltered 1;
BA_ "Confidence" SG_ 1294 CP_a054_latchCountsFiltered 1;
BA_ "Confidence" SG_ 1294 CP_a054_latchState 1;
BA_ "GenSigSNA" SG_ 1294 CP_a054_latchState "0";
BA_ "Confidence" SG_ 1294 CP_a054_CP_apsVoltage 1;
BA_ "Confidence" SG_ 1294 CP_a054_CP_proximity 1;
BA_ "GenSigSNA" SG_ 1294 CP_a054_CP_proximity "0";
BA_ "Confidence" SG_ 1294 CP_a054_inletID 1;
BA_ "Confidence" SG_ 1294 CP_a056_latchState 1;
BA_ "GenSigSNA" SG_ 1294 CP_a056_latchState "0";
BA_ "Confidence" SG_ 1294 CP_a056_CP_proximity 1;
BA_ "GenSigSNA" SG_ 1294 CP_a056_CP_proximity "0";
BA_ "Confidence" SG_ 1294 CP_a056_packCurrent 1;
BA_ "Confidence" SG_ 1294 CP_a058_CP_pilot 1;
BA_ "GenSigSNA" SG_ 1294 CP_a058_CP_pilot "7";
BA_ "Confidence" SG_ 1294 CP_a058_CC_pilot 1;
BA_ "GenSigSNA" SG_ 1294 CP_a058_CC_pilot "3";
BA_ "Confidence" SG_ 1294 CP_a058_FC_status 1;
BA_ "GenSigSNA" SG_ 1294 CP_a058_FC_status "0";
BA_ "Confidence" SG_ 1294 CP_a058_latchState 1;
BA_ "GenSigSNA" SG_ 1294 CP_a058_latchState "0";
BA_ "Confidence" SG_ 1294 CP_a058_CP_proximity 1;
BA_ "GenSigSNA" SG_ 1294 CP_a058_CP_proximity "0";
BA_ "Confidence" SG_ 1294 CP_a061_controlState 1;
BA_ "Confidence" SG_ 1294 CP_a061_lastControlState 1;
BA_ "Confidence" SG_ 1294 CP_a062_FC_status 1;
BA_ "GenSigSNA" SG_ 1294 CP_a062_FC_status "0";
BA_ "Confidence" SG_ 1294 CP_a062_FC_type 1;
BA_ "GenSigSNA" SG_ 1294 CP_a062_FC_type "7";
BA_ "Confidence" SG_ 1294 CP_a063_FC_status 1;
BA_ "GenSigSNA" SG_ 1294 CP_a063_FC_status "0";
BA_ "Confidence" SG_ 1294 CP_a063_FC_type 1;
BA_ "GenSigSNA" SG_ 1294 CP_a063_FC_type "7";
BA_ "Confidence" SG_ 1294 CP_a066_pilotHigh 1;
BA_ "Confidence" SG_ 1294 CP_a066_pilotLow 1;
BA_ "Confidence" SG_ 1294 CP_a066_proximity 1;
BA_ "GenSigSNA" SG_ 1294 CP_a066_proximity "0";
BA_ "Confidence" SG_ 1294 CP_a067_cc1Voltage 1;
BA_ "Confidence" SG_ 1294 CP_a067_cc2Voltage 1;
BA_ "Confidence" SG_ 1294 CP_a068_doorCountsFiltered 1;
BA_ "Confidence" SG_ 1294 CP_a068_inductiveSensorFiltered 1;
BA_ "Confidence" SG_ 1294 CP_a068_hallSensorFiltered 1;
BA_ "Confidence" SG_ 1294 CP_a071_expectedMessage 1;
BA_ "Confidence" SG_ 1294 CP_a072_currentMessage 1;
BA_ "Confidence" SG_ 1294 CP_a073_ccsManagerState 1;
BA_ "Confidence" SG_ 1294 CP_a073_ccsDcState 1;
BA_ "Confidence" SG_ 1294 CP_a073_ccsShutdownReason 1;
BA_ "Confidence" SG_ 1294 CP_a074_slacState 1;
BA_ "Confidence" SG_ 1294 CP_a074_slacErrorCode 1;
BA_ "Confidence" SG_ 1294 CP_a075_evccState 1;
BA_ "Confidence" SG_ 1294 CP_a075_currentMessage 1;
BA_ "Confidence" SG_ 1294 CP_a075_initFailureType 1;
BA_ "Confidence" SG_ 1294 CP_a078_VC_tempAmbientFiltered 1;
BA_ "GenSigSNA" SG_ 1294 CP_a078_VC_tempAmbientFiltered "0";
BA_ "Confidence" SG_ 1294 CP_a078_pinTemperature1 1;
BA_ "GenSigSNA" SG_ 1294 CP_a078_pinTemperature1 "255";
BA_ "Confidence" SG_ 1294 CP_a078_pinTemperature2 1;
BA_ "GenSigSNA" SG_ 1294 CP_a078_pinTemperature2 "255";
BA_ "Confidence" SG_ 1294 CP_a078_pinTemperature3 1;
BA_ "GenSigSNA" SG_ 1294 CP_a078_pinTemperature3 "255";
BA_ "Confidence" SG_ 1294 CP_a079_VC_tempAmbientFiltered 1;
BA_ "GenSigSNA" SG_ 1294 CP_a079_VC_tempAmbientFiltered "0";
BA_ "Confidence" SG_ 1294 CP_a079_pinTemperature1 1;
BA_ "GenSigSNA" SG_ 1294 CP_a079_pinTemperature1 "255";
BA_ "Confidence" SG_ 1294 CP_a079_pinTemperature2 1;
BA_ "GenSigSNA" SG_ 1294 CP_a079_pinTemperature2 "255";
BA_ "Confidence" SG_ 1294 CP_a079_pinTemperature3 1;
BA_ "GenSigSNA" SG_ 1294 CP_a079_pinTemperature3 "255";
BA_ "Confidence" SG_ 1294 CP_a084_proximityV 1;
BA_ "Confidence" SG_ 1294 CP_a084_cc1Voltage 1;
BA_ "Confidence" SG_ 1294 CP_a084_cc2Voltage 1;
BA_ "Confidence" SG_ 1294 CP_a085_dcPinTemp 1;
BA_ "Confidence" SG_ 1294 CP_a086_dcPinTemp 1;
BA_ "Confidence" SG_ 1294 CP_a089_gtwPlcSupportType 1;
BA_ "Confidence" SG_ 1294 CP_a090_evseIsoStatus 1;
BA_ "Confidence" SG_ 1294 CP_a090_ccsDcState 1;
BA_ "Confidence" SG_ 1294 CP_a091_fcType 1;
BA_ "GenSigSNA" SG_ 1294 CP_a091_fcType "7";
BA_ "Confidence" SG_ 1294 CP_a095_packCurrent 1;
BA_ "Confidence" SG_ 1294 CP_a095_dcOutputCurrent 1;
BA_ "Confidence" SG_ 1294 CP_a095_ambientTemp 1;
BA_ "Confidence" SG_ 1294 CP_a095_fcType 1;
BA_ "GenSigSNA" SG_ 1294 CP_a095_fcType "7";
BA_ "Confidence" SG_ 1294 CP_a095_fcBrand 1;
BA_ "GenSigSNA" SG_ 1294 CP_a095_fcBrand "0";
BA_ "Confidence" SG_ 1294 CP_a099_proximity 1;
BA_ "GenSigSNA" SG_ 1294 CP_a099_proximity "0";
BA_ "Confidence" SG_ 1294 CP_a099_pilot 1;
BA_ "GenSigSNA" SG_ 1294 CP_a099_pilot "7";
BA_ "Confidence" SG_ 1294 CP_a103_proximityV 1;
BA_ "Confidence" SG_ 1294 CP_a109_thermistorTemp 1;
BA_ "Confidence" SG_ 1294 CP_a110_thermistorTemp 1;
BA_ "Confidence" SG_ 1294 CP_a110_thermalVelocity 1;
BA_ "GenSigSNA" SG_ 1294 CP_a110_thermalVelocity "511";
BA_ "Confidence" SG_ 1294 CP_a111_heaterTemperature 1;
BA_ "GenSigSNA" SG_ 1294 CP_a111_heaterTemperature "255";
BA_ "Confidence" SG_ 1294 CP_a111_VC_tempAmbientFiltered 1;
BA_ "GenSigSNA" SG_ 1294 CP_a111_VC_tempAmbientFiltered "0";
BA_ "Confidence" SG_ 1294 CP_a112_heaterTemperature 1;
BA_ "GenSigSNA" SG_ 1294 CP_a112_heaterTemperature "255";
BA_ "Confidence" SG_ 1294 CP_a113_heaterTemperature 1;
BA_ "GenSigSNA" SG_ 1294 CP_a113_heaterTemperature "255";
BA_ "Confidence" SG_ 1294 CP_a113_heaterCurrent 1;
BA_ "SystemSignalLongSymbol" SG_ 1294 CP_a116_temperatureSensorMismatc "CP_a116_temperatureSensorMismatch";
BA_ "Confidence" SG_ 1294 CP_a117_heaterTemperature 1;
BA_ "GenSigSNA" SG_ 1294 CP_a117_heaterTemperature "255";
BA_ "Confidence" SG_ 1294 CP_a117_averageError 1;
BA_ "GenSigSNA" SG_ 1294 CP_a117_averageError "255";
BA_ "Confidence" SG_ 1294 CP_a120_oldProximtyV 1;
BA_ "Confidence" SG_ 1294 CP_a120_newProximtyV 1;
BA_ "Confidence" SG_ 1294 CP_a120_chargeVoltage 1;
BA_ "Confidence" SG_ 1294 CP_a120_chargeCurrent 1;
BA_ "Confidence" SG_ 1294 CP_a120_dcPinTemp 1;
BA_ "GenSigSNA" SG_ 1294 CP_a120_dcPinTemp "255";
BA_ "Confidence" SG_ 1294 CP_a124_ivledState 1;
BA_ "Confidence" SG_ 1294 CP_a124_ivledVoltage 1;
BA_ "Confidence" SG_ 1294 CP_a129_bldcDriverState 1;
BA_ "Confidence" SG_ 1294 CP_a131_chargeProtocol 1;
BA_ "Confidence" SG_ 1294 CP_a135_sdpErr 1;
BA_ "Confidence" SG_ 1294 CP_a135_pilotState 1;
BA_ "GenSigSNA" SG_ 1294 CP_a135_pilotState "7";
BA_ "Confidence" SG_ 1294 CP_a138_FC_type 1;
BA_ "GenSigSNA" SG_ 1294 CP_a138_FC_type "7";
BA_ "Confidence" SG_ 1294 CP_a138_latchState 1;
BA_ "GenSigSNA" SG_ 1294 CP_a138_latchState "0";
BA_ "Confidence" SG_ 1294 CP_a138_CP_proximity 1;
BA_ "GenSigSNA" SG_ 1294 CP_a138_CP_proximity "0";
BA_ "Confidence" SG_ 1294 CP_a139_latchState 1;
BA_ "GenSigSNA" SG_ 1294 CP_a139_latchState "0";
BA_ "Confidence" SG_ 1294 CP_a139_CP_proximity 1;
BA_ "GenSigSNA" SG_ 1294 CP_a139_CP_proximity "0";
BA_ "Confidence" SG_ 1294 CP_a140_latchState 1;
BA_ "GenSigSNA" SG_ 1294 CP_a140_latchState "0";
BA_ "Confidence" SG_ 1294 CP_a140_CP_proximity 1;
BA_ "GenSigSNA" SG_ 1294 CP_a140_CP_proximity "0";
BA_ "Confidence" SG_ 1294 CP_a141_latchState 1;
BA_ "GenSigSNA" SG_ 1294 CP_a141_latchState "0";
BA_ "Confidence" SG_ 1294 CP_a141_CP_proximity 1;
BA_ "GenSigSNA" SG_ 1294 CP_a141_CP_proximity "0";
BA_ "Confidence" SG_ 1294 CP_a142_cc1Voltage 1;
BA_ "Confidence" SG_ 1294 CP_a142_cc2Voltage 1;
BA_ "Confidence" SG_ 1294 CP_a146_v2gMessage 1;
BA_ "Confidence" SG_ 1294 CP_a151_pilotHighMin 1;
BA_ "Confidence" SG_ 1294 CP_a151_pilotHighMax 1;
BA_ "Confidence" SG_ 1294 CP_a151_pilotLowMin 1;
BA_ "Confidence" SG_ 1294 CP_a151_pilotLowMax 1;
BA_ "Confidence" SG_ 1294 CP_a152_maxPilotSwcanHigh 1;
BA_ "Confidence" SG_ 1294 CP_a152_minPilotSwcanHigh 1;
BA_ "Confidence" SG_ 1294 CP_a152_maxPilotSwcanLow 1;
BA_ "Confidence" SG_ 1294 CP_a152_minPilotSwcanLow 1;
BA_ "Confidence" SG_ 1294 CP_a153_acPinTempVelocity 1;
BA_ "GenSigSNA" SG_ 1294 CP_a153_acPinTempVelocity "511";
BA_ "Confidence" SG_ 1294 CP_a153_acPinTemp1 1;
BA_ "GenSigSNA" SG_ 1294 CP_a153_acPinTemp1 "255";
BA_ "Confidence" SG_ 1294 CP_a153_acPinTemp2 1;
BA_ "GenSigSNA" SG_ 1294 CP_a153_acPinTemp2 "255";
BA_ "Confidence" SG_ 1294 CP_a153_ambientTemp 1;
BA_ "Confidence" SG_ 1294 CP_a153_pcsLineChargeCurrent 1;
BA_ "Confidence" SG_ 1294 CP_a154_acPinTempVelocity 1;
BA_ "GenSigSNA" SG_ 1294 CP_a154_acPinTempVelocity "511";
BA_ "Confidence" SG_ 1294 CP_a154_acPinTemp1 1;
BA_ "GenSigSNA" SG_ 1294 CP_a154_acPinTemp1 "255";
BA_ "Confidence" SG_ 1294 CP_a154_acPinTemp2 1;
BA_ "GenSigSNA" SG_ 1294 CP_a154_acPinTemp2 "255";
BA_ "Confidence" SG_ 1294 CP_a154_ambientTemp 1;
BA_ "Confidence" SG_ 1294 CP_a154_pcsLineChargeCurrent 1;
BA_ "Confidence" SG_ 1294 CP_a155_hallSensorVoltage 1;
BA_ "Confidence" SG_ 1294 CP_a161_pilotHighMin 1;
BA_ "Confidence" SG_ 1294 CP_a161_pilotHighMax 1;
BA_ "Confidence" SG_ 1294 CP_a161_pilotLowMin 1;
BA_ "Confidence" SG_ 1294 CP_a161_pilotLowMax 1;
BA_ "Confidence" SG_ 1294 CP_a162_maxPilotSwcanHigh 1;
BA_ "Confidence" SG_ 1294 CP_a162_minPilotSwcanHigh 1;
BA_ "Confidence" SG_ 1294 CP_a162_maxPilotSwcanLow 1;
BA_ "Confidence" SG_ 1294 CP_a162_minPilotSwcanLow 1;
BA_ "Confidence" SG_ 1294 CP_a163_cover1OpenCounts 1;
BA_ "Confidence" SG_ 1294 CP_a163_cover2OpenCounts 1;
BA_ "Confidence" SG_ 1294 CP_a163_cover1State 1;
BA_ "GenSigSNA" SG_ 1294 CP_a163_cover1State "5";
BA_ "Confidence" SG_ 1294 CP_a163_cover2State 1;
BA_ "GenSigSNA" SG_ 1294 CP_a163_cover2State "5";
BA_ "Confidence" SG_ 1294 CP_a164_VC_tempAmbientFiltered 1;
BA_ "GenSigSNA" SG_ 1294 CP_a164_VC_tempAmbientFiltered "0";
BA_ "Confidence" SG_ 1294 CP_a164_minInternalPinTemp 1;
BA_ "GenSigSNA" SG_ 1294 CP_a164_minInternalPinTemp "255";
BA_ "Confidence" SG_ 1294 CP_a173_cover1OpenCounts 1;
BA_ "Confidence" SG_ 1294 CP_a173_cover2OpenCounts 1;
BA_ "Confidence" SG_ 1294 CP_a173_cover1State 1;
BA_ "GenSigSNA" SG_ 1294 CP_a173_cover1State "5";
BA_ "Confidence" SG_ 1294 CP_a173_cover2State 1;
BA_ "GenSigSNA" SG_ 1294 CP_a173_cover2State "5";
BA_ "Confidence" SG_ 798 CP_matrixIndex 1;
BA_ "SystemSignalLongSymbol" SG_ 798 CP_a112_inletHeaterIrrationalTem "CP_a112_inletHeaterIrrationalTemperature";
BA_ "SystemSignalLongSymbol" SG_ 798 CP_a117_inletHeaterUnableToRegul "CP_a117_inletHeaterUnableToRegulate";
BA_ "SystemSignalLongSymbol" SG_ 798 CP_a162_pilotEdgeDetectionFailed "CP_a162_pilotEdgeDetectionFailedCN";
BA_ "SystemSignalLongSymbol" SG_ 798 CP_a164_latchRedisengageRequeste "CP_a164_latchRedisengageRequested";
BA_ "SystemSignalLongSymbol" SG_ 798 CP_a166_faultLineMismatchDetecte "CP_a166_faultLineMismatchDetected";
BA_ "SystemSignalLongSymbol" SG_ 798 CP_a177_incompatibleV2lDeviceDet "CP_a177_incompatibleV2lDeviceDetected";
BA_ "Confidence" SG_ 1085 CP_hvChargeStatus_log 1;
BA_ "Confidence" SG_ 1085 CP_chargeShutdownRequest_log 1;
BA_ "Confidence" SG_ 1085 CP_acChargeCurrentLimit_log 1;
BA_ "Confidence" SG_ 1085 CP_internalMaxDcCurrentLimit_log 1;
BA_ "Confidence" SG_ 1085 CP_internalMaxAcCurrentLimit_log 1;
BA_ "Confidence" SG_ 1085 CP_evseChargeType_log 1;
BA_ "Confidence" SG_ 1085 CP_chgLimitMode_log 1;
BA_ "Confidence" SG_ 669 CP_evseOutputDcCurrent 0;
BA_ "Confidence" SG_ 669 CP_evseOutputDcVoltage 0;
BA_ "Confidence" SG_ 669 CP_evseOutputDcCurrentStale 0;
BA_ "Confidence" SG_ 541 CP_evseAccept 0;
BA_ "Confidence" SG_ 541 CP_evseRequest 0;
BA_ "Confidence" SG_ 541 CP_proximity 0;
BA_ "GenSigSNA" SG_ 541 CP_proximity "0";
BA_ "Confidence" SG_ 541 CP_pilot 0;
BA_ "GenSigSNA" SG_ 541 CP_pilot "7";
BA_ "Confidence" SG_ 541 CP_digitalCommsEstablished 0;
BA_ "Confidence" SG_ 541 CP_pilotCurrent 0;
BA_ "Confidence" SG_ 541 CP_cableType 0;
BA_ "GenSigSNA" SG_ 541 CP_cableType "4";
BA_ "Confidence" SG_ 541 CP_iecPilotState 0;
BA_ "GenSigSNA" SG_ 541 CP_iecPilotState "9";
BA_ "Confidence" SG_ 541 CP_plcSupported 0;
BA_ "Confidence" SG_ 541 CP_cableCurrentLimit 0;
BA_ "Confidence" SG_ 541 CP_teslaSwcanState 0;
BA_ "Confidence" SG_ 541 CP_evseChargeType_UI 0;
BA_ "Confidence" SG_ 541 CP_gbState 0;
BA_ "Confidence" SG_ 541 CP_gbdcStopChargeReason 0;
BA_ "Confidence" SG_ 541 CP_gbdcFailureReason 0;
BA_ "Confidence" SG_ 541 CP_gbdcChargeAttempts 0;
BA_ "Confidence" SG_ 541 CP_acChargeState 0;
BA_ "Confidence" SG_ 541 CP_teslaDcState 1;
BA_ "Confidence" SG_ 1885 CP_loggingFastSelect 1;
BA_ "Confidence" SG_ 1885 CP_inductiveSensor_raw 0;
BA_ "Confidence" SG_ 1885 CP_doorOpenActuationTime 0;
BA_ "Confidence" SG_ 1885 CP_doorCloseActuationTime 0;
BA_ "Confidence" SG_ 1885 CP_chargeCableSecured 0;
BA_ "Confidence" SG_ 1885 CP_chargeCablePresent 0;
BA_ "Confidence" SG_ 1885 CP_latchCheckAvailable 0;
BA_ "Confidence" SG_ 1885 CP_UHF_controlState 0;
BA_ "Confidence" SG_ 1885 CP_proximityV 0;
BA_ "Confidence" SG_ 1885 CP_proximityV_GBCC1 0;
BA_ "Confidence" SG_ 1885 CP_proximityV_GBCC2 0;
BA_ "Confidence" SG_ 1885 CP_doorPot 0;
BA_ "Confidence" SG_ 1885 CP_doorPresenceHallSensorV 1;
BA_ "Confidence" SG_ 1885 CP_doorOpenRequest 0;
BA_ "Confidence" SG_ 1885 CP_doorOpenEndOfDriveReason 0;
BA_ "Confidence" SG_ 1885 CP_coverClosed 0;
BA_ "Confidence" SG_ 1885 CP_doorCloseEndOfDriveReason 0;
BA_ "Confidence" SG_ 1885 CP_doorCloseRequest 0;
BA_ "Confidence" SG_ 1885 CP_latchDisengagingTime 0;
BA_ "Confidence" SG_ 1885 CP_latchEngagingTime 0;
BA_ "Confidence" SG_ 1885 CP_latchDisengagingStopReason 0;
BA_ "Confidence" SG_ 1885 CP_latchEngagingStopReason 1;
BA_ "Confidence" SG_ 1885 CP_doorIdDetectionState 0;
BA_ "GenSigSNA" SG_ 1885 CP_doorIdDetectionState "0";
BA_ "Confidence" SG_ 1885 CP_doorIdDetectedBin 0;
BA_ "Confidence" SG_ 2042 CP_loggingSlowSelect 1;
BA_ "Confidence" SG_ 2042 CP_UHF_chipState 0;
BA_ "Confidence" SG_ 2042 CP_UHF_rssi 0;
BA_ "Confidence" SG_ 2042 CP_UHF_rxOverflow 0;
BA_ "Confidence" SG_ 2042 CP_UHF_rxNumBytes 0;
BA_ "Confidence" SG_ 2042 CP_UHF_selfTestRssi 0;
BA_ "Confidence" SG_ 2042 CP_latchI 0;
BA_ "Confidence" SG_ 2042 CP_inlet1HarnessIdState 0;
BA_ "GenSigSNA" SG_ 2042 CP_inlet1HarnessIdState "0";
BA_ "Confidence" SG_ 2042 CP_inlet1HarnessIdValue 0;
BA_ "Confidence" SG_ 2042 CP_inlet2HarnessIdState 0;
BA_ "GenSigSNA" SG_ 2042 CP_inlet2HarnessIdState "0";
BA_ "Confidence" SG_ 2042 CP_inlet2HarnessIdValue 0;
BA_ "Confidence" SG_ 2042 CP_inletHeaterState 0;
BA_ "Confidence" SG_ 2042 CP_inletHeaterDuty 0;
BA_ "Confidence" SG_ 2042 CP_nvm_dataValid 0;
BA_ "Confidence" SG_ 2042 CP_doorOpenLimiterMaxCount 1;
BA_ "Confidence" SG_ 2042 CP_doorOpenLimiterMaxRequestType 1;
BA_ "Confidence" SG_ 2042 CP_doorCloseLimiterMaxCount 1;
BA_ "Confidence" SG_ 2042 CP_doorCloseLimiterMaxRequestTyp 1;
BA_ "SystemSignalLongSymbol" SG_ 2042 CP_doorCloseLimiterMaxRequestTyp "CP_doorCloseLimiterMaxRequestType";
VAL_ 946 BMS_log2MuxId 83 "MUX_83" 82 "MUX_82" 81 "MUX_81" 80 "MUX_80" 79 "MUX_79" 78 "MUX_78" 77 "MUX_77" 76 "MUX_76" 75 "MUX_75" 74 "MUX_74" 73 "MUX_73" 72 "MUX_72" 71 "MUX_71" 70 "MUX_70" 69 "MUX_69" 68 "MUX_68" 67 "MUX_67" 66 "MUX_66" 65 "MUX_65" 64 "MUX_64" 63 "MUX_63" 62 "MUX_62" 61 "MUX_61" 60 "MUX_60" 59 "MUX_59" 58 "MUX_58" 57 "MUX_57" 56 "MUX_56" 55 "LIFE_MODEL_HIST_SUMMARY_DATA" 54 "LIFE_MODEL_STORAGE_HIST_DATA" 53 "SPME_MAX_SOC_BRICK_DATA" 52 "SPME_MIN_SOC_BRICK_DATA" 51 "SPME_DATA_3" 50 "SPME_BRICK_1_DATA_2" 49 "SPME_BRICK_1_DATA_1" 48 "SPME_PACK_LEVEL" 47 "BRICK_BLEED_TIMES_5" 46 "HISTOGRAMS_SUMMARY" 45 "SOH" 44 "CAC4" 43 "ISOLATION" 42 "BRICK_BLEED_TIMES_4" 41 "BRICK_BLEED_TIMES_3" 40 "BRICK_BLEED_TIMES_2" 39 "BRICK_BLEED_TIMES_1" 38 "LIFE_MODEL" 37 "BRICK_BALANCE_4" 36 "BRICK_BALANCE_3" 35 "BRICK_BALANCE_2" 34 "BRICK_BALANCE_1" 33 "ALPHA_1" 32 "HISTOGRAMS_4" 31 "HISTOGRAMS_3" 30 "HISTOGRAMS_2" 29 "HISTOGRAMS_1" 28 "HISTOGRAMS_0" 27 "VSH_RES_3" 26 "VSH_RES_2" 25 "VSH_RES_1" 24 "SOC_BY_OCV_CORRECTION" 23 "BRICK_VOLTAGE_CHANGE" 22 "CAC3" 21 "ENERGY_AND_REST_DATA" 20 "FC_LINK_LEAKAGE_TEST" 19 "ENERGY_RESERVE" 18 "HV_CHAIN_MODEL" 17 "NEG_CTR_HEALTH_4" 16 "NEG_CTR_HEALTH_3" 15 "NEG_CTR_HEALTH_2" 14 "NEG_CTR_HEALTH_1" 13 "POS_CTR_HEALTH_4" 12 "POS_CTR_HEALTH_3" 11 "POS_CTR_HEALTH_2" 10 "POS_CTR_HEALTH_1" 9 "CTR_RESISTANCE" 8 "100HZ_1KHZ_TASK_STATS" 7 "10HZ_TASK_STATS" 6 "1HZ_TASK_STATS" 5 "AHR_COUNTER" 4 "CHARGING" 3 "VSH_TEST" 2 "FLOOD_PORT" 1 "CAC2" 0 "CAC1" ;
VAL_ 946 BMS_hvChain_iLimit 16383 "SNA" ;
VAL_ 946 BMS_hvChain_limitingState 511 "SNA" ;
VAL_ 946 BMS_hvChain_limitingStateTempera -4096 "SNA" ;
VAL_ 946 BMS_fcLinkTestDecayTime 1023 "SNA" ;
VAL_ 946 BMS_idealEnergyFloor 1023 "SNA" ;
VAL_ 946 BMS_dynamicEnergyBuffer 1023 "SNA" ;
VAL_ 946 BMS_dSocNormalizedMin 4095 "SNA" ;
VAL_ 946 BMS_dSocNormalizedFiltMin 4095 "SNA" ;
VAL_ 946 BMS_dSocMinAlpha 4095 "SNA" ;
VAL_ 946 BMS_dSocCacMargin 511 "SNA" ;
VAL_ 946 BMS_lifeModelAvgTempSeverity 31 "SNA" ;
VAL_ 946 BMS_lifeModelDepthOfDischargeSev 255 "SNA" ;
VAL_ 946 BMS_lifeModelHistogramCapacityLo 511 "SNA" ;
VAL_ 946 BMS_lifeModelHistogramBrickCapac 8191 "SNA" ;
VAL_ 946 BMS_lifeModelDcrGrowthPercent -8192 "SNA" ;
VAL_ 946 BMS_nominalFullPackEnergyRaw 65535 "SNA" ;
VAL_ 946 BMS_userChargeCalibratingReason 2 "USR_CHG_CALIBRATING_RUBBER_BANDING_HOLD" 1 "USR_CHG_CALIBRATING_FULL_CHARGE" 0 "USR_CHG_CALIBRATING_INACTIVE" ;
VAL_ 946 BMS_nominalEnergyRemainingBuffer 65535 "SNA" ;
VAL_ 946 BMS_idealEnergyRemainingBuffered 65535 "SNA" ;
VAL_ 946 BMS_largestCacSpreadErrorLower 4095 "SNA" ;
VAL_ 946 BMS_lifeModelAverageCac 4095 "SNA" ;
VAL_ 946 BMS_lifeModelCacBrick1 4095 "SNA" ;
VAL_ 946 BMS_lifeModelAverageOffset -512 "SNA" ;
VAL_ 946 BMS_lifeModelMaxCacBrickId 255 "SNA" ;
VAL_ 946 BMS_lifeModelMaxCac 4095 "SNA" ;
VAL_ 946 BMS_lifeModelMinCacBrickId 255 "SNA" ;
VAL_ 946 BMS_lifeModelMinCac 4095 "SNA" ;
VAL_ 946 BMS_restingPointCacAvg 4095 "SNA" ;
VAL_ 946 BMS_cacEstimationSource 2 "CAC_SOURCE_LIFE_MODEL" 1 "CAC_SOURCE_RESTING_POINT_CAC" 0 "CAC_SOURCE_UNKNOWN" ;
VAL_ 946 BMS_synchronizedCacMaxRaw 4095 "SNA" ;
VAL_ 946 BMS_synchronizedCacMinRaw 4095 "SNA" ;
VAL_ 946 BMS_sohEnergy 2047 "SNA" ;
VAL_ 946 BMS_fullCapacitySohEnergy 2047 "SNA" ;
VAL_ 946 BMS_calibratedCapacitySohEnergy 2047 "SNA" ;
VAL_ 946 BMS_estimatedCapacitySohEnergy 2047 "SNA" ;
VAL_ 946 BMS_prevUserFacingSohEnergy 2047 "SNA" ;
VAL_ 946 BMS_stateOfHealthMinCac 8191 "SNA" ;
VAL_ 946 BMS_lifeModelStorageLossPackAge 16383 "SNA" ;
VAL_ 946 BMS_lifeModelThroughputCycleCoun 4095 "SNA" ;
VAL_ 946 BMS_lifeModelThroughputDcrCycleC 4095 "SNA" ;
VAL_ 946 BMS_stateOfHealth 1023 "SNA" ;
VAL_ 914 BMS_packConfigMultiplexer 1 "Mux1" 0 "Mux0" ;
VAL_ 914 BMS_reservedConfig_0 31 "BMS_CONFIG_31" 30 "BMS_CONFIG_30" 29 "BMS_CONFIG_29" 28 "BMS_CONFIG_28" 27 "BMS_CONFIG_27" 26 "BMS_CONFIG_26" 25 "BMS_CONFIG_25" 24 "BMS_CONFIG_24" 23 "BMS_CONFIG_23" 22 "BMS_CONFIG_22" 21 "BMS_CONFIG_21" 20 "BMS_CONFIG_20" 19 "BMS_CONFIG_19" 18 "BMS_CONFIG_18" 17 "BMS_CONFIG_17" 16 "BMS_CONFIG_16" 15 "BMS_CONFIG_15" 14 "BMS_CONFIG_14" 13 "BMS_CONFIG_13" 12 "BMS_CONFIG_12" 11 "BMS_CONFIG_11" 10 "BMS_CONFIG_10" 9 "BMS_CONFIG_9" 8 "BMS_CONFIG_8" 7 "BMS_CONFIG_7" 6 "BMS_CONFIG_6" 5 "BMS_CONFIG_5" 4 "BMS_CONFIG_4" 3 "BMS_CONFIG_3" 2 "BMS_CONFIG_2" 1 "BMS_CONFIG_1" 0 "BMS_CONFIG_0" ;
VAL_ 914 BMS_moduleType 5 "BMS_MOD_TYPE_5" 4 "BMS_MOD_TYPE_4" 3 "BMS_MOD_TYPE_3" 2 "BMS_MOD_TYPE_2" 1 "BMS_MOD_TYPE_1" 0 "BMS_MOD_TYPE_UNKNOWN" ;
VAL_ 914 BMS_thermalPackType 9 "E3D_40P" 8 "E3D" 7 "BLADERUNNER_E1" 6 "BFF00S" 5 "P2" 4 "BFF00_E1" 3 "CATL_E1" 2 "E3" 1 "E1" 0 "UNKNOWN" ;
VAL_ 914 BMS_standbySupplyContinuousPower 3 "17W" 2 "16W" 1 "4W" 0 "0W" ;
VAL_ 594 BMS_powerLimitsState 1 "POWER_CALCULATED_FOR_DRIVE" 0 "POWER_NOT_CALCULATED_FOR_DRIVE" ;
VAL_ 594 BMS_instantChargePowerCapability 65535 "SNA" ;
VAL_ 674 BMS_acRippleFrequencyRequest 63 "SNA" ;
VAL_ 674 BMS_acRippleRequest 4 "RIPPLE_FAULTED" 3 "RIPPLE_ON" 2 "RIPPLE_STANDBY" 1 "RIPPLE_OFF" 0 "RIPPLE_NOT_SUPPORTED" ;
VAL_ 658 BMS_beginningOfLifePackEnergy 1023 "SNA" ;
VAL_ 658 BMS_battTempPct 255 "SNA" ;
VAL_ 658 BMS_userChargeCurrentLimitMode 4 "USR_CHG_LIMIT_EVSE_RELOCATION_RECOMMENDED" 3 "USR_CHG_LIMIT_HIGH_SOC" 2 "USR_CHG_LIMIT_BATT_TEMP_LOW" 1 "USR_CHG_LIMIT_EVSE" 0 "USR_CHG_LIMIT_NONE" ;
VAL_ 530 BMS_contactorState 6 "BMS_CTRSET_BLOCKED" 5 "BMS_CTRSET_WELDED" 4 "BMS_CTRSET_CLOSED" 3 "BMS_CTRSET_CLOSING" 2 "BMS_CTRSET_OPENING" 1 "BMS_CTRSET_OPEN" 0 "BMS_CTRSET_SNA" ;
VAL_ 530 BMS_userChargeStatus 6 "BMS_CALIBRATING" 5 "BMS_CHARGE_STOPPED" 4 "BMS_CHARGE_COMPLETE" 3 "BMS_CHARGING" 2 "BMS_ABOUT_TO_CHARGE" 1 "BMS_NO_POWER" 0 "BMS_DISCONNECTED" ;
VAL_ 530 BMS_totalBatteryPower -65536 "SNA" ;
VAL_ 530 BMS_state 10 "BMS_DIAG" 9 "BMS_SNA" 8 "BMS_TEST" 7 "BMS_WELD" 6 "BMS_FAULT" 5 "BMS_CLEAR_FAULT" 4 "BMS_FEIM" 3 "BMS_CHARGE" 2 "BMS_SUPPORT" 1 "BMS_DRIVE" 0 "BMS_STANDBY" ;
VAL_ 530 BMS_diLimpRequest 1 "LIMP_REQUEST_WELDED" 0 "LIMP_REQUEST_NONE" ;
VAL_ 530 BMS_chgPowerAvailable 4095 "SNA" ;
VAL_ 530 BMS_smStateRequest 10 "BMS_DIAG" 9 "BMS_SNA" 8 "BMS_TEST" 7 "BMS_WELD" 6 "BMS_FAULT" 5 "BMS_CLEAR_FAULT" 4 "BMS_FEIM" 3 "BMS_CHARGE" 2 "BMS_SUPPORT" 1 "BMS_DRIVE" 0 "BMS_STANDBY" ;
VAL_ 530 BMS_hvState 6 "HV_UP" 5 "HV_UP_FOR_DC_CHARGE" 4 "HV_UP_FOR_CHARGE" 3 "HV_UP_FOR_DRIVE" 2 "HV_GOING_DOWN" 1 "HV_COMING_UP" 0 "HV_DOWN" ;
VAL_ 2028 BMS_cellTempTargetMode 11 "V2X_SESSION" 10 "PASSIVE_COOL_ON_NAV" 9 "ACTIVE_COOL_ON_NAV" 8 "SOH_HEAT_PACK" 7 "DRAGSTRIP" 6 "PASSIVE_HEAT_ON_NAV" 5 "ACTIVE_HEAT_ON_NAV" 4 "DISCONNECTED_PRECONDITION" 3 "CONNECTED_PRECONDITION" 2 "HIGH_POWER_CHARGE" 1 "LOW_POWER_CHARGE" 0 "DEFAULT" ;
VAL_ 754 BMS_nmKeepAwakeReason 7 "BMS_KEEPAWAKE_REASON_PRECONDITIONING" 6 "BMS_KEEPAWAKE_REASON_CP_ACTIVE" 5 "BMS_KEEPAWAKE_REASON_BMS_ACTIVE" 4 "BMS_KEEPAWAKE_REASON_HVP_ACTIVE" 3 "BMS_KEEPAWAKE_REASON_FC_CTR_CLEANING" 2 "BMS_KEEPAWAKE_REASON_CRITICAL_ALERT" 1 "BMS_KEEPAWAKE_REASON_CTRS_CLOSED" 0 "BMS_KEEPAWAKE_REASON_NONE_SNA" ;
VAL_ 754 BMS_nmWakeUpReason 4 "BMS_WAKEUP_REASON_CRITICALALERT" 3 "BMS_WAKEUP_REASON_WANTTOCHARGE" 2 "BMS_WAKEUP_REASON_CAN_HVS" 1 "BMS_WAKEUP_REASON_CAN_VEH" 0 "BMS_WAKEUP_REASON_NONE" ;
VAL_ 810 BMS_isolationResistance 1023 "SNA" ;
VAL_ 797 CC_chgStatus2Index 0 "Mux0" ;
VAL_ 797 CC_buttonState 1 "CC_BUTTON_PRESSED" 0 "CC_BUTTON_RELEASED" ;
VAL_ 1294 CP_alertID 187 "a187_highStackUsage" 186 "a186_spiDmaFailure" 185 "a185_pncAuthRejection" 184 "a184_certChangeEvent" 183 "a183_certManagerError" 182 "a182_pncdCommsError" 179 "a179_evseCommsTlsError" 177 "a177_incompatibleV2lDeviceDetected" 175 "a175_fwdedMsgDropped" 174 "a174_fwdedMsgLoadWarning" 173 "a173_coverOpenAcChgBlocked" 172 "a172_triggerOdin" 167 "a167_doorIdIrrational" 166 "a166_faultLineMismatchDetected" 165 "a165_proxWiggleDetected" 164 "a164_latchRedisengageRequested" 163 "a163_coverOpenDcChgBlocked" 162 "a162_pilotEdgeDetectionFailedCN" 161 "a161_badPilotDiodeDetectedCN" 160 "a160_latchDisengageInDcCharge" 159 "a159_swcanHealthCheckFailed" 158 "a158_doorCloseRateLimiter" 157 "a157_doorOpenRateLimiter" 156 "a156_gbdcPrechargingConcern" 155 "a155_hallPresenceRationality" 154 "a154_acChargingStoppedOT" 153 "a153_thermalAcLimitActive" 152 "a152_pilotEdgeDetectionFailed" 151 "a151_badPilotDiodeDetected" 150 "a150_railToggleTimeout" 149 "a149_pilotPeriodInvalid" 148 "a148_bldcTachFeedbackMia" 147 "a147_inductiveRecoveredMia" 146 "a146_ccsEvseMalfunction" 145 "a145_modemAppLoadFailedNA" 144 "a144_nvmInitFailed" 143 "a143_unsupportedChargeAdapter" 142 "a142_gbdcScConnFault" 141 "a141_chademoAdapterFault" 140 "a140_superchargerFaulted" 139 "a139_pilotFaulted" 138 "a138_swcanCommsAcEvseFaulted" 137 "a137_plcForwardError" 136 "a136_sdpSideReqFailed" 135 "a135_sdpAttemptsFailed" 134 "a134_plcModemNotExpected" 133 "a133_proxNeverLatched" 132 "a132_contractAuthTimeout" 131 "a131_evseCommTimeout" 130 "a130_bldcDriverCommsRecovered" 129 "a129_bldcDriverCommsFailed" 128 "a128_lostCommsVC" 127 "a127_lostCommsHVLINK" 126 "a126_wakeOnUhfFault" 125 "a125_unexpectedLVJuiceState" 124 "a124_ivledFault" 123 "a123_latchPotIrrational" 122 "a122_plcModemFailure" 121 "a121_PLCRLY_lostCommsCP" 120 "a120_comboAdapterFoldback" 119 "a119_plcTransmitFailure" 118 "a118_iecComboLockUp" 117 "a117_inletHeaterUnableToRegulate" 116 "a116_misconfigurationDetected" 115 "a115_unexpectedTcan1145State" 114 "a114_ccsEvseFailed" 113 "a113_inletHeaterShortCircuit" 112 "a112_inletHeaterIrrationalTemperature" 111 "a111_inletHeaterUnableToHeat" 110 "a110_thermalVelocityHigh" 109 "a109_thermistorIrrational" 108 "a108_chademoOvertempFault" 107 "a107_chademoFoldbackActive" 106 "a106_uhfReceiverReset" 105 "a105_hwUnableToSleep" 104 "a104_uhfResetSuccessful" 103 "a103_proximityPeDisconnected" 102 "a102_wcOvertempFault" 101 "a101_wcFoldbackActive" 100 "a100_inletHarnessIdIrrational" 99 "a099_cableStateUnknown" 98 "a098_proximityWake" 97 "a097_modeTransitionFailure" 96 "a096_pilotWake" 95 "a095_thermalDcLimitActive" 94 "a094_inductiveResetSuccessful" 93 "a093_modemLoadedWithReset" 92 "a092_modemAppLoadFailed" 91 "a091_wrongSuperchargerHandle" 90 "a090_ccsEvseLowIso" 89 "a089_plcConfigMismatch" 88 "a088_dcTempModelDeviation" 87 "a087_dcTempModelFault" 86 "a086_dcPinTempIrrational" 85 "a085_dcPinTempFaulted" 84 "a084_proxPeDisconnected_gb" 83 "a083_watchdogTraceData" 82 "a082_powerOnReset" 81 "a081_swException" 80 "a080_taskStackOverflow" 79 "a079_cableNotSecuredCold" 78 "a078_latchNotDisengagedCold" 77 "a077_invalidMacAddress" 76 "a076_LDC1612errorWatchdog" 75 "a075_v2gCommsFailure" 74 "a074_failedToEstablishV2gComm" 73 "a073_iecComboShutdown" 72 "a072_v2gEvccTimeout" 71 "a071_exiDecodeFailure" 70 "a070_doorInductiveSensorReset" 69 "a069_doorInductiveSensorError" 68 "a068_doorSensorMismatch" 67 "a067_gbdcConnFault" 66 "a066_proxLatchedIdlePilot" 65 "a065_selfTestFailed" 64 "a064_superchargingBlocked" 63 "a063_scUpdateInProgress" 62 "a062_scOutOfService" 61 "a061_uhfReceiverMIA" 60 "a060_lostCommsPCS" 59 "a059_swcanError" 58 "a058_acChargeRetryPending" 57 "a057_ccs1AdapterBtnPress" 56 "a056_proxDisconnected" 55 "a055_chargeStoppedNoPilot" 54 "a054_cableNotSecured" 53 "a053_proxLatchedNoPilot" 52 "a052_chademoNotSupported" 51 "a051_doorInductiveSensorMIA" 50 "a050_latchNotConnected" 49 "a049_multipleCablesDetected" 48 "a048_lostCommsUI" 47 "a047_lostCommsVCFRONT" 46 "a046_lostCommsEVSE" 45 "a045_lostCommsVCSEC" 44 "a044_lostCommsHVP" 43 "a043_doorPotIrrational" 42 "a042_doorAssemblyBroken" 41 "a041_doorSensorUnplugged" 40 "a040_doNotUse" 39 "a039_latchMovement_2" 38 "a038_latchNotBlocking" 37 "a037_latchNotEngaged" 36 "a036_latchNotDisengaged" 35 "a035_latchMovement_1" 34 "a034_calibrationIncomplete" 33 "a033_spiOpen" 32 "a032_doorOpenExpectedClosed" 31 "a031_doorClosedCommandedOpen" 30 "a030_busOff" 29 "a029_doorClosedProxPilot" 28 "a028_insertEnableMismatch" 27 "a027_doorSensorOutOfSpec" 26 "a026_networkManagement" 25 "a025_ledsOC" 24 "a024_ledsUC" 23 "a023_gbdcSessionFailed" 22 "a022_zeroVuv" 21 "a021_zeroVov" 20 "a020_threeVuv" 19 "a019_threeVov" 18 "a018_fiveVuv" 17 "a017_fiveVov" 16 "a016_apsVuv" 15 "a015_apsVov" 14 "a014_lostCommsCHG" 13 "a013_lostCommsGTW" 12 "a012_ledDriver" 11 "a011_eeprom" 10 "a010_pilotRationality" 9 "a009_coverOpenAllChgBlocked" 8 "a008_memoryError" 7 "a007_watchdog" 6 "a006_lostCommsBMS" 5 "a005_gbdcLiveDisconnect" 4 "a004_proximityRationality" 3 "a003_canError" 2 "a002_canTx" 1 "a001_canRx" 0 "ALERT_DO_NOT_USE_ZERO" ;
VAL_ 1294 CP_alertType 1 "SET" 0 "CLEARED" ;
VAL_ 1294 CP_a005_gbdcState 15 "TESTER_PRESENT" 14 "FAULTED" 13 "RETRY_CHARGE" 12 "ERROR_HANDLING" 11 "END_OF_CHARGE" 10 "CHARGE_DISABLING" 9 "STOP_CHARGE_REQUESTED" 8 "CHARGING" 7 "READY_TO_CHARGE" 6 "VEH_PACK_PRECHARGE" 5 "CHARGE_PARAM_CONFIG" 4 "RECOGNITION" 3 "HANDSHAKING_EXT_ISO" 2 "COMMS_RECEIVED" 1 "WAIT_FOR_COMMS" 0 "INACTIVE" ;
VAL_ 1294 CP_a009_cover1State 5 "SNA" 4 "SHORT_TO_VBAT" 3 "SHORT_TO_GND" 2 "OPEN" 1 "CLOSED" 0 "BOOT_UP_CLOSED" ;
VAL_ 1294 CP_a009_cover2State 5 "SNA" 4 "SHORT_TO_VBAT" 3 "SHORT_TO_GND" 2 "OPEN" 1 "CLOSED" 0 "BOOT_UP_CLOSED" ;
VAL_ 1294 CP_a011_eepromErrorType 5 "VERSION" 4 "LOST" 3 "CRC" 2 "WRITE" 1 "READ" 0 "OPEN" ;
VAL_ 1294 CP_a023_stopChargeReason 8 "PARAM_MISMATCH" 7 "SUPERCHARGER_COMMS_TIMEOUT" 6 "LIVE_DISCONNECT" 5 "EVSE_CRITICAL_FAULT" 4 "EVSE_FAULT" 3 "COMMS_TIMEOUT" 2 "EVSE_REQUESTED" 1 "VEH_REQUESTED" 0 "STOP_REASON_NONE" ;
VAL_ 1294 CP_a023_failureReason 3 "CRITICAL_FAILURE" 2 "SHUTDOWN_FAILURE" 1 "ATTEMPTS_EXPIRED" 0 "FAILURE_NONE" ;
VAL_ 1294 CP_a029_CP_pilot 7 "SNA" 6 "UNUSED_6" 5 "INVALID" 4 "IDLE" 3 "FAST_CHARGE" 2 "LINE_CHARGE" 1 "FAULTED" 0 "NONE" ;
VAL_ 1294 CP_a029_CP_proximity 3 "LATCHED" 2 "UNLATCHED" 1 "DISCONNECTED" 0 "SNA" ;
VAL_ 1294 CP_a035_latchState 3 "BLOCKING" 2 "ENGAGED" 1 "DISENGAGED" 0 "SNA" ;
VAL_ 1294 CP_a035_inletID 3 "GBDC" 2 "GBAC" 1 "IEC" 0 "SAE" ;
VAL_ 1294 CP_a036_latchState 3 "BLOCKING" 2 "ENGAGED" 1 "DISENGAGED" 0 "SNA" ;
VAL_ 1294 CP_a036_inletID 3 "GBDC" 2 "GBAC" 1 "IEC" 0 "SAE" ;
VAL_ 1294 CP_a037_latchState 3 "BLOCKING" 2 "ENGAGED" 1 "DISENGAGED" 0 "SNA" ;
VAL_ 1294 CP_a037_inletID 3 "GBDC" 2 "GBAC" 1 "IEC" 0 "SAE" ;
VAL_ 1294 CP_a038_latchState 3 "BLOCKING" 2 "ENGAGED" 1 "DISENGAGED" 0 "SNA" ;
VAL_ 1294 CP_a038_inletID 3 "GBDC" 2 "GBAC" 1 "IEC" 0 "SAE" ;
VAL_ 1294 CP_a049_proximity 3 "LATCHED" 2 "UNLATCHED" 1 "DISCONNECTED" 0 "SNA" ;
VAL_ 1294 CP_a054_latchState 3 "BLOCKING" 2 "ENGAGED" 1 "DISENGAGED" 0 "SNA" ;
VAL_ 1294 CP_a054_CP_proximity 3 "LATCHED" 2 "UNLATCHED" 1 "DISCONNECTED" 0 "SNA" ;
VAL_ 1294 CP_a054_inletID 3 "GBDC" 2 "GBAC" 1 "IEC" 0 "SAE" ;
VAL_ 1294 CP_a056_latchState 3 "BLOCKING" 2 "ENGAGED" 1 "DISENGAGED" 0 "SNA" ;
VAL_ 1294 CP_a056_CP_proximity 3 "LATCHED" 2 "UNLATCHED" 1 "DISCONNECTED" 0 "SNA" ;
VAL_ 1294 CP_a058_CP_pilot 7 "SNA" 6 "UNUSED_6" 5 "INVALID" 4 "IDLE" 3 "FAST_CHARGE" 2 "LINE_CHARGE" 1 "FAULTED" 0 "NONE" ;
VAL_ 1294 CP_a058_CC_pilot 3 "SNA" 2 "FAULTED" 1 "IDLE" 0 "READY" ;
VAL_ 1294 CP_a058_FC_status 15 "NODATA" 14 "MALFUNCTION" 13 "NOTCOMPATIBLE" 7 "POST_OUT_OF_SERVICE" 6 "EXT_ISOACTIVE" 5 "INT_ISOACTIVE" 4 "DEPRECATED_4" 3 "DEPRECATED_3" 2 "UPDATE_IN_PROGRESS" 1 "READY" 0 "NOTREADY_SNA" ;
VAL_ 1294 CP_a058_latchState 3 "BLOCKING" 2 "ENGAGED" 1 "DISENGAGED" 0 "SNA" ;
VAL_ 1294 CP_a058_CP_proximity 3 "LATCHED" 2 "UNLATCHED" 1 "DISCONNECTED" 0 "SNA" ;
VAL_ 1294 CP_a061_controlState 10 "FAULT" 9 "SLEEP" 8 "HANDLE_FOUND" 7 "READ_RXFIFO" 6 "CHECK_RX" 5 "RX" 4 "PREPARE_RX" 3 "CALIBRATE" 2 "IDLE" 1 "CONFIG" 0 "INIT" ;
VAL_ 1294 CP_a061_lastControlState 10 "FAULT" 9 "SLEEP" 8 "HANDLE_FOUND" 7 "READ_RXFIFO" 6 "CHECK_RX" 5 "RX" 4 "PREPARE_RX" 3 "CALIBRATE" 2 "IDLE" 1 "CONFIG" 0 "INIT" ;
VAL_ 1294 CP_a062_FC_status 15 "NODATA" 14 "MALFUNCTION" 13 "NOTCOMPATIBLE" 7 "POST_OUT_OF_SERVICE" 6 "EXT_ISOACTIVE" 5 "INT_ISOACTIVE" 4 "DEPRECATED_4" 3 "DEPRECATED_3" 2 "UPDATE_IN_PROGRESS" 1 "READY" 0 "NOTREADY_SNA" ;
VAL_ 1294 CP_a062_FC_type 7 "SNA" 6 "OTHER" 5 "MC_EVSE" 4 "COMBO" 3 "CC_EVSE" 2 "GB" 1 "CHADEMO" 0 "SUPERCHARGER" ;
VAL_ 1294 CP_a063_FC_status 15 "NODATA" 14 "MALFUNCTION" 13 "NOTCOMPATIBLE" 7 "POST_OUT_OF_SERVICE" 6 "EXT_ISOACTIVE" 5 "INT_ISOACTIVE" 4 "DEPRECATED_4" 3 "DEPRECATED_3" 2 "UPDATE_IN_PROGRESS" 1 "READY" 0 "NOTREADY_SNA" ;
VAL_ 1294 CP_a063_FC_type 7 "SNA" 6 "OTHER" 5 "MC_EVSE" 4 "COMBO" 3 "CC_EVSE" 2 "GB" 1 "CHADEMO" 0 "SUPERCHARGER" ;
VAL_ 1294 CP_a066_proximity 3 "LATCHED" 2 "UNLATCHED" 1 "DISCONNECTED" 0 "SNA" ;
VAL_ 1294 CP_a071_expectedMessage 15 "NUM_MSG" 14 "MSG_NONE" 13 "SESSION_STOP" 12 "WELDING_DETECTION" 11 "POWER_DELIVERY_END" 10 "CURRENT_DEMAND" 9 "POWER_DELIVERY_START" 8 "PRECHARGE" 7 "CABLE_CHECK" 6 "CHARGE_PARAMETER_DISCOVERY" 5 "CONTRACT_AUTHENTICATION" 4 "PAYMENT_DETAILS" 3 "SERVICE_PAYMENT_SELECTION" 2 "SERVICE_DISCOVERY" 1 "SESSION_SETUP" 0 "SUPPORTED_APP_PROTOCOL" ;
VAL_ 1294 CP_a072_currentMessage 15 "NUM_MSG" 14 "MSG_NONE" 13 "SESSION_STOP" 12 "WELDING_DETECTION" 11 "POWER_DELIVERY_END" 10 "CURRENT_DEMAND" 9 "POWER_DELIVERY_START" 8 "PRECHARGE" 7 "CABLE_CHECK" 6 "CHARGE_PARAMETER_DISCOVERY" 5 "CONTRACT_AUTHENTICATION" 4 "PAYMENT_DETAILS" 3 "SERVICE_PAYMENT_SELECTION" 2 "SERVICE_DISCOVERY" 1 "SESSION_SETUP" 0 "SUPPORTED_APP_PROTOCOL" ;
VAL_ 1294 CP_a073_ccsManagerState 7 "PAUSED" 6 "FAULTED" 5 "SHUTDOWN" 4 "CHARGE_PROCESS" 3 "CONTRACT_AUTH" 2 "SETUP" 1 "CONNECTED" 0 "DISCONNECTED" ;
VAL_ 1294 CP_a073_ccsDcState 8 "FAULTED" 7 "WAIT_RESTART" 6 "END_OF_CHARGE" 5 "SHUTDOWN" 4 "ENABLED" 3 "PRECHARGE" 2 "CABLE_CHECK" 1 "CHARGE_PARAM_DISCOVERY" 0 "IDLE" ;
VAL_ 1294 CP_a073_ccsShutdownReason 13 "COUNT" 12 "INTERNAL_FAULT_REQUEST" 11 "EMERGENCY_SHUTDOWN" 10 "CHARGE_TYPE_FAULT" 9 "LIVE_DISCONNECT" 8 "INVALID_SERVICE_OPTION" 7 "COMMS_LOST_NO_PILOT" 6 "COMMS_LOST_PILOT_PRESENT" 5 "CHARGE_TYPE_SHUTDOWN" 4 "EVSE_SHUTDOWN_REQUEST" 3 "BMS_SHUTDOWN_REQUEST" 2 "INTERNAL_SHUTDOWN_REQUEST" 1 "SAFE_DISCONNECT" 0 "NONE" ;
VAL_ 1294 CP_a074_slacState 14 "NUM_STATES" 13 "WAIT_FOR_RETRY" 12 "FAILED" 11 "JOINED" 10 "MATCHED" 9 "WAIT_FOR_SET_KEY_CNF" 8 "WAIT_FOR_MATCH_CNF" 7 "FIND_MATCH" 6 "WAIT_FOR_ATTEN_CHAR" 5 "SEND_MSOUNDS" 4 "SEND_START_ATTEN" 3 "WAIT_FOR_PARM_CNF" 2 "IDLE" 1 "DISCONNECTED" 0 "INIT" ;
VAL_ 1294 CP_a074_slacErrorCode 8 "NO_CABLE" 7 "NO_PILOT" 6 "NO_SET_KEY_CNF" 5 "NO_MATCH_CNF" 4 "NO_EVSE_FOUND" 3 "NO_ATTEN_CHAR" 2 "NO_PARM_CNF" 1 "FAST_CHARGE_PILOT_NO_PROX" 0 "NO_ERROR" ;
VAL_ 1294 CP_a075_evccState 6 "COMMS_FAULT" 5 "COMMS_PAUSED" 4 "COMMS_SHUTDOWN" 3 "COMMS_TIMEOUT" 2 "COMMS_ESTABLISHED" 1 "WAIT_FOR_HANDSHAKE" 0 "INIT" ;
VAL_ 1294 CP_a075_currentMessage 15 "NUM_MSG" 14 "MSG_NONE" 13 "SESSION_STOP" 12 "WELDING_DETECTION" 11 "POWER_DELIVERY_END" 10 "CURRENT_DEMAND" 9 "POWER_DELIVERY_START" 8 "PRECHARGE" 7 "CABLE_CHECK" 6 "CHARGE_PARAMETER_DISCOVERY" 5 "CONTRACT_AUTHENTICATION" 4 "PAYMENT_DETAILS" 3 "SERVICE_PAYMENT_SELECTION" 2 "SERVICE_DISCOVERY" 1 "SESSION_SETUP" 0 "SUPPORTED_APP_PROTOCOL" ;
VAL_ 1294 CP_a075_initFailureType 3 "TLS_HANDSHAKE" 2 "SOCKET_OPTIONS" 1 "TCP_CONNECT" 0 "EVCC_NO_FAILURE" ;
VAL_ 1294 CP_a078_VC_tempAmbientFiltered 0 "SNA" ;
VAL_ 1294 CP_a078_pinTemperature1 255 "SNA" ;
VAL_ 1294 CP_a078_pinTemperature2 255 "SNA" ;
VAL_ 1294 CP_a078_pinTemperature3 255 "SNA" ;
VAL_ 1294 CP_a079_VC_tempAmbientFiltered 0 "SNA" ;
VAL_ 1294 CP_a079_pinTemperature1 255 "SNA" ;
VAL_ 1294 CP_a079_pinTemperature2 255 "SNA" ;
VAL_ 1294 CP_a079_pinTemperature3 255 "SNA" ;
VAL_ 1294 CP_a089_gtwPlcSupportType 2 "NATIVE_CHARGE_PORT" 1 "GEN3_EU_CP" 0 "NONE" ;
VAL_ 1294 CP_a090_evseIsoStatus 4 "NO_IMD" 3 "FAULT" 2 "WARNING" 1 "VALID" 0 "INVALID" ;
VAL_ 1294 CP_a090_ccsDcState 8 "FAULTED" 7 "WAIT_RESTART" 6 "END_OF_CHARGE" 5 "SHUTDOWN" 4 "ENABLED" 3 "PRECHARGE" 2 "CABLE_CHECK" 1 "CHARGE_PARAM_DISCOVERY" 0 "IDLE" ;
VAL_ 1294 CP_a091_fcType 7 "SNA" 6 "OTHER" 5 "MC_EVSE" 4 "COMBO" 3 "CC_EVSE" 2 "GB" 1 "CHADEMO" 0 "SUPERCHARGER" ;
VAL_ 1294 CP_a095_fcType 7 "SNA" 6 "OTHER" 5 "MC_EVSE" 4 "COMBO" 3 "CC_EVSE" 2 "GB" 1 "CHADEMO" 0 "SUPERCHARGER" ;
VAL_ 1294 CP_a095_fcBrand 1 "TESLA" 0 "SNA" ;
VAL_ 1294 CP_a099_proximity 3 "LATCHED" 2 "UNLATCHED" 1 "DISCONNECTED" 0 "SNA" ;
VAL_ 1294 CP_a099_pilot 7 "SNA" 6 "UNUSED_6" 5 "INVALID" 4 "IDLE" 3 "FAST_CHARGE" 2 "LINE_CHARGE" 1 "FAULTED" 0 "NONE" ;
VAL_ 1294 CP_a110_thermalVelocity 511 "SNA" ;
VAL_ 1294 CP_a111_heaterTemperature 255 "SNA" ;
VAL_ 1294 CP_a111_VC_tempAmbientFiltered 0 "SNA" ;
VAL_ 1294 CP_a112_heaterTemperature 255 "SNA" ;
VAL_ 1294 CP_a113_heaterTemperature 255 "SNA" ;
VAL_ 1294 CP_a117_heaterTemperature 255 "SNA" ;
VAL_ 1294 CP_a117_averageError 255 "SNA" ;
VAL_ 1294 CP_a120_dcPinTemp 255 "SNA" ;
VAL_ 1294 CP_a124_ivledState 3 "FADING_OUT" 2 "ON" 1 "FADING_IN" 0 "OFF" ;
VAL_ 1294 CP_a129_bldcDriverState 3 "READY" 2 "I2C_ERROR" 1 "INIT" 0 "UNPOWERED" ;
VAL_ 1294 CP_a131_chargeProtocol 6 "CHADEMO" 5 "GBDC" 4 "IEC_COMBO_AC" 3 "IEC_COMBO_DC" 2 "SUPERCHARGER" 1 "AC_CHARGE" 0 "NO_CHARGE" ;
VAL_ 1294 CP_a135_sdpErr 4 "NUM_OF_ERRS" 3 "ERR_INVALID_DATA" 2 "ERR_NO_RX_DATA" 1 "ERR_INVALID_ARG" 0 "ERR_NONE" ;
VAL_ 1294 CP_a135_pilotState 7 "SNA" 6 "UNUSED_6" 5 "INVALID" 4 "IDLE" 3 "FAST_CHARGE" 2 "LINE_CHARGE" 1 "FAULTED" 0 "NONE" ;
VAL_ 1294 CP_a138_FC_type 7 "SNA" 6 "OTHER" 5 "MC_EVSE" 4 "COMBO" 3 "CC_EVSE" 2 "GB" 1 "CHADEMO" 0 "SUPERCHARGER" ;
VAL_ 1294 CP_a138_latchState 3 "BLOCKING" 2 "ENGAGED" 1 "DISENGAGED" 0 "SNA" ;
VAL_ 1294 CP_a138_CP_proximity 3 "LATCHED" 2 "UNLATCHED" 1 "DISCONNECTED" 0 "SNA" ;
VAL_ 1294 CP_a139_latchState 3 "BLOCKING" 2 "ENGAGED" 1 "DISENGAGED" 0 "SNA" ;
VAL_ 1294 CP_a139_CP_proximity 3 "LATCHED" 2 "UNLATCHED" 1 "DISCONNECTED" 0 "SNA" ;
VAL_ 1294 CP_a140_latchState 3 "BLOCKING" 2 "ENGAGED" 1 "DISENGAGED" 0 "SNA" ;
VAL_ 1294 CP_a140_CP_proximity 3 "LATCHED" 2 "UNLATCHED" 1 "DISCONNECTED" 0 "SNA" ;
VAL_ 1294 CP_a141_latchState 3 "BLOCKING" 2 "ENGAGED" 1 "DISENGAGED" 0 "SNA" ;
VAL_ 1294 CP_a141_CP_proximity 3 "LATCHED" 2 "UNLATCHED" 1 "DISCONNECTED" 0 "SNA" ;
VAL_ 1294 CP_a146_v2gMessage 15 "NUM_MSG" 14 "MSG_NONE" 13 "SESSION_STOP" 12 "WELDING_DETECTION" 11 "POWER_DELIVERY_END" 10 "CURRENT_DEMAND" 9 "POWER_DELIVERY_START" 8 "PRECHARGE" 7 "CABLE_CHECK" 6 "CHARGE_PARAMETER_DISCOVERY" 5 "CONTRACT_AUTHENTICATION" 4 "PAYMENT_DETAILS" 3 "SERVICE_PAYMENT_SELECTION" 2 "SERVICE_DISCOVERY" 1 "SESSION_SETUP" 0 "SUPPORTED_APP_PROTOCOL" ;
VAL_ 1294 CP_a153_acPinTempVelocity 511 "SNA" ;
VAL_ 1294 CP_a153_acPinTemp1 255 "SNA" ;
VAL_ 1294 CP_a153_acPinTemp2 255 "SNA" ;
VAL_ 1294 CP_a154_acPinTempVelocity 511 "SNA" ;
VAL_ 1294 CP_a154_acPinTemp1 255 "SNA" ;
VAL_ 1294 CP_a154_acPinTemp2 255 "SNA" ;
VAL_ 1294 CP_a163_cover1State 5 "SNA" 4 "SHORT_TO_VBAT" 3 "SHORT_TO_GND" 2 "OPEN" 1 "CLOSED" 0 "BOOT_UP_CLOSED" ;
VAL_ 1294 CP_a163_cover2State 5 "SNA" 4 "SHORT_TO_VBAT" 3 "SHORT_TO_GND" 2 "OPEN" 1 "CLOSED" 0 "BOOT_UP_CLOSED" ;
VAL_ 1294 CP_a164_VC_tempAmbientFiltered 0 "SNA" ;
VAL_ 1294 CP_a164_minInternalPinTemp 255 "SNA" ;
VAL_ 1294 CP_a173_cover1State 5 "SNA" 4 "SHORT_TO_VBAT" 3 "SHORT_TO_GND" 2 "OPEN" 1 "CLOSED" 0 "BOOT_UP_CLOSED" ;
VAL_ 1294 CP_a173_cover2State 5 "SNA" 4 "SHORT_TO_VBAT" 3 "SHORT_TO_GND" 2 "OPEN" 1 "CLOSED" 0 "BOOT_UP_CLOSED" ;
VAL_ 798 CP_matrixIndex 3 "AlertMatrix3" 2 "AlertMatrix2" 1 "AlertMatrix1" 0 "AlertMatrix0" ;
VAL_ 1085 CP_hvChargeStatus_log 6 "CHARGE_FAULTED" 5 "CHARGE_ENABLED" 4 "EVSE_TEST_PASSED" 3 "EXT_EVSE_TEST_ACTIVE" 2 "CHARGE_STANDBY" 1 "CHARGE_CONNECTED" 0 "CHARGE_INACTIVE" ;
VAL_ 1085 CP_chargeShutdownRequest_log 2 "EMERGENCY_SHUTDOWN_REQUESTED" 1 "GRACEFUL_SHUTDOWN_REQUESTED" 0 "NO_SHUTDOWN_REQUESTED" ;
VAL_ 1085 CP_evseChargeType_log 2 "AC_CHARGER_PRESENT" 1 "DC_CHARGER_PRESENT" 0 "NO_CHARGER_PRESENT" ;
VAL_ 1085 CP_chgLimitMode_log 5 "NUM" 4 "DEBUG_OVERRIDE" 3 "ADAPTER_FOLDBACK" 2 "THERMAL_FOLDBACK" 1 "CABLE_UNSECURED" 0 "HW" ;
VAL_ 541 CP_proximity 3 "CHG_PROXIMITY_LATCHED" 2 "CHG_PROXIMITY_UNLATCHED" 1 "CHG_PROXIMITY_DISCONNECTED" 0 "CHG_PROXIMITY_SNA" ;
VAL_ 541 CP_pilot 7 "CHG_PILOT_SNA" 6 "CHG_PILOT_UNUSED_6" 5 "CHG_PILOT_INVALID" 4 "CHG_PILOT_IDLE" 3 "CHG_PILOT_FAST_CHARGE" 2 "CHG_PILOT_LINE_CHARGE" 1 "CHG_PILOT_FAULTED" 0 "CHG_PILOT_NONE" ;
VAL_ 541 CP_cableType 5 "CHG_CABLE_TYPE_SNA" 4 "CHG_CABLE_TYPE_MCS" 3 "CHG_CABLE_TYPE_GB_DC" 2 "CHG_CABLE_TYPE_GB_AC" 1 "CHG_CABLE_TYPE_SAE" 0 "CHG_CABLE_TYPE_IEC" ;
VAL_ 541 CP_iecPilotState 9 "IEC_PILOT_SNA" 8 "IEC_PILOT_NUM" 7 "IEC_PILOT_F" 6 "IEC_PILOT_E" 5 "IEC_PILOT_C3" 4 "IEC_PILOT_C2" 3 "IEC_PILOT_C1" 2 "IEC_PILOT_B3" 1 "IEC_PILOT_B2" 0 "IEC_PILOT_B1" ;
VAL_ 541 CP_teslaSwcanState 8 "TESLA_SWCAN_V2L_ESTABLISHED" 7 "TESLA_SWCAN_V2L_RECEIVE" 6 "TESLA_SWCAN_OFFBOARD_UPDATE_IN_PROGRESS" 5 "TESLA_SWCAN_GO_TO_SLEEP" 4 "TESLA_SWCAN_FAULT" 3 "TESLA_SWCAN_ESTABLISHED" 2 "TESLA_SWCAN_RECEIVE" 1 "TESLA_SWCAN_ACCEPT" 0 "TESLA_SWCAN_INACTIVE" ;
VAL_ 541 CP_evseChargeType_UI 2 "AC_CHARGER_PRESENT" 1 "DC_CHARGER_PRESENT" 0 "NO_CHARGER_PRESENT" ;
VAL_ 541 CP_gbState 15 "GBDC_TESTER_PRESENT" 14 "GBDC_FAULTED" 13 "GBDC_RETRY_CHARGE" 12 "GBDC_ERROR_HANDLING" 11 "GBDC_END_OF_CHARGE" 10 "GBDC_CHARGE_DISABLING" 9 "GBDC_STOP_CHARGE_REQUESTED" 8 "GBDC_CHARGING" 7 "GBDC_READY_TO_CHARGE" 6 "GBDC_VEH_PACK_PRECHARGE" 5 "GBDC_CHARGE_PARAM_CONFIG" 4 "GBDC_RECOGNITION" 3 "GBDC_HANDSHAKING_EXT_ISO" 2 "GBDC_COMMS_RECEIVED" 1 "GBDC_WAIT_FOR_COMMS" 0 "GBDC_INACTIVE" ;
VAL_ 541 CP_gbdcStopChargeReason 8 "GBDC_PARAM_MISMATCH" 7 "GBDC_SUPERCHARGER_COMMS_TIMEOUT" 6 "GBDC_LIVE_DISCONNECT" 5 "GBDC_EVSE_CRITICAL_FAULT" 4 "GBDC_EVSE_FAULT" 3 "GBDC_COMMS_TIMEOUT" 2 "GBDC_EVSE_REQUESTED" 1 "GBDC_VEH_REQUESTED" 0 "GBDC_STOP_REASON_NONE" ;
VAL_ 541 CP_gbdcFailureReason 3 "GBDC_CRITICAL_FAILURE" 2 "GBDC_SHUTDOWN_FAILURE" 1 "GBDC_ATTEMPTS_EXPIRED" 0 "GBDC_FAILURE_NONE" ;
VAL_ 541 CP_acChargeState 6 "AC_CHARGE_FAULT" 5 "AC_CHARGE_VEH_SHUTDOWN" 4 "AC_CHARGE_ONBOARD_CHARGER_SHUTDOWN" 3 "AC_CHARGE_ENABLED" 2 "AC_CHARGE_STANDBY" 1 "AC_CHARGE_CONNECTED_CHARGE_BLOCKED" 0 "AC_CHARGE_INACTIVE" ;
VAL_ 541 CP_teslaDcState 10 "TESLA_DC_FAULT" 9 "TESLA_DC_EMERGENCY_SHUTDOWN" 8 "TESLA_DC_VEH_SHUTDOWN" 7 "TESLA_DC_EVSE_SHUTDOWN" 6 "TESLA_DC_ENABLED" 5 "TESLA_DC_EXT_PRECHARGE_ACTIVE" 4 "TESLA_DC_EXT_TEST_ACTIVE" 3 "TESLA_DC_EXT_TESTS_ENABLED" 2 "TESLA_DC_STANDBY" 1 "TESLA_DC_CONNECTED_CHARGE_BLOCKED" 0 "TESLA_DC_INACTIVE" ;
VAL_ 1885 CP_loggingFastSelect 5 "5" 4 "4" 3 "3" 2 "2" 1 "1" 0 "0" ;
VAL_ 1885 CP_chargeCablePresent 1 "CABLE_PRESENT" 0 "CABLE_NOT_PRESENT" ;
VAL_ 1885 CP_UHF_controlState 10 "CP_UHF_FAULT" 9 "CP_UHF_SLEEP" 8 "CP_UHF_HANDLE_FOUND" 7 "CP_UHF_READ_RXFIFO" 6 "CP_UHF_CHECK_RX" 5 "CP_UHF_RX" 4 "CP_UHF_PREPARE_RX" 3 "CP_UHF_CALIBRATE" 2 "CP_UHF_IDLE" 1 "CP_UHF_CONFIG" 0 "CP_UHF_INIT" ;
VAL_ 1885 CP_doorOpenRequest 8 "CPD_OPEN_REQ_NUM" 7 "CPD_OPEN_REQ_CABLE_RECONNECTED" 6 "CPD_OPEN_REQ_VCFRONT" 5 "CPD_OPEN_REQ_CLOSING_FAILED" 4 "CPD_OPEN_REQ_PUSH_TO_OPEN" 3 "CPD_OPEN_REQ_UHF" 2 "CPD_OPEN_REQ_SEC" 1 "CPD_OPEN_REQ_UI" 0 "CPD_OPEN_REQ_NONE" ;
VAL_ 1885 CP_doorOpenEndOfDriveReason 7 "CP_STOP_DRIVE_REASON_OVERCURRENT" 6 "CP_STOP_DRIVE_REASON_REQ_OVERRIDE" 5 "CP_STOP_DRIVE_REASON_ABSOLUTE_TIMEOUT" 4 "CP_STOP_DRIVE_REASON_MAX_TARGET_V" 3 "CP_STOP_DRIVE_REASON_REACHED_STOP" 2 "CP_STOP_DRIVE_REASON_STOPPED_MOVING_TIMEOUT" 1 "CP_STOP_DRIVE_REASON_STALLED" 0 "CP_STOP_DRIVE_REASON_NONE" ;
VAL_ 1885 CP_doorCloseEndOfDriveReason 7 "CP_STOP_DRIVE_REASON_OVERCURRENT" 6 "CP_STOP_DRIVE_REASON_REQ_OVERRIDE" 5 "CP_STOP_DRIVE_REASON_ABSOLUTE_TIMEOUT" 4 "CP_STOP_DRIVE_REASON_MAX_TARGET_V" 3 "CP_STOP_DRIVE_REASON_REACHED_STOP" 2 "CP_STOP_DRIVE_REASON_STOPPED_MOVING_TIMEOUT" 1 "CP_STOP_DRIVE_REASON_STALLED" 0 "CP_STOP_DRIVE_REASON_NONE" ;
VAL_ 1885 CP_doorCloseRequest 16 "CPD_CLOSE_REQ_NUM" 15 "CPD_CLOSE_REQ_COVER_OPEN" 14 "CPD_CLOSE_REQ_VCFRONT" 13 "CPD_CLOSE_REQ_OPEN_ON_WAKE" 12 "CPD_CLOSE_REQ_SENSOR_COMMS_RECOVERED" 11 "CPD_CLOSE_REQ_SENSOR_MISMATCH" 10 "CPD_CLOSE_REQ_INITIAL_CINCH" 9 "CPD_CLOSE_REQ_OPENED_IN_DRIVE_STATE" 8 "CPD_CLOSE_REQ_ENTER_DRIVE" 7 "CPD_CLOSE_REQ_FAULT_LINE" 6 "CPD_CLOSE_REQ_CAR_WASH" 5 "CPD_CLOSE_REQ_PUSH_TO_CLOSE" 4 "CPD_CLOSE_REQ_SEC" 3 "CPD_CLOSE_REQ_UI" 2 "CPD_CLOSE_REQ_DOOR_OPEN_TIMEOUT" 1 "CPD_CLOSE_REQ_CABLE_UNPLUGGED" 0 "CPD_CLOSE_REQ_NONE" ;
VAL_ 1885 CP_latchDisengagingStopReason 7 "CP_STOP_DRIVE_REASON_OVERCURRENT" 6 "CP_STOP_DRIVE_REASON_REQ_OVERRIDE" 5 "CP_STOP_DRIVE_REASON_ABSOLUTE_TIMEOUT" 4 "CP_STOP_DRIVE_REASON_MAX_TARGET_V" 3 "CP_STOP_DRIVE_REASON_REACHED_STOP" 2 "CP_STOP_DRIVE_REASON_STOPPED_MOVING_TIMEOUT" 1 "CP_STOP_DRIVE_REASON_STALLED" 0 "CP_STOP_DRIVE_REASON_NONE" ;
VAL_ 1885 CP_latchEngagingStopReason 7 "CP_STOP_DRIVE_REASON_OVERCURRENT" 6 "CP_STOP_DRIVE_REASON_REQ_OVERRIDE" 5 "CP_STOP_DRIVE_REASON_ABSOLUTE_TIMEOUT" 4 "CP_STOP_DRIVE_REASON_MAX_TARGET_V" 3 "CP_STOP_DRIVE_REASON_REACHED_STOP" 2 "CP_STOP_DRIVE_REASON_STOPPED_MOVING_TIMEOUT" 1 "CP_STOP_DRIVE_REASON_STALLED" 0 "CP_STOP_DRIVE_REASON_NONE" ;
VAL_ 1885 CP_doorIdDetectionState 2 "DOOR_ID_VALID" 1 "DOOR_ID_INVALID" 0 "DOOR_ID_UNKNOWN_SNA" ;
VAL_ 1885 CP_doorIdDetectedBin 3 "DOOR_ID_BIN_OPAL" 2 "DOOR_ID_BIN_HMC" 1 "DOOR_ID_BIN_NMB" 0 "DOOR_ID_BIN_UNKNOWN" ;
VAL_ 2042 CP_loggingSlowSelect 7 "7" 6 "6" 5 "5" 4 "4" 3 "3" 2 "2" 1 "1" 0 "0" ;
VAL_ 2042 CP_inlet1HarnessIdState 2 "HARNESS_PEDIGREE_VALID" 1 "HARNESS_PEDIGREE_INVALID" 0 "HARNESS_PEDIGREE_UNKNOWN_SNA" ;
VAL_ 2042 CP_inlet2HarnessIdState 2 "HARNESS_PEDIGREE_VALID" 1 "HARNESS_PEDIGREE_INVALID" 0 "HARNESS_PEDIGREE_UNKNOWN_SNA" ;
VAL_ 2042 CP_inletHeaterState 3 "INLET_HEATER_FAULTED" 2 "INLET_HEATER_ENABLED_LOWTEMP" 1 "INLET_HEATER_ENABLED_HIGHTEMP" 0 "INLET_HEATER_DISABLED" ;
VAL_ 2042 CP_doorOpenLimiterMaxRequestType 8 "CPD_OPEN_REQ_NUM" 7 "CPD_OPEN_REQ_CABLE_RECONNECTED" 6 "CPD_OPEN_REQ_VCFRONT" 5 "CPD_OPEN_REQ_CLOSING_FAILED" 4 "CPD_OPEN_REQ_PUSH_TO_OPEN" 3 "CPD_OPEN_REQ_UHF" 2 "CPD_OPEN_REQ_SEC" 1 "CPD_OPEN_REQ_UI" 0 "CPD_OPEN_REQ_NONE" ;
VAL_ 2042 CP_doorCloseLimiterMaxRequestTyp 16 "CPD_CLOSE_REQ_NUM" 15 "CPD_CLOSE_REQ_COVER_OPEN" 14 "CPD_CLOSE_REQ_VCFRONT" 13 "CPD_CLOSE_REQ_OPEN_ON_WAKE" 12 "CPD_CLOSE_REQ_SENSOR_COMMS_RECOVERED" 11 "CPD_CLOSE_REQ_SENSOR_MISMATCH" 10 "CPD_CLOSE_REQ_INITIAL_CINCH" 9 "CPD_CLOSE_REQ_OPENED_IN_DRIVE_STATE" 8 "CPD_CLOSE_REQ_ENTER_DRIVE" 7 "CPD_CLOSE_REQ_FAULT_LINE" 6 "CPD_CLOSE_REQ_CAR_WASH" 5 "CPD_CLOSE_REQ_PUSH_TO_CLOSE" 4 "CPD_CLOSE_REQ_SEC" 3 "CPD_CLOSE_REQ_UI" 2 "CPD_CLOSE_REQ_DOOR_OPEN_TIMEOUT" 1 "CPD_CLOSE_REQ_CABLE_UNPLUGGED" 0 "CPD_CLOSE_REQ_NONE" ;
